VERSION ""

NS_ :

BS_:

BU_: BMS ECC EVBUS_Virtual_ECU GW OBC VCU

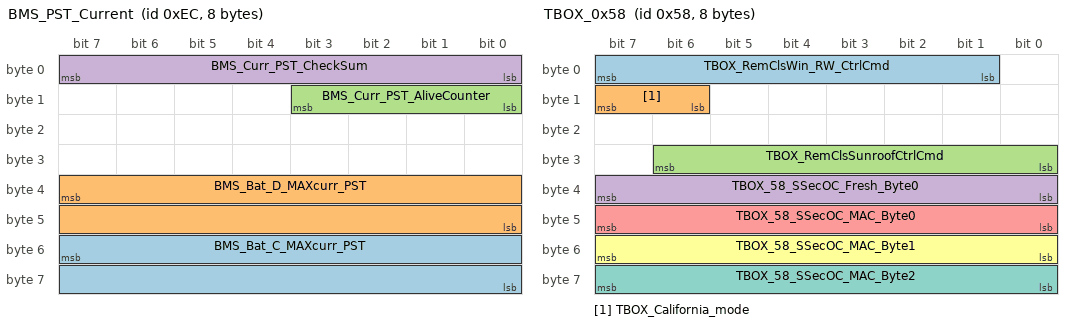
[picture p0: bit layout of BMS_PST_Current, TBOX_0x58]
BO_ 236 BMS_PST_Current: 8 BMS
 SG_ BMS_Bat_C_MAXcurr_PST : 55|16@0+ (0.05,0) [0|3276.75] "A"  VCU,GW
 SG_ BMS_Bat_D_MAXcurr_PST : 39|16@0+ (0.05,0) [0|3276.75] "A"  VCU,GW
 SG_ BMS_Curr_PST_AliveCounter : 11|4@0+ (1,0) [0|14] ""  VCU,GW
 SG_ BMS_Curr_PST_CheckSum : 7|8@0+ (1,0) [0|255] ""  VCU,GW

BO_ 54 TBOX_0x36: 8 GW
 SG_ TBOX_RemSeekCarCtrlCmd : 3|2@0+ (1,0) [0|3] ""  EVBUS_Virtual_ECU
 SG_ TBOX_RemClsTrCmd : 9|2@0+ (1,0) [0|3] ""  EVBUS_Virtual_ECU
 SG_ TBOX_RemDrvrSeatVentnCmd : 12|3@0+ (1,0) [0|7] ""  EVBUS_Virtual_ECU
 SG_ TBOX_RemDrvrSeatHeatgCmd : 15|3@0+ (1,0) [0|7] ""  EVBUS_Virtual_ECU
 SG_ TBOX_RemSetWelFct : 17|2@0+ (1,0) [0|3] ""  EVBUS_Virtual_ECU
 SG_ TBOX_RemPassSeatVentnCmd : 20|3@0+ (1,0) [0|7] ""  EVBUS_Virtual_ECU
 SG_ TBOX_RemPassSeatHeatgCmd : 23|3@0+ (1,0) [0|7] ""  EVBUS_Virtual_ECU
 SG_ TBOX_ClsAVMFct_ICC : 27|1@0+ (1,0) [0|1] ""  EVBUS_Virtual_ECU
 SG_ TBOX_ClsRemAVMFct_AVAP : 28|1@0+ (1,0) [0|1] ""  EVBUS_Virtual_ECU
 SG_ TBOX_RemSetFolwMeFct_BCM : 31|3@0+ (1,0) [0|7] ""  EVBUS_Virtual_ECU
 SG_ TBOX_RemSetCtrlLockFct_PKC : 33|2@0+ (1,0) [0|3] ""  EVBUS_Virtual_ECU
 SG_ TBOX_RemSetKickSnsrFct : 35|2@0+ (1,0) [0|3] ""  EVBUS_Virtual_ECU
 SG_ TBOX_VideoCtrlReq : 38|3@0+ (1,0) [0|7] ""  EVBUS_Virtual_ECU
 SG_ TBOX_VoiceBlowerLimReq : 39|1@0+ (1,0) [0|1] ""  ECC
 SG_ TBOX_RemCtrlCmdFb : 41|2@0+ (1,0) [0|3] ""  EVBUS_Virtual_ECU
 SG_ TBOX_CtrlReMirrReq : 43|2@0+ (1,0) [0|3] ""  EVBUS_Virtual_ECU
 SG_ TBOX_eCallMuteSt : 45|2@0+ (1,0) [0|3] ""  EVBUS_Virtual_ECU
 SG_ TBOX_RemReScrnHeatgCmd : 47|2@0+ (1,0) [0|3] ""  EVBUS_Virtual_ECU
 SG_ TBOX_eCallSt : 58|3@0+ (1,0) [0|7] ""  EVBUS_Virtual_ECU

BO_ 88 TBOX_0x58: 8 GW
 SG_ TBOX_RemClsWin_RW_CtrlCmd : 7|7@0+ (1,0) [0|100] "%"  EVBUS_Virtual_ECU
 SG_ TBOX_California_mode : 15|2@0+ (1,0) [0|3] ""  ECC
 SG_ TBOX_RemClsSunroofCtrlCmd : 30|7@0+ (1,0) [0|100] "%"  EVBUS_Virtual_ECU
 SG_ TBOX_58_SSecOC_Fresh_Byte0 : 39|8@0+ (1,0) [0|255] ""  EVBUS_Virtual_ECU
 SG_ TBOX_58_SSecOC_MAC_Byte0 : 47|8@0+ (1,0) [0|255] ""  EVBUS_Virtual_ECU
 SG_ TBOX_58_SSecOC_MAC_Byte1 : 55|8@0+ (1,0) [0|255] ""  EVBUS_Virtual_ECU
 SG_ TBOX_58_SSecOC_MAC_Byte2 : 63|8@0+ (1,0) [0|255] ""  EVBUS_Virtual_ECU

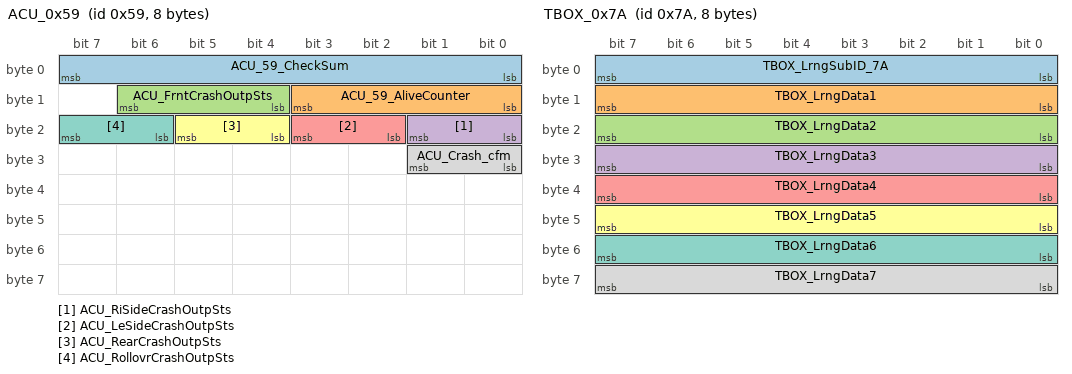
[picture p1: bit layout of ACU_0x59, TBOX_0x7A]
BO_ 89 ACU_0x59: 8 GW
 SG_ ACU_59_CheckSum : 7|8@0+ (1,0) [0|255] ""  BMS,ECC,OBC
 SG_ ACU_59_AliveCounter : 11|4@0+ (1,0) [0|14] ""  BMS,ECC,OBC
 SG_ ACU_FrntCrashOutpSts : 14|3@0+ (1,0) [0|7] ""  BMS,ECC,OBC
 SG_ ACU_RiSideCrashOutpSts : 17|2@0+ (1,0) [0|3] ""  BMS,ECC,OBC
 SG_ ACU_LeSideCrashOutpSts : 19|2@0+ (1,0) [0|3] ""  BMS,ECC,OBC
 SG_ ACU_RearCrashOutpSts : 21|2@0+ (1,0) [0|3] ""  BMS,ECC,OBC
 SG_ ACU_RollovrCrashOutpSts : 23|2@0+ (1,0) [0|3] ""  BMS,ECC,OBC
 SG_ ACU_Crash_cfm : 25|2@0+ (1,0) [0|3] ""  BMS,ECC,OBC

BO_ 121 TBOX_0x79: 8 GW
 SG_ TBOX_LrnFbInfoClassn : 7|8@0+ (1,0) [0|255] ""  EVBUS_Virtual_ECU
 SG_ TBOX_LrngSts : 15|8@0+ (1,0) [0|255] ""  EVBUS_Virtual_ECU

BO_ 122 TBOX_0x7A: 8 GW
 SG_ TBOX_LrngSubID_7A : 7|8@0+ (1,0) [0|255] ""  EVBUS_Virtual_ECU
 SG_ TBOX_LrngData1 : 15|8@0+ (1,0) [0|255] ""  EVBUS_Virtual_ECU
 SG_ TBOX_LrngData2 : 23|8@0+ (1,0) [0|255] ""  EVBUS_Virtual_ECU
 SG_ TBOX_LrngData3 : 31|8@0+ (1,0) [0|255] ""  EVBUS_Virtual_ECU
 SG_ TBOX_LrngData4 : 39|8@0+ (1,0) [0|255] ""  EVBUS_Virtual_ECU
 SG_ TBOX_LrngData5 : 47|8@0+ (1,0) [0|255] ""  EVBUS_Virtual_ECU
 SG_ TBOX_LrngData6 : 55|8@0+ (1,0) [0|255] ""  EVBUS_Virtual_ECU
 SG_ TBOX_LrngData7 : 63|8@0+ (1,0) [0|255] ""  EVBUS_Virtual_ECU

BO_ 147 VCU_0x93: 16 VCU
 SG_ VCU_93_CheckSum : 7|8@0+ (1,0) [0|255] ""  BMS,GW
 SG_ VCU_93_AliveCounter : 11|4@0+ (1,0) [0|14] ""  BMS,GW
 SG_ VCU_EmgyShutOff : 12|1@0+ (1,0) [0|1] ""  BMS,GW
 SG_ VCU_IsolationMonitor_Rq : 13|1@0+ (1,0) [0|1] ""  BMS,GW
 SG_ VCU_Set_Chrg_Mod : 19|4@0+ (1,0) [0|15] ""  BMS,GW
 SG_ VCU_Set_BMS_Mod : 23|4@0+ (1,0) [0|15] ""  BMS,GW
 SG_ VCU_HVBActivateDeactivateRq : 35|4@0+ (1,0) [0|15] ""  BMS,GW
 SG_ VCU_Set_Balc_Mod : 39|4@0+ (1,0) [0|15] ""  BMS,GW
 SG_ VCU_93_SSecOC_Fresh_Byte0 : 71|8@0+ (1,0) [0|255] ""  BMS,GW
 SG_ VCU_93_SSecOC_MAC_Byte0 : 79|8@0+ (1,0) [0|255] ""  BMS,GW
 SG_ VCU_93_SSecOC_MAC_Byte1 : 87|8@0+ (1,0) [0|255] ""  BMS,GW
 SG_ VCU_93_SSecOC_MAC_Byte2 : 95|8@0+ (1,0) [0|255] ""  BMS,GW

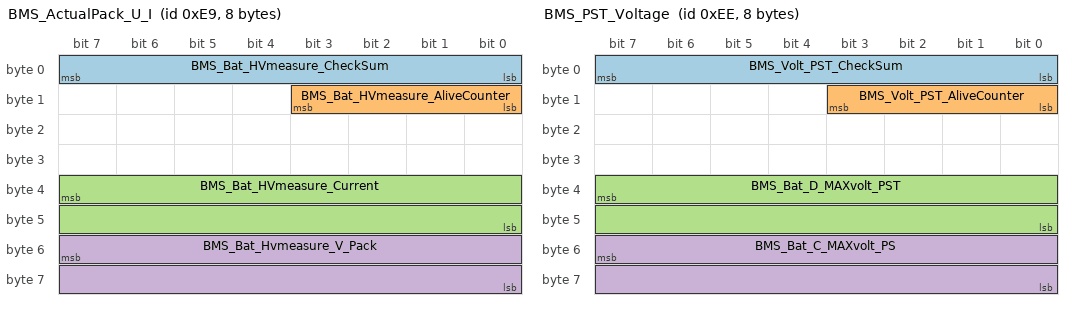
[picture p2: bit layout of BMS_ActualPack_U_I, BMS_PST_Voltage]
BO_ 233 BMS_ActualPack_U_I: 8 BMS
 SG_ BMS_Bat_HVmeasure_CheckSum : 7|8@0+ (1,0) [0|255] ""  GW,VCU
 SG_ BMS_Bat_HVmeasure_AliveCounter : 11|4@0+ (1,0) [0|14] ""  GW,VCU
 SG_ BMS_Bat_HVmeasure_Current : 39|16@0- (0.05,0) [-1250|1250] "A"  ECC,GW,VCU
 SG_ BMS_Bat_Hvmeasure_V_Pack : 55|16@0+ (0.01,0) [0|655.35] "V"  GW,VCU

BO_ 235 BMS_HVBatt_Status_Errors_1: 8 BMS
 SG_ BMS_Critical_Error_Flg_CheckSum : 7|8@0+ (1,0) [0|255] ""  GW,VCU
 SG_ BMS_Critical_Error_Flg_AliveCoun : 11|4@0+ (1,0) [0|14] ""  GW,VCU
 SG_ BMS_ErrorWarning_OverChargeCurre : 12|1@0+ (1,0) [0|1] ""  GW,VCU
 SG_ BMS_ErrorActive_OverChargeCurren : 13|1@0+ (1,0) [0|1] ""  GW,VCU
 SG_ BMS_ErrorWarning_OverDischargeCu : 14|1@0+ (1,0) [0|1] ""  GW,VCU
 SG_ BMS_ErrorActive_OverDischargeCur : 15|1@0+ (1,0) [0|1] ""  GW,VCU
 SG_ BMS_ErrorWarning_ChargePowerLimi : 16|1@0+ (1,0) [0|1] ""  GW,VCU
 SG_ BMS_ErrorActive_ChargePowerLimit : 17|1@0+ (1,0) [0|1] ""  GW,VCU
 SG_ BMS_ErrorWarning_DischargePowerL : 18|1@0+ (1,0) [0|1] ""  GW,VCU
 SG_ BMS_ErrorActive_DischargePowerLi : 19|1@0+ (1,0) [0|1] ""  GW,VCU
 SG_ BMS_ErrorWarning_SOC_Low : 20|1@0+ (1,0) [0|1] ""  GW,VCU
 SG_ BMS_ErrorActive_SOC_Low : 21|1@0+ (1,0) [0|1] ""  GW,VCU
 SG_ BMS_ErrorWarning_Iso : 22|1@0+ (1,0) [0|1] ""  GW,VCU
 SG_ BMS_ErrorActive_Iso_Crit : 23|1@0+ (1,0) [0|1] ""  GW,VCU
 SG_ BMS_ErrorActive_AbsChargeCurrent : 24|1@0+ (1,0) [0|1] ""  GW,VCU
 SG_ BMS_ErrorActive_AbsDischargeCurr : 25|1@0+ (1,0) [0|1] ""  GW,VCU
 SG_ BMS_ErrorActive_AbsChargePowerLi : 26|1@0+ (1,0) [0|1] ""  GW,VCU
 SG_ BMS_ErrorActive_AbsDischargePowe : 27|1@0+ (1,0) [0|1] ""  GW,VCU
 SG_ BMS_ErrorWarning_overcurrent_Pre : 28|1@0+ (1,0) [0|1] ""  GW,VCU
 SG_ BMS_ErrorActive_ServState : 29|1@0+ (1,0) [0|1] ""  GW,VCU
 SG_ BMS_SystemError_KL30C : 30|1@0+ (1,0) [0|1] ""  GW,VCU
 SG_ BMS_SystemError_OmmissionOfKL15 : 31|1@0+ (1,0) [0|1] ""  GW,VCU
 SG_ BMS_SystemError_HV_Interlock : 32|1@0+ (1,0) [0|1] ""  GW,VCU
 SG_ BMS_SystemError_HV_Fuse : 33|1@0+ (1,0) [0|1] ""  GW,VCU
 SG_ BMS_CommError_CommFailure : 34|1@0+ (1,0) [0|1] ""  GW,VCU
 SG_ BMS_CommWarning_PEC_High : 35|1@0+ (1,0) [0|1] ""  GW,VCU
 SG_ BMS_CommError_PEC_High : 36|1@0+ (1,0) [0|1] ""  GW,VCU
 SG_ BMS_HVlinkError_VCU_Comm_Failure : 37|1@0+ (1,0) [0|1] ""  GW,VCU
 SG_ BMS_HVlinkError_Iso_Dev : 38|1@0+ (1,0) [0|1] ""  GW,VCU
 SG_ BMS_HVlinkError_Iso_Dig_Sig : 39|1@0+ (1,0) [0|1] ""  GW,VCU
 SG_ BMS_HVlinkError_ContactorWelded : 40|1@0+ (1,0) [0|1] ""  GW,VCU
 SG_ BMS_HVlinkError_HV_Interlock_Bad : 41|1@0+ (1,0) [0|1] ""  GW,VCU
 SG_ BMS_HardwareError_LCM_General_Fa : 42|1@0+ (1,0) [0|1] ""  GW,VCU
 SG_ BMS_SoftwareError_General_Failr : 43|1@0+ (1,0) [0|1] ""  GW,VCU
 SG_ BMS_ErrorWarning_CellOverVoltage : 44|1@0+ (1,0) [0|1] ""  GW,VCU
 SG_ BMS_ErrorActive_CellOverVoltage : 45|1@0+ (1,0) [0|1] ""  GW,VCU
 SG_ BMS_ErrorWarning_CellUnderVoltag : 46|1@0+ (1,0) [0|1] ""  GW,VCU
 SG_ BMS_ErrorActive_CellUnderVoltage : 47|1@0+ (1,0) [0|1] ""  GW,VCU
 SG_ BMS_ErrorWarning_CellTempHigh : 48|1@0+ (1,0) [0|1] ""  GW,VCU
 SG_ BMS_ErrorActive_CellTempHigh : 49|1@0+ (1,0) [0|1] ""  GW,VCU
 SG_ BMS_ErrorWarning_CellTempLow : 50|1@0+ (1,0) [0|1] ""  GW,VCU
 SG_ BMS_ErrorActive_CellTempLow : 51|1@0+ (1,0) [0|1] ""  GW,VCU
 SG_ BMS_ErrorWarning_HV_OverVoltage : 52|1@0+ (1,0) [0|1] ""  GW,VCU
 SG_ BMS_ErrorActive_HV_OverVoltage : 53|1@0+ (1,0) [0|1] ""  GW,VCU
 SG_ BMS_ErrorWarning_HV_UnderVoltage : 54|1@0+ (1,0) [0|1] ""  GW,VCU
 SG_ BMS_ErrorActive_HV_UnderVoltage : 55|1@0+ (1,0) [0|1] ""  GW,VCU
 SG_ BMS_PVIU_CANcommError : 56|1@0+ (1,0) [0|1] ""  GW,VCU

BO_ 237 BMS_HVBatt_Status_Overall: 8 BMS
 SG_ BMS_OverallStatus_CheckSum : 7|8@0+ (1,0) [0|255] ""  ECC,GW,VCU
 SG_ BMS_OverallStatus_AliveCounter : 11|4@0+ (1,0) [0|14] ""  ECC,GW,VCU
 SG_ BMS_OperationStates : 19|4@0+ (1,0) [0|15] ""  ECC,GW,VCU
 SG_ BMS_BallancingStatus : 23|4@0+ (1,0) [0|15] ""  ECC,GW,VCU
 SG_ BMS_ErrorCategory_CAT0 : 24|1@0+ (1,0) [0|1] ""  ECC,GW,VCU
 SG_ BMS_ErrorCategory_CAT1 : 25|1@0+ (1,0) [0|1] ""  ECC,GW,VCU
 SG_ BMS_ErrorCategory_CAT2 : 26|1@0+ (1,0) [0|1] ""  ECC,GW,VCU
 SG_ BMS_ErrorCategory_CAT3 : 27|1@0+ (1,0) [0|1] ""  ECC,GW,VCU
 SG_ BMS_ErrorCategory_CAT4 : 28|1@0+ (1,0) [0|1] ""  ECC,GW,VCU
 SG_ BMS_ErrorCategory_CAT5 : 29|1@0+ (1,0) [0|1] ""  ECC,GW,VCU
 SG_ BMS_ErrorCategory_CAT6 : 30|1@0+ (1,0) [0|1] ""  ECC,GW,VCU
 SG_ BMS_ErrorCategory_CAT7 : 31|1@0+ (1,0) [0|1] ""  ECC,GW,VCU
 SG_ BMS_ErrorCategory_CAT8 : 32|1@0+ (1,0) [0|1] ""  ECC,GW,VCU
 SG_ BMS_HardwareStatus_OK : 33|1@0+ (1,0) [0|1] ""  ECC,GW,VCU
 SG_ BMS_ErrorCategory_Mem_Empty : 34|1@0+ (1,0) [0|1] ""  ECC,GW,VCU
 SG_ BMS_ConfigurationStatus_OK : 35|1@0+ (1,0) [0|1] ""  ECC,GW,VCU
 SG_ BMS_MeasurementModules_OK : 36|1@0+ (1,0) [0|1] ""  ECC,GW,VCU
 SG_ BMS_BatteryGeneralStatus_OK : 37|1@0+ (1,0) [0|1] ""  ECC,GW,VCU
 SG_ BMS_SDIL_Sts : 38|1@0+ (1,0) [0|1] ""  ECC,GW,VCU
 SG_ BMS_CL30C_Sts : 39|1@0+ (1,0) [0|1] ""  ECC,GW,VCU
 SG_ BMS_CL15_Sts : 40|1@0+ (1,0) [0|1] ""  ECC,GW,VCU
 SG_ BMS_HVIL_OK : 41|1@0+ (1,0) [0|1] ""  ECC,GW,VCU
 SG_ BMS_HV_ContactorsStatus_OK : 42|1@0+ (1,0) [0|1] ""  ECC,GW,VCU
 SG_ BMS_SW_Status_OK : 43|1@0+ (1,0) [0|1] ""  ECC,GW,VCU
 SG_ BMS_CurrentSensor_OK : 44|1@0+ (1,0) [0|1] ""  ECC,GW,VCU
 SG_ BMS_IsolatoinStatus_OK : 45|1@0+ (1,0) [0|1] ""  ECC,GW,VCU
 SG_ BMS_StateMAchine_Status : 55|8@0+ (1,0) [0|255] ""  ECC,GW,OBC,VCU
 SG_ BMS_BDU_Status : 63|8@0+ (1,0) [0|255] ""  ECC,GW,VCU

BO_ 238 BMS_PST_Voltage: 8 BMS
 SG_ BMS_Volt_PST_CheckSum : 7|8@0+ (1,0) [0|255] ""  GW,VCU
 SG_ BMS_Volt_PST_AliveCounter : 11|4@0+ (1,0) [0|14] ""  GW,VCU
 SG_ BMS_Bat_D_MAXvolt_PST : 39|16@0+ (0.02,0) [0|1310.7] "V"  GW,VCU
 SG_ BMS_Bat_C_MAXvolt_PS : 55|16@0+ (0.02,0) [0|1310.7] "V"  GW,VCU

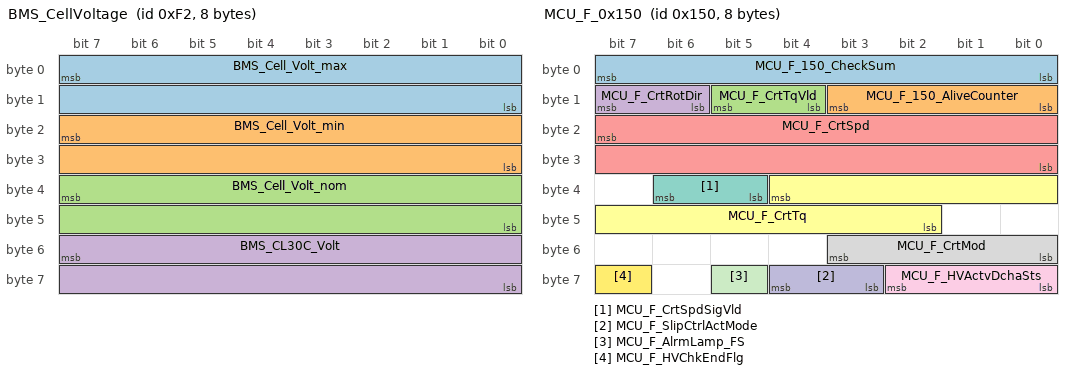
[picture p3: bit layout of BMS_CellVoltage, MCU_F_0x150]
BO_ 242 BMS_CellVoltage: 8 BMS
 SG_ BMS_Cell_Volt_max : 7|16@0+ (0.1,0) [0|6553.5] "mV"  GW,VCU
 SG_ BMS_Cell_Volt_min : 23|16@0+ (0.1,0) [0|6553.5] "mV"  GW,VCU
 SG_ BMS_Cell_Volt_nom : 39|16@0+ (0.1,0) [0|6553.5] "mV"  GW,VCU
 SG_ BMS_CL30C_Volt : 55|16@0+ (0.001,0) [0|65.534] "V"  GW

BO_ 336 MCU_F_0x150: 8 GW
 SG_ MCU_F_150_CheckSum : 7|8@0+ (1,0) [0|255] ""  ECC
 SG_ MCU_F_150_AliveCounter : 11|4@0+ (1,0) [0|14] ""  ECC
 SG_ MCU_F_CrtTqVld : 13|2@0+ (1,0) [0|3] ""  ECC
 SG_ MCU_F_CrtRotDir : 15|2@0+ (1,0) [0|3] ""  ECC
 SG_ MCU_F_CrtSpd : 23|16@0+ (1,-32768) [-32768|32767] "rpm"  BMS,ECC,OBC
 SG_ MCU_F_CrtTq : 36|11@0+ (0.5,-511) [-511|512] "Nm"  ECC
 SG_ MCU_F_CrtSpdSigVld : 38|2@0+ (1,0) [0|3] ""  BMS,ECC,OBC
 SG_ MCU_F_CrtMod : 51|4@0+ (1,0) [0|15] ""  ECC
 SG_ MCU_F_HVActvDchaSts : 58|3@0+ (1,0) [0|7] ""  ECC
 SG_ MCU_F_SlipCtrlActMode : 60|2@0+ (1,0) [0|3] ""  ECC
 SG_ MCU_F_AlrmLamp_FS : 61|1@0+ (1,0) [0|1] ""  ECC
 SG_ MCU_F_HVChkEndFlg : 63|1@0+ (1,0) [0|1] ""  ECC

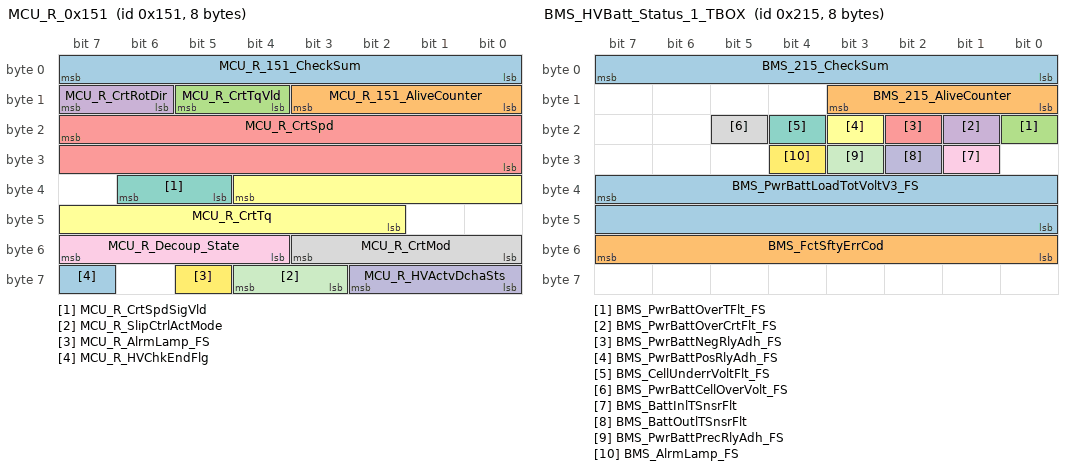
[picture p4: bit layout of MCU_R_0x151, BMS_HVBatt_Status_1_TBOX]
BO_ 337 MCU_R_0x151: 8 GW
 SG_ MCU_R_151_CheckSum : 7|8@0+ (1,0) [0|255] ""  ECC
 SG_ MCU_R_151_AliveCounter : 11|4@0+ (1,0) [0|14] ""  ECC
 SG_ MCU_R_CrtTqVld : 13|2@0+ (1,0) [0|3] ""  ECC
 SG_ MCU_R_CrtRotDir : 15|2@0+ (1,0) [0|3] ""  ECC
 SG_ MCU_R_CrtSpd : 23|16@0+ (1,-32768) [-32768|32767] "rpm"  BMS,ECC,OBC
 SG_ MCU_R_CrtTq : 36|11@0+ (0.5,-511) [-511|512] "Nm"  ECC
 SG_ MCU_R_CrtSpdSigVld : 38|2@0+ (1,0) [0|3] ""  BMS,ECC,OBC
 SG_ MCU_R_CrtMod : 51|4@0+ (1,0) [0|15] ""  ECC
 SG_ MCU_R_Decoup_State : 55|4@0+ (1,0) [0|15] ""  ECC
 SG_ MCU_R_HVActvDchaSts : 58|3@0+ (1,0) [0|7] ""  ECC
 SG_ MCU_R_SlipCtrlActMode : 60|2@0+ (1,0) [0|3] ""  ECC
 SG_ MCU_R_AlrmLamp_FS : 61|1@0+ (1,0) [0|1] ""  ECC
 SG_ MCU_R_HVChkEndFlg : 63|1@0+ (1,0) [0|1] ""  ECC

BO_ 533 BMS_HVBatt_Status_1_TBOX: 8 BMS
 SG_ BMS_215_CheckSum : 7|8@0+ (1,0) [0|255] ""  GW,VCU
 SG_ BMS_215_AliveCounter : 11|4@0+ (1,0) [0|14] ""  GW,VCU
 SG_ BMS_PwrBattOverTFlt_FS : 16|1@0+ (1,0) [0|1] ""  GW,VCU
 SG_ BMS_PwrBattOverCrtFlt_FS : 17|1@0+ (1,0) [0|1] ""  GW,VCU
 SG_ BMS_PwrBattNegRlyAdh_FS : 18|1@0+ (1,0) [0|1] ""  GW,VCU
 SG_ BMS_PwrBattPosRlyAdh_FS : 19|1@0+ (1,0) [0|1] ""  GW,VCU
 SG_ BMS_CellUnderrVoltFlt_FS : 20|1@0+ (1,0) [0|1] ""  GW,VCU
 SG_ BMS_PwrBattCellOverVolt_FS : 21|1@0+ (1,0) [0|1] ""  GW,VCU
 SG_ BMS_BattInlTSnsrFlt : 25|1@0+ (1,0) [0|1] ""  ECC,GW,VCU
 SG_ BMS_BattOutlTSnsrFlt : 26|1@0+ (1,0) [0|1] ""  ECC,GW,VCU
 SG_ BMS_PwrBattPrecRlyAdh_FS : 27|1@0+ (1,0) [0|1] ""  GW,VCU
 SG_ BMS_AlrmLamp_FS : 28|1@0+ (1,0) [0|1] ""  GW,VCU
 SG_ BMS_PwrBattLoadTotVoltV3_FS : 39|16@0+ (0.02,0) [0|1310.7] "V"  ECC,GW,VCU
 SG_ BMS_FctSftyErrCod : 55|8@0+ (1,0) [0|255] ""  GW

BO_ 608 VCU_0x260: 16 VCU
 SG_ VCU_260_269_CheckSum : 7|8@0+ (1,0) [0|255] ""  BMS,GW,OBC
 SG_ VCU_260_269_AliveCounter : 11|4@0+ (1,0) [0|14] ""  BMS,GW,OBC
 SG_ VCU_DCVoltCmd_OBC : 23|16@0+ (0.02,0) [0|1310.7] "V"  GW,OBC
 SG_ VCU_DCCrtCmd_OBC : 39|16@0+ (0.02,0) [0|1310.7] "A"  GW,OBC
 SG_ VCU_VehChrgDchgMod : 50|3@0+ (1,0) [0|7] ""  GW,OBC
 SG_ VCU_DCRlyCtrlCmd : 51|1@0+ (1,0) [0|1] ""  GW,OBC
 SG_ VCU_ChrgSysOperCmd : 58|3@0+ (1,0) [0|7] ""  GW,OBC
 SG_ VCU_ChrgSts : 63|3@0+ (1,0) [0|7] ""  BMS,GW,OBC
 SG_ VCU_260_SSecOC_Fresh_Byte0 : 71|8@0+ (1,0) [0|255] ""  GW,OBC
 SG_ VCU_260_SSecOC_MAC_Byte0 : 79|8@0+ (1,0) [0|255] ""  GW,OBC
 SG_ VCU_260_SSecOC_MAC_Byte1 : 87|8@0+ (1,0) [0|255] ""  GW,OBC
 SG_ VCU_260_SSecOC_MAC_Byte2 : 95|8@0+ (1,0) [0|255] ""  GW,OBC

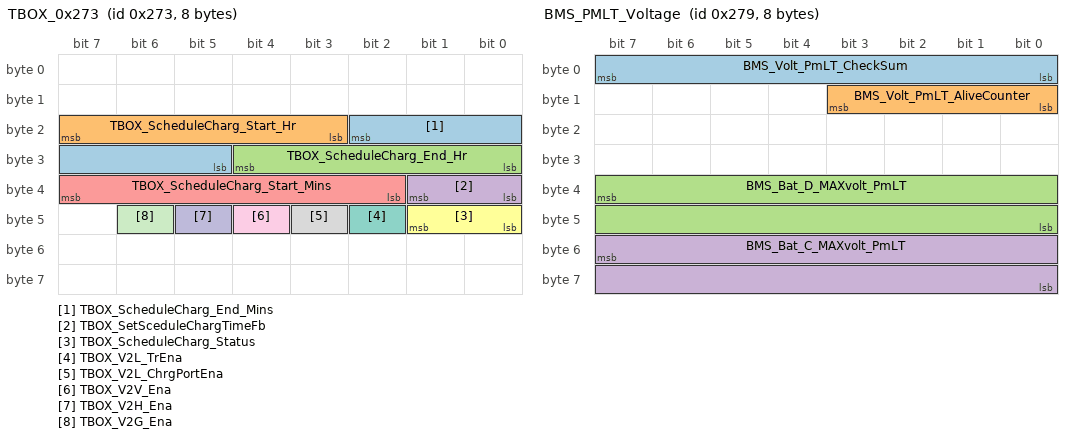
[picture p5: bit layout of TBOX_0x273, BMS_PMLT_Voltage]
BO_ 627 TBOX_0x273: 8 GW
 SG_ TBOX_ScheduleCharg_End_Mins : 18|6@0+ (1,0) [0|59] ""  EVBUS_Virtual_ECU
 SG_ TBOX_ScheduleCharg_Start_Hr : 23|5@0+ (1,0) [0|23] ""  EVBUS_Virtual_ECU
 SG_ TBOX_ScheduleCharg_End_Hr : 28|5@0+ (1,0) [0|23] ""  EVBUS_Virtual_ECU
 SG_ TBOX_SetSceduleChargTimeFb : 33|2@0+ (1,0) [0|3] ""  EVBUS_Virtual_ECU
 SG_ TBOX_ScheduleCharg_Start_Mins : 39|6@0+ (1,0) [0|59] ""  EVBUS_Virtual_ECU
 SG_ TBOX_ScheduleCharg_Status : 41|2@0+ (1,0) [0|3] ""  VCU
 SG_ TBOX_V2L_TrEna : 42|1@0+ (1,0) [0|1] ""  VCU
 SG_ TBOX_V2L_ChrgPortEna : 43|1@0+ (1,0) [0|1] ""  VCU
 SG_ TBOX_V2V_Ena : 44|1@0+ (1,0) [0|1] ""  VCU
 SG_ TBOX_V2H_Ena : 45|1@0+ (1,0) [0|1] ""  VCU
 SG_ TBOX_V2G_Ena : 46|1@0+ (1,0) [0|1] ""  VCU

BO_ 633 BMS_PMLT_Voltage: 8 BMS
 SG_ BMS_Volt_PmLT_CheckSum : 7|8@0+ (1,0) [0|255] ""  GW,VCU
 SG_ BMS_Volt_PmLT_AliveCounter : 11|4@0+ (1,0) [0|14] ""  GW,VCU
 SG_ BMS_Bat_D_MAXvolt_PmLT : 39|16@0+ (0.02,0) [0|1310.7] "V"  GW,VCU
 SG_ BMS_Bat_C_MAXvolt_PmLT : 55|16@0+ (0.02,0) [0|1310.7] "V"  GW,VCU

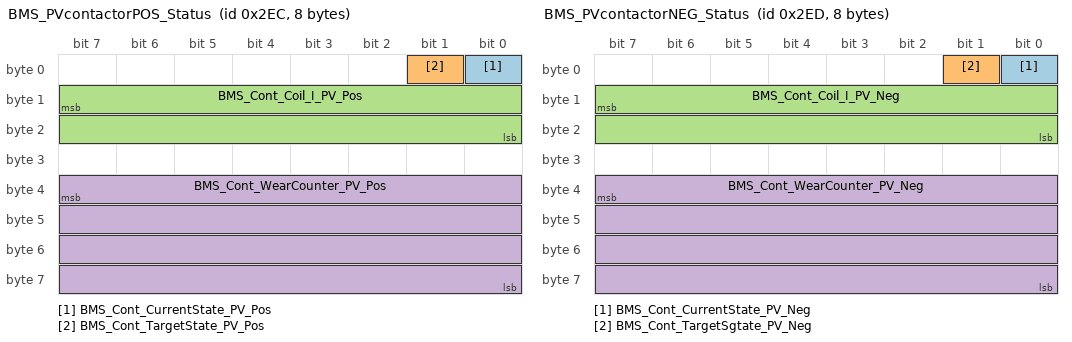
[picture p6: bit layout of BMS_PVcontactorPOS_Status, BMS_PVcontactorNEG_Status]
BO_ 748 BMS_PVcontactorPOS_Status: 8 BMS
 SG_ BMS_Cont_CurrentState_PV_Pos : 0|1@0+ (1,0) [0|1] ""  GW,VCU
 SG_ BMS_Cont_TargetState_PV_Pos : 1|1@0+ (1,0) [0|1] ""  GW
 SG_ BMS_Cont_Coil_I_PV_Pos : 15|16@0+ (0.08,0) [0|5242.8] "mA"  GW,VCU
 SG_ BMS_Cont_WearCounter_PV_Pos : 39|32@0+ (1,0) [0|4294967295] ""  GW,VCU

BO_ 749 BMS_PVcontactorNEG_Status: 8 BMS
 SG_ BMS_Cont_CurrentState_PV_Neg : 0|1@0+ (1,0) [0|1] ""  GW,VCU
 SG_ BMS_Cont_TargetSgtate_PV_Neg : 1|1@0+ (1,0) [0|1] ""  GW
 SG_ BMS_Cont_Coil_I_PV_Neg : 15|16@0+ (0.08,0) [0|5242.8] "mA"  GW,VCU
 SG_ BMS_Cont_WearCounter_PV_Neg : 39|32@0+ (1,0) [0|4294967295] ""  GW,VCU

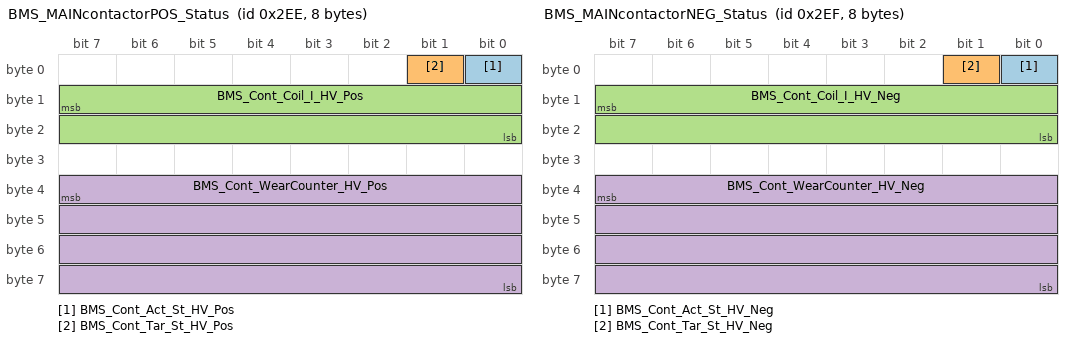
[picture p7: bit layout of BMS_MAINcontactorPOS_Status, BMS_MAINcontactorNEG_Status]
BO_ 750 BMS_MAINcontactorPOS_Status: 8 BMS
 SG_ BMS_Cont_Act_St_HV_Pos : 0|1@0+ (1,0) [0|1] ""  GW,VCU
 SG_ BMS_Cont_Tar_St_HV_Pos : 1|1@0+ (1,0) [0|1] ""  GW,VCU
 SG_ BMS_Cont_Coil_I_HV_Pos : 15|16@0+ (0.08,0) [0|5242.8] "mA"  GW,VCU
 SG_ BMS_Cont_WearCounter_HV_Pos : 39|32@0+ (1,0) [0|4294967295] ""  GW,VCU

BO_ 751 BMS_MAINcontactorNEG_Status: 8 BMS
 SG_ BMS_Cont_Act_St_HV_Neg : 0|1@0+ (1,0) [0|1] ""  GW,VCU
 SG_ BMS_Cont_Tar_St_HV_Neg : 1|1@0+ (1,0) [0|1] ""  GW,VCU
 SG_ BMS_Cont_Coil_I_HV_Neg : 15|16@0+ (0.08,0) [0|5242.8] "mA"  GW,VCU
 SG_ BMS_Cont_WearCounter_HV_Neg : 39|32@0+ (1,0) [0|4294967295] ""  GW,VCU

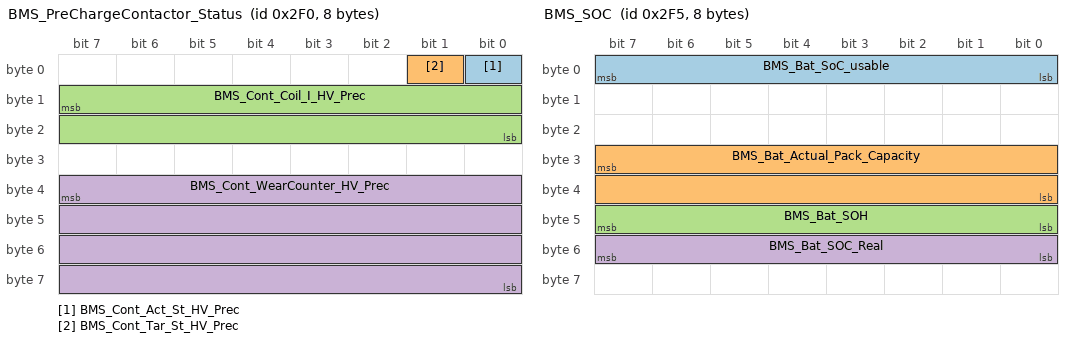
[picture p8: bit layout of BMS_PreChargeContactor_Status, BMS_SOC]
BO_ 752 BMS_PreChargeContactor_Status: 8 BMS
 SG_ BMS_Cont_Act_St_HV_Prec : 0|1@0+ (1,0) [0|1] ""  GW,VCU
 SG_ BMS_Cont_Tar_St_HV_Prec : 1|1@0+ (1,0) [0|1] ""  GW
 SG_ BMS_Cont_Coil_I_HV_Prec : 15|16@0+ (0.08,0) [0|5242.8] "mA"  GW,VCU
 SG_ BMS_Cont_WearCounter_HV_Prec : 39|32@0+ (1,0) [0|4294967295] ""  GW,VCU

BO_ 755 BMS_HVBatt_Status_Errors_2: 8 BMS
 SG_ BMS_Error_Flag_CheckSum : 7|8@0+ (1,0) [0|255] ""  GW,VCU
 SG_ BMS_Error_Flag_AliveCounter : 11|4@0+ (1,0) [0|14] ""  GW,VCU
 SG_ BMS_ErrorWarning_CellVoltageDiff : 12|1@0+ (1,0) [0|1] ""  GW,VCU
 SG_ BMS_ErrorActive_CellVoltageDiffO : 13|1@0+ (1,0) [0|1] ""  GW,VCU
 SG_ BMS_ErrorWarning_Diff_U1_UCellSu : 14|1@0+ (1,0) [0|1] ""  GW,VCU
 SG_ BMS_ErrorActive_Diff_U1_UCellSum : 15|1@0+ (1,0) [0|1] ""  GW,VCU
 SG_ BMS_ErrorWarning_SOH_Low : 16|1@0+ (1,0) [0|1] ""  GW,VCU
 SG_ BMS_ErrorActive_SOH_Low : 17|1@0+ (1,0) [0|1] ""  GW,VCU
 SG_ BMS_SystemError_SystemInitFailed : 18|1@0+ (1,0) [0|1] ""  GW,VCU
 SG_ BMS_SystemError_Precharge : 19|1@0+ (1,0) [0|1] ""  GW,VCU
 SG_ BMS_SystemError_HV_CCT_WrongPola : 20|1@0+ (1,0) [0|1] ""  GW,VCU
 SG_ BMS_SystemError_HV_CCT_NoBatVolt : 21|1@0+ (1,0) [0|1] ""  GW,VCU
 SG_ BMS_HVlinkWarning_VCU_MessageInt : 22|1@0+ (1,0) [0|1] ""  GW,VCU
 SG_ BMS_HVlinkError_IVT_Comm_Failure : 23|1@0+ (1,0) [0|1] ""  GW,VCU
 SG_ BMS_HVlinkWarning_IVT_Meas_Failu : 24|1@0+ (1,0) [0|1] ""  GW,VCU
 SG_ BMS_HVlinkError_IVT_Meas_Failure : 25|1@0+ (1,0) [0|1] ""  GW,VCU
 SG_ BMS_HVlinkError_NVM_Comm_Failure : 26|1@0+ (1,0) [0|1] ""  GW,VCU
 SG_ BMS_HVlinkWarning_Eeprom_LifeCyc : 27|1@0+ (1,0) [0|1] ""  GW,VCU
 SG_ BMS_HVlinkError_Eeprom_LifeCycle : 28|1@0+ (1,0) [0|1] ""  GW,VCU
 SG_ BMS_HVlinkError_ContactorGeneric : 29|1@0+ (1,0) [0|1] ""  GW,VCU
 SG_ BMS_HVlinkError_ContactorOpen : 30|1@0+ (1,0) [0|1] ""  GW,VCU
 SG_ BMS_HVlinkError_ContactorAuxFail : 31|1@0+ (1,0) [0|1] ""  GW,VCU
 SG_ BMS_HVlinkError_ContactorPwmEcon : 32|1@0+ (1,0) [0|1] ""  GW,VCU
 SG_ BMS_HVlinkWarning_AnalogInput_Ex : 33|1@0+ (1,0) [0|1] ""  GW,VCU
 SG_ BMS_HVlinkError_AnalogInput_Exce : 34|1@0+ (1,0) [0|1] ""  GW,VCU
 SG_ BMS_HWerror_KL30_Voltage : 35|1@0+ (1,0) [0|1] ""  GW,VCU
 SG_ BMS_HWerror_SD_Voltage : 36|1@0+ (1,0) [0|1] ""  GW,VCU
 SG_ BMS_HWerror_PCB_Temp_Sensor_Fail : 40|1@0+ (1,0) [0|1] ""  GW,VCU
 SG_ BMS_HWerror_Cell_Temp_Sensor_Fai : 41|1@0+ (1,0) [0|1] ""  GW,VCU
 SG_ BMS_HWwarning_LCM_PCB_OverTemp : 42|1@0+ (1,0) [0|1] ""  GW,VCU
 SG_ BMS_HWerror_LCM_PCB_OverTemp : 43|1@0+ (1,0) [0|1] ""  GW,VCU
 SG_ BMS_HWwarning_LCM_PCB_UnderTemp : 44|1@0+ (1,0) [0|1] ""  GW,VCU
 SG_ BMS_HWerror_LCM_PCB_UnderTemp : 45|1@0+ (1,0) [0|1] ""  GW,VCU
 SG_ BMS_Software_Error_Boot_Faild : 46|1@0+ (1,0) [0|1] ""  GW,VCU
 SG_ BMS_DTC_status : 55|16@0+ (1,0) [0|65535] ""  GW,VCU

BO_ 757 BMS_SOC: 8 BMS
 SG_ BMS_Bat_SoC_usable : 7|8@0+ (1,0) [0|100] "%"  GW,VCU
 SG_ BMS_Bat_Actual_Pack_Capacity : 31|16@0+ (0.01,0) [0|655.35] "kWh"  GW,VCU
 SG_ BMS_Bat_SOH : 47|8@0+ (1,0) [0|255] "%"  GW,VCU
 SG_ BMS_Bat_SOC_Real : 55|8@0+ (1,0) [0|100] "%"  GW

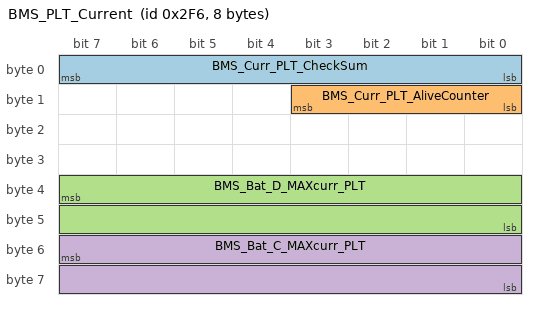
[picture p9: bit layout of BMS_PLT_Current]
BO_ 758 BMS_PLT_Current: 8 BMS
 SG_ BMS_Curr_PLT_CheckSum : 7|8@0+ (1,0) [0|255] ""  GW,VCU
 SG_ BMS_Curr_PLT_AliveCounter : 11|4@0+ (1,0) [0|14] ""  GW,VCU
 SG_ BMS_Bat_D_MAXcurr_PLT : 39|16@0+ (0.05,0) [0|3276.75] "A"  GW,VCU
 SG_ BMS_Bat_C_MAXcurr_PLT : 55|16@0+ (0.05,0) [0|3276.75] "A"  GW,VCU

CM_ SG_ 236 BMS_Bat_C_MAXcurr_PST "   predicted charge current for short time [10s value] When vehicle driving, this signal is used as a recharging (recuperation) current limit";
CM_ SG_ 236 BMS_Bat_D_MAXcurr_PST "predicted discharge current for short time [10s value]";
CM_ SG_ 236 BMS_Curr_PST_AliveCounter "Rolling counter";
CM_ SG_ 236 BMS_Curr_PST_CheckSum "CheckSum(E2E data ID: 0x2C)";
CM_ SG_ 54 TBOX_RemSeekCarCtrlCmd "Remote vehicle locating control command";
CM_ SG_ 54 TBOX_RemClsTrCmd "Close electric tail gate command remotely";
CM_ SG_ 54 TBOX_RemDrvrSeatVentnCmd "Remote driver seat ventilation command";
CM_ SG_ 54 TBOX_RemDrvrSeatHeatgCmd "Remote driver seat heating command";
CM_ SG_ 54 TBOX_RemSetWelFct "Remotely set opening and closing seat courtesy function and steering wheel courtesy function";
CM_ SG_ 54 TBOX_RemPassSeatVentnCmd "Remote passenger seat ventilation command";
CM_ SG_ 54 TBOX_RemPassSeatHeatgCmd "Remote passenger seat heating command";
CM_ SG_ 54 TBOX_ClsAVMFct_ICC "Turn off ICC remote panoramic function";
CM_ SG_ 54 TBOX_ClsRemAVMFct_AVAP "Turn off AVAP signal remote panoramic function";
CM_ SG_ 54 TBOX_RemSetFolwMeFct_BCM "Remotely set BCM follow me home function, headlamp delay off time";
CM_ SG_ 54 TBOX_RemSetCtrlLockFct_PKC "Remote setting opening and closing inductive PEPS unlocking function";
CM_ SG_ 54 TBOX_RemSetKickSnsrFct "Remote setting turns on and off the foot kick sensor function";
CM_ SG_ 54 TBOX_VideoCtrlReq "Video control request";
CM_ SG_ 54 TBOX_VoiceBlowerLimReq "Voice Blower Limit Rquest";
CM_ SG_ 54 TBOX_RemCtrlCmdFb "TBOX remote control command feedback
";
CM_ SG_ 54 TBOX_CtrlReMirrReq "Control rearview mirror request";
CM_ SG_ 54 TBOX_eCallMuteSt "Emergency Call Mute status";
CM_ SG_ 54 TBOX_RemReScrnHeatgCmd "Remote rear screen heating command";
CM_ SG_ 54 TBOX_eCallSt "eCall status";
CM_ SG_ 88 TBOX_58_SSecOC_Fresh_Byte0 "Short SecOC Fresh signal byte 0 on CAN";
CM_ SG_ 88 TBOX_58_SSecOC_MAC_Byte0 "Short SecOC MAC signal byte 0 on CAN";
CM_ SG_ 88 TBOX_58_SSecOC_MAC_Byte1 "Short SecOC MAC signal byte 1 on CAN";
CM_ SG_ 88 TBOX_58_SSecOC_MAC_Byte2 "Short SecOC MAC signal byte 2 on CAN";
CM_ SG_ 89 ACU_59_CheckSum "ACU_59_CheckSum (E2E data ID: 0x98) ";
CM_ SG_ 89 ACU_59_AliveCounter "ACU_0x59_Message counterACU_59_AliveCounter";
CM_ SG_ 89 ACU_FrntCrashOutpSts "Front Crash Status";
CM_ SG_ 89 ACU_RiSideCrashOutpSts "Right Side Crash Status";
CM_ SG_ 89 ACU_LeSideCrashOutpSts "Left Side Crash Status";
CM_ SG_ 89 ACU_RearCrashOutpSts "Rear Crash Status";
CM_ SG_ 89 ACU_RollovrCrashOutpSts "Rollover Crash Status";
CM_ SG_ 89 ACU_Crash_cfm "Crash confirm signal";
CM_ SG_ 121 TBOX_LrnFbInfoClassn "Classification of learning feedback information";
CM_ SG_ 121 TBOX_LrngSts "Tbox learning state";
CM_ SG_ 122 TBOX_LrngSubID_7A "Subfunction identification of learning response message";
CM_ SG_ 122 TBOX_LrngData1 "Learning data";
CM_ SG_ 122 TBOX_LrngData2 "Learning data";
CM_ SG_ 122 TBOX_LrngData3 "Learning data";
CM_ SG_ 122 TBOX_LrngData4 "Learning data";
CM_ SG_ 122 TBOX_LrngData5 "Learning data";
CM_ SG_ 122 TBOX_LrngData6 "Learning data";
CM_ SG_ 122 TBOX_LrngData7 "Learning data";
CM_ SG_ 147 VCU_93_CheckSum "CheckSum(E2E data ID: 0x24)";
CM_ SG_ 147 VCU_93_AliveCounter "Rolling counter";
CM_ SG_ 147 VCU_EmgyShutOff "Emergency shut down request from  VCU";
CM_ SG_ 147 VCU_IsolationMonitor_Rq "Request for isolation Monitoring";
CM_ SG_ 147 VCU_Set_Chrg_Mod "Set BMS to charging Modes";
CM_ SG_ 147 VCU_Set_BMS_Mod "Set BMS to different Modes";
CM_ SG_ 147 VCU_HVBActivateDeactivateRq "Close or open contactors to activate or deactivate HV";
CM_ SG_ 147 VCU_Set_Balc_Mod "Set BMS balancing mode ";
CM_ SG_ 147 VCU_93_SSecOC_Fresh_Byte0 "Short SecOC Fresh signal byte 0 on CAN";
CM_ SG_ 147 VCU_93_SSecOC_MAC_Byte0 "Short SecOC MAC signal byte 0 on CAN";
CM_ SG_ 147 VCU_93_SSecOC_MAC_Byte1 "Short SecOC MAC signal byte 1 on CAN";
CM_ SG_ 147 VCU_93_SSecOC_MAC_Byte2 "Short SecOC MAC signal byte 2 on CAN";
CM_ SG_ 233 BMS_Bat_HVmeasure_CheckSum "Message CheckSum(E2E data ID: 0x26)";
CM_ SG_ 233 BMS_Bat_HVmeasure_AliveCounter "Rolling counter";
CM_ SG_ 233 BMS_Bat_HVmeasure_Current "Values from IVT [A], actual current in HV circuit";
CM_ SG_ 233 BMS_Bat_Hvmeasure_V_Pack "Values from IVT [V], (U1) - Battery voltage";
CM_ SG_ 235 BMS_Critical_Error_Flg_CheckSum "CheckSum  (E2E data ID: 0x21)";
CM_ SG_ 235 BMS_Critical_Error_Flg_AliveCoun "Rolling counter";
CM_ SG_ 235 BMS_ErrorWarning_OverChargeCurre "Battery pack charge current is over the operational limit. The limit value can be calculated as   SOF current prediction value  - 5%";
CM_ SG_ 235 BMS_ErrorActive_OverChargeCurren "Battery pack charge current is over the safety limit. This limit value is calculated in the SOF algorithm and dynamically updated continuously. ";
CM_ SG_ 235 BMS_ErrorWarning_OverDischargeCu "Battery pack discharge current is over the operational limit.  The limit value can be calculated as   SOF current prediction  value - 5%";
CM_ SG_ 235 BMS_ErrorActive_OverDischargeCur "Battery pack discharge current is over the safety limit. This limit value is calculated in the SOF algorithm and dynamically updated continuously. ";
CM_ SG_ 235 BMS_ErrorWarning_ChargePowerLimi "HV system charge power is over the operational limit.  The limit value can be calculated as   SOF value - 5%";
CM_ SG_ 235 BMS_ErrorActive_ChargePowerLimit "HV system charge power is over the safety limit. This limit value is calculated in the SOF algorithm and dynamically updated continuously. ";
CM_ SG_ 235 BMS_ErrorWarning_DischargePowerL "HV system discharge power is over the operational limit.  The limit value can be calculated as   SOF value - 5%";
CM_ SG_ 235 BMS_ErrorActive_DischargePowerLi "HV system discharge power is over the safety limit.  This limit value is calculated in the SOF algorithm and dynamically updated continuously. ";
CM_ SG_ 235 BMS_ErrorWarning_SOC_Low "The currently measured SOC value has reached the warning threshold: SOC system limit ";
CM_ SG_ 235 BMS_ErrorActive_SOC_Low "Current measured SOC value is below of the minimum allowed system limit";
CM_ SG_ 235 BMS_ErrorWarning_Iso "Isolation resistance between HV+ and Ground, or HV- and Ground is under operational limit BMS_Bat_Iso_Warn";
CM_ SG_ 235 BMS_ErrorActive_Iso_Crit "Isolation resistance between HV+ and Ground, or HV- and Ground is under safety limit BMS_Bat_VehIso_Err";
CM_ SG_ 235 BMS_ErrorActive_AbsChargeCurrent "   HV system charge current has exceeded max system  limit";
CM_ SG_ 235 BMS_ErrorActive_AbsDischargeCurr "   HV system discharge current has exceeded max system  limit";
CM_ SG_ 235 BMS_ErrorActive_AbsChargePowerLi "HV system charge power has exceeded max system  limit";
CM_ SG_ 235 BMS_ErrorActive_AbsDischargePowe "HV system charge power has exceeded max system  limit";
CM_ SG_ 235 BMS_ErrorWarning_overcurrent_Pre "Actual HV battery charge or discharge current has exceed the threshold";
CM_ SG_ 235 BMS_ErrorActive_ServState "Service disconnect loop interrupted,  HW reaction will take 500ms BMS_Bat_ServState";
CM_ SG_ 235 BMS_SystemError_KL30C "(Rudimentary) crash signal occured, HW reaction will take 500ms";
CM_ SG_ 235 BMS_SystemError_OmmissionOfKL15 "The clam 15 was suddenly switched off in HV -ON state.";
CM_ SG_ 235 BMS_SystemError_HV_Interlock "HV interlock loop is interrupted, HW reaction will take 500ms";
CM_ SG_ 235 BMS_SystemError_HV_Fuse "The fuse after the contactors was fused due to a short circuit or because the circuit is not closed. This fault can be detected during initialization or in the HV-On state.";
CM_ SG_ 235 BMS_CommError_CommFailure "Communication failure to slave measuremnt modules";
CM_ SG_ 235 BMS_CommWarning_PEC_High "Warning package error count high (checksum)";
CM_ SG_ 235 BMS_CommError_PEC_High "Error package error count high (checksum)";
CM_ SG_ 235 BMS_HVlinkError_VCU_Comm_Failure "VCU_BMS_Control message wasn't received for longer than the VCU_HeartBeat Timeout value";
CM_ SG_ 235 BMS_HVlinkError_Iso_Dev " Status Device err or Kl.31 err.  BMS_Bat_ISO_ERR";
CM_ SG_ 235 BMS_HVlinkError_Iso_Dig_Sig "Device fault, earth connection fault, Undervoltage detected or device switched off BMS_Bat_IntIso_Err";
CM_ SG_ 235 BMS_HVlinkError_ContactorWelded "-A- HV contactor has been welded and no longer opens";
CM_ SG_ 235 BMS_HVlinkError_HV_Interlock_Bad "the PWM frequency or the duty cycle are outside the tolerance range.";
CM_ SG_ 235 BMS_HardwareError_LCM_General_Fa "General hardware error of the master board";
CM_ SG_ 235 BMS_SoftwareError_General_Failr "General software failure";
CM_ SG_ 235 BMS_ErrorWarning_CellOverVoltage "Cell voltage(s) reached over operational limit";
CM_ SG_ 235 BMS_ErrorActive_CellOverVoltage "Cell voltage(s) reached over safety limit";
CM_ SG_ 235 BMS_ErrorWarning_CellUnderVoltag "Cell voltage(s) reached under operational limit";
CM_ SG_ 235 BMS_ErrorActive_CellUnderVoltage "Cell voltage(s) reached under safety limit";
CM_ SG_ 235 BMS_ErrorWarning_CellTempHigh " Cell temperature sensor(s) readout reached over operational limits";
CM_ SG_ 235 BMS_ErrorActive_CellTempHigh " Cell temperature sensor(s) readout reached over safety limits";
CM_ SG_ 235 BMS_ErrorWarning_CellTempLow " Cell temperature sensor(s) readout reached under operational limits";
CM_ SG_ 235 BMS_ErrorActive_CellTempLow " Cell temperature sensor(s) readout reached under safety limits";
CM_ SG_ 235 BMS_ErrorWarning_HV_OverVoltage "U1 Measurement over operational limits";
CM_ SG_ 235 BMS_ErrorActive_HV_OverVoltage "U1 Measurement over safety limits";
CM_ SG_ 235 BMS_ErrorWarning_HV_UnderVoltage "U1 Measurement under operational limits";
CM_ SG_ 235 BMS_ErrorActive_HV_UnderVoltage "U1 Measurement outside limits";
CM_ SG_ 235 BMS_PVIU_CANcommError "PVIU CAN Communication Error status";
CM_ SG_ 237 BMS_OverallStatus_CheckSum "Checksum(E2E data ID: 0x22)";
CM_ SG_ 237 BMS_OverallStatus_AliveCounter "Rolling counter";
CM_ SG_ 237 BMS_OperationStates "BMS operational states";
CM_ SG_ 237 BMS_BallancingStatus "BMS balancing status";
CM_ SG_ 237 BMS_ErrorCategory_CAT0 "Escalation level of an error";
CM_ SG_ 237 BMS_ErrorCategory_CAT1 "Escalation level of an error";
CM_ SG_ 237 BMS_ErrorCategory_CAT2 "Escalation level of an error";
CM_ SG_ 237 BMS_ErrorCategory_CAT3 "Escalation level of an error";
CM_ SG_ 237 BMS_ErrorCategory_CAT4 "Escalation level of an error";
CM_ SG_ 237 BMS_ErrorCategory_CAT5 "Escalation level of an error";
CM_ SG_ 237 BMS_ErrorCategory_CAT6 "Escalation level of an error";
CM_ SG_ 237 BMS_ErrorCategory_CAT7 "Escalation level of an error";
CM_ SG_ 237 BMS_ErrorCategory_CAT8 "Escalation level of an error";
CM_ SG_ 237 BMS_HardwareStatus_OK "BMS Hardware OK Flag, Internal Temp. And and Voltages are okey";
CM_ SG_ 237 BMS_ErrorCategory_Mem_Empty "BMS Error memory is empty and OK";
CM_ SG_ 237 BMS_ConfigurationStatus_OK "BMS Configuration was successful";
CM_ SG_ 237 BMS_MeasurementModules_OK "BMS Measurement Modules OK";
CM_ SG_ 237 BMS_BatteryGeneralStatus_OK "BMS Battery status OK";
CM_ SG_ 237 BMS_SDIL_Sts "BMS Service Disconnect status";
CM_ SG_ 237 BMS_CL30C_Sts "BMS Clamp 30  status";
CM_ SG_ 237 BMS_CL15_Sts "BMS Clamp 15 status";
CM_ SG_ 237 BMS_HVIL_OK "BMS BMS HV Interlock OK";
CM_ SG_ 237 BMS_HV_ContactorsStatus_OK "BMS High Voltage / Main contactors OK";
CM_ SG_ 237 BMS_SW_Status_OK "BMS Algorithm status OK";
CM_ SG_ 237 BMS_CurrentSensor_OK "BMS IVT (Current Sensor) OK";
CM_ SG_ 237 BMS_IsolatoinStatus_OK "BMS Insolation and IMD OK ";
CM_ SG_ 237 BMS_StateMAchine_Status "Status of system state machine";
CM_ SG_ 237 BMS_BDU_Status "Status of battery disconnect unit";
CM_ SG_ 238 BMS_Volt_PST_CheckSum "CheckSum(E2E data ID: 0x2D)";
CM_ SG_ 238 BMS_Volt_PST_AliveCounter "Rolling counter";
CM_ SG_ 238 BMS_Bat_D_MAXvolt_PST "predicted discharge REESS voltage for short time [10s value]";
CM_ SG_ 238 BMS_Bat_C_MAXvolt_PS "predicted charge REESS voltage for short time [10s value]";
CM_ SG_ 242 BMS_Cell_Volt_max "The highest cell voltage of the battery pack [mV]";
CM_ SG_ 242 BMS_Cell_Volt_min "The lowest cell voltage of the battery pack [mV]";
CM_ SG_ 242 BMS_Cell_Volt_nom "Average cell voltage of the battery pack [mV]";
CM_ SG_ 242 BMS_CL30C_Volt "CL30C analog value in Volt ";
CM_ SG_ 336 MCU_F_150_CheckSum "Front MCU_150_Message checksum(E2E data ID: 0x29)";
CM_ SG_ 336 MCU_F_150_AliveCounter "MCU_150_Message Counter FrontMCU_F_150_AliveCounter";
CM_ SG_ 336 MCU_F_CrtTqVld "Effective torque of front drive motorMotorFTorquevalidflag";
CM_ SG_ 336 MCU_F_CrtRotDir "Current rotation direction of front drive motorMotorFRotingdirection";
CM_ SG_ 336 MCU_F_CrtSpd "Current speed of front drive motorMotorFSpeed";
CM_ SG_ 336 MCU_F_CrtTq "Current torque of front drive motorMotorFTorque";
CM_ SG_ 336 MCU_F_CrtSpdSigVld "Effective position of front drive motor current speed signalMotorFSpeedsignalvalidflag";
CM_ SG_ 336 MCU_F_CrtMod "Current operating mode of front drive motorMotorFworkingmode";
CM_ SG_ 336 MCU_F_HVActvDchaSts "High-voltage active discharge state of front MCUHVActiveDischargeState";
CM_ SG_ 336 MCU_F_SlipCtrlActMode "the Anti-Slip Control (ASC or ASR on german) state";
CM_ SG_ 336 MCU_F_AlrmLamp_FS "Warning lamp_front drive motor (functional safety)";
CM_ SG_ 336 MCU_F_HVChkEndFlg "High voltage detection completion flag of front MCUMCUFHVCheckStates";
CM_ SG_ 337 MCU_R_151_CheckSum "Rear MCU_151_Message checksum (E2E data ID: 0x34)";
CM_ SG_ 337 MCU_R_151_AliveCounter "Rear MCU_151_Message counterMCU_R_151_AliveCounter";
CM_ SG_ 337 MCU_R_CrtTqVld "Effective torque of rear drive motorMotorRTorquevalidflag";
CM_ SG_ 337 MCU_R_CrtRotDir "Current rotation direction of rear drive motorMotorRRotingdirection";
CM_ SG_ 337 MCU_R_CrtSpd "Current speed of rear drive motorMotorRSpeed";
CM_ SG_ 337 MCU_R_CrtTq "Current torque of rear drive motorMotorRTorque";
CM_ SG_ 337 MCU_R_CrtSpdSigVld "Effective position of current speed signal of rear drive motorMotorRSpeedsignalvalidflag";
CM_ SG_ 337 MCU_R_CrtMod "Current working mode of rear drive motorMotorRworkingmode";
CM_ SG_ 337 MCU_R_Decoup_State "Disconnect status";
CM_ SG_ 337 MCU_R_HVActvDchaSts "High-voltage active discharge state of rear MCUHVActiveDischargeState";
CM_ SG_ 337 MCU_R_SlipCtrlActMode "the Anti-Slip Control (ASC or ASR on german) state";
CM_ SG_ 337 MCU_R_AlrmLamp_FS "Warning lamp_rear drive motor (functional safety)";
CM_ SG_ 337 MCU_R_HVChkEndFlg "High voltage detection completion flag of rear drive motor controllerMCURHVCheckStates";
CM_ SG_ 533 BMS_215_CheckSum "BMS_215_Message checksum( E2E data ID: 0x13)";
CM_ SG_ 533 BMS_215_AliveCounter "BMS_215 _Message counterBMS_215_AliveCounter";
CM_ SG_ 533 BMS_PwrBattOverTFlt_FS "Power battery temperature too high (functional safety)";
CM_ SG_ 533 BMS_PwrBattOverCrtFlt_FS "Power battery overcurrent fault (functional safety)";
CM_ SG_ 533 BMS_PwrBattNegRlyAdh_FS "Connection of relay at negative terminal of traction battery (functional safety)";
CM_ SG_ 533 BMS_PwrBattPosRlyAdh_FS "Traction battery positive terminal relay sticking (functional safety)";
CM_ SG_ 533 BMS_CellUnderrVoltFlt_FS "Single undervoltage fault (functional safety)";
CM_ SG_ 533 BMS_PwrBattCellOverVolt_FS "Power battery cell overvoltage (functional safety)";
CM_ SG_ 533 BMS_BattInlTSnsrFlt "Battery inlet water temperature sensor fault";
CM_ SG_ 533 BMS_BattOutlTSnsrFlt "Battery outlet water temperature sensor fault";
CM_ SG_ 533 BMS_PwrBattPrecRlyAdh_FS "Traction battery pre-charge relay blocking (functional safety)";
CM_ SG_ 533 BMS_AlrmLamp_FS "Warning lamp_BMS (functional safety)";
CM_ SG_ 533 BMS_PwrBattLoadTotVoltV3_FS "Total voltage of traction battery load end V3 (functional safety)";
CM_ SG_ 533 BMS_FctSftyErrCod "Functional safety fault codeFunctional safety code";
CM_ SG_ 608 VCU_260_269_CheckSum "VCU_260_269_CheckSum (E2E data ID: 0x5D) ";
CM_ SG_ 608 VCU_260_269_AliveCounter "VCU_260_269_AliveCounter";
CM_ SG_ 608 VCU_DCVoltCmd_OBC "DC terminal voltage command of on-board charger";
CM_ SG_ 608 VCU_DCCrtCmd_OBC "On-board charger DC terminal current command";
CM_ SG_ 608 VCU_VehChrgDchgMod "Vehicle charge and discharge mode";
CM_ SG_ 608 VCU_DCRlyCtrlCmd "DC charging relay control command";
CM_ SG_ 608 VCU_ChrgSysOperCmd "Operating instructions of charging system";
CM_ SG_ 608 VCU_ChrgSts "VCU charging status";
CM_ SG_ 608 VCU_260_SSecOC_Fresh_Byte0 "Short SecOC Fresh signal byte 0 on CAN";
CM_ SG_ 608 VCU_260_SSecOC_MAC_Byte0 "Short SecOC MAC signal byte 0 on CAN";
CM_ SG_ 608 VCU_260_SSecOC_MAC_Byte1 "Short SecOC MAC signal byte 1 on CAN";
CM_ SG_ 608 VCU_260_SSecOC_MAC_Byte2 "Short SecOC MAC signal byte 2 on CAN";
CM_ SG_ 627 TBOX_V2L_TrEna "TBOX_V2LTrunkEnable";
CM_ SG_ 627 TBOX_V2L_ChrgPortEna "TBOX_V2LChargePortEnable";
CM_ SG_ 627 TBOX_V2V_Ena "TBOX_V2VEnable";
CM_ SG_ 627 TBOX_V2H_Ena "TBOX_V2HEnable";
CM_ SG_ 627 TBOX_V2G_Ena "TBOX_V2GEnable";
CM_ SG_ 633 BMS_Volt_PmLT_CheckSum "CheckSum(E2E data ID: 0x53)";
CM_ SG_ 633 BMS_Volt_PmLT_AliveCounter "Rolling counter";
CM_ SG_ 633 BMS_Bat_D_MAXvolt_PmLT "predicted discharge REESS voltage for middle long time [30s value]";
CM_ SG_ 633 BMS_Bat_C_MAXvolt_PmLT "predicted charge REESS voltage for middle long time [30s value]";
CM_ SG_ 748 BMS_Cont_CurrentState_PV_Pos "Current State of the relay see Enum ContactorStatus";
CM_ SG_ 748 BMS_Cont_TargetState_PV_Pos "Desired state of the ralay  ";
CM_ SG_ 748 BMS_Cont_Coil_I_PV_Pos "Current flowing through the coil";
CM_ SG_ 748 BMS_Cont_WearCounter_PV_Pos "Switch counter";
CM_ SG_ 749 BMS_Cont_CurrentState_PV_Neg "Current State of the relay see Enum ContactorStatus";
CM_ SG_ 749 BMS_Cont_TargetSgtate_PV_Neg "Desired state of the ralay  ";
CM_ SG_ 749 BMS_Cont_Coil_I_PV_Neg "Current flowing through the coil";
CM_ SG_ 749 BMS_Cont_WearCounter_PV_Neg "Switch counter";
CM_ SG_ 750 BMS_Cont_Act_St_HV_Pos "Current State of the relay see Enum ContactorStatus";
CM_ SG_ 750 BMS_Cont_Tar_St_HV_Pos "Desired state of the ralay  ";
CM_ SG_ 750 BMS_Cont_Coil_I_HV_Pos "Current flowing through the coil";
CM_ SG_ 750 BMS_Cont_WearCounter_HV_Pos "Switch counter";
CM_ SG_ 751 BMS_Cont_Act_St_HV_Neg "Current State of the relay see Enum ContactorStatus";
CM_ SG_ 751 BMS_Cont_Tar_St_HV_Neg "Desired state of the ralay  ";
CM_ SG_ 751 BMS_Cont_Coil_I_HV_Neg "Current flowing through the coil";
CM_ SG_ 751 BMS_Cont_WearCounter_HV_Neg "Switch counter";
CM_ SG_ 752 BMS_Cont_Act_St_HV_Prec "Current State of the relay see Enum ContactorStatus";
CM_ SG_ 752 BMS_Cont_Tar_St_HV_Prec "Desired state of the ralay  ";
CM_ SG_ 752 BMS_Cont_Coil_I_HV_Prec "Current flowing through the coil";
CM_ SG_ 752 BMS_Cont_WearCounter_HV_Prec "Switch counter";
CM_ SG_ 755 BMS_Error_Flag_CheckSum "CheckSum(E2E data ID: 0xF3)";
CM_ SG_ 755 BMS_Error_Flag_AliveCounter "Rolling counter";
CM_ SG_ 755 BMS_ErrorWarning_CellVoltageDiff "Cell voltages are not homogenious and allowed maximum cell voltage difference is almost reached";
CM_ SG_ 755 BMS_ErrorActive_CellVoltageDiffO "Cell voltages are not homogenious and allowed maximum cell voltage difference is  reached";
CM_ SG_ 755 BMS_ErrorWarning_Diff_U1_UCellSu "Sum of all cell voltages differs from the measured voltage of IVT (U1)";
CM_ SG_ 755 BMS_ErrorActive_Diff_U1_UCellSum "Sum of all cell voltages differs from the measured voltage of IVT (U1)";
CM_ SG_ 755 BMS_ErrorWarning_SOH_Low "The currently measured SOH value has reached the warning threshold: SOH system limit ";
CM_ SG_ 755 BMS_ErrorActive_SOH_Low "Current measured SOH value is below of the minimum allowed system limit";
CM_ SG_ 755 BMS_SystemError_SystemInitFailed "There is any err while the initialization is done.";
CM_ SG_ 755 BMS_SystemError_Precharge "Precharge sequence failed because voltage after contactors is not equal to U1 +/-2V for 250ms after time";
CM_ SG_ 755 BMS_SystemError_HV_CCT_WrongPola "The battery volatge and current signes are wrong";
CM_ SG_ 755 BMS_SystemError_HV_CCT_NoBatVolt "No battery volatge measured during initialisation";
CM_ SG_ 755 BMS_HVlinkWarning_VCU_MessageInt "The content of the received VCU_BMS_Control message is not valid or undefined";
CM_ SG_ 755 BMS_HVlinkError_IVT_Comm_Failure "Messages of the IVT Sensor are lost or specific measurement channels (e.g current channel) aren't received in the defined cycle time.";
CM_ SG_ 755 BMS_HVlinkWarning_IVT_Meas_Failu "The sensor signals with specific err bits that the last received measurement results are faulty. This err will be reported when the warning threshold value has been reached";
CM_ SG_ 755 BMS_HVlinkError_IVT_Meas_Failure "IVT sensor no longer sends plausible values . This err is reported when the number of measurement errs exceeds the critical threshold. ";
CM_ SG_ 755 BMS_HVlinkError_NVM_Comm_Failure "The number of faulty write and read accesses to eeprom memory has reached the maximum allowed limit";
CM_ SG_ 755 BMS_HVlinkWarning_Eeprom_LifeCyc "The Eeeprom memory has almost reached the maximum number of write cycles.";
CM_ SG_ 755 BMS_HVlinkError_Eeprom_LifeCycle "The Eeeprom memory has reached the maximum number of write cycles.No further writing on Eeprom is Possible.";
CM_ SG_ 755 BMS_HVlinkError_ContactorGeneric "the life time of the contactor (number of close-open sequencies) has been reached  or number of disconnects under high currrent has exceeded the allowed limit for this contactor type";
CM_ SG_ 755 BMS_HVlinkError_ContactorOpen "-A- HV contactor is defective and no longer closes";
CM_ SG_ 755 BMS_HVlinkError_ContactorAuxFail "Auxilary feedback line of the contactor is defective";
CM_ SG_ 755 BMS_HVlinkError_ContactorPwmEcon "The chosen pwm value does not keep the contacts together.This err only applies to pwm operated contactors.";
CM_ SG_ 755 BMS_HVlinkWarning_AnalogInput_Ex "One of the analog inputs crossed its limit operational limit";
CM_ SG_ 755 BMS_HVlinkError_AnalogInput_Exce "One of the analog inputs crossed its limit safety limit";
CM_ SG_ 755 BMS_HWerror_KL30_Voltage "Voltage at KL30 + reminal is outside defined operational range";
CM_ SG_ 755 BMS_HWerror_SD_Voltage "Service disconnect loop voltage is outside of defined operational range";
CM_ SG_ 755 BMS_HWerror_PCB_Temp_Sensor_Fail "One or more pcb  temperature sensors at LMM module are faulty";
CM_ SG_ 755 BMS_HWerror_Cell_Temp_Sensor_Fai "One or more cell  temperature sensors  are faulty";
CM_ SG_ 755 BMS_HWwarning_LCM_PCB_OverTemp "Temperature sensor on the LCM has reached its overheating warning threshold.";
CM_ SG_ 755 BMS_HWerror_LCM_PCB_OverTemp "Temperature sensor on the LCM has reached its overheating  limit";
CM_ SG_ 755 BMS_HWwarning_LCM_PCB_UnderTemp "Temperature sensor on the LCM has reached its undercooling warning threshold.";
CM_ SG_ 755 BMS_HWerror_LCM_PCB_UnderTemp "Temperature sensor on the LCM has reached its undercooling limit";
CM_ SG_ 755 BMS_Software_Error_Boot_Faild "Boot process failed";
CM_ SG_ 755 BMS_DTC_status "BMS DTC status";
CM_ SG_ 757 BMS_Bat_SoC_usable "Usable SoC value output [%]";
CM_ SG_ 757 BMS_Bat_Actual_Pack_Capacity "Actual system capacity [kWh]";
CM_ SG_ 757 BMS_Bat_SOH "Actual aging [%]";
CM_ SG_ 757 BMS_Bat_SOC_Real "Real SOC of HV battery (%) ";
CM_ SG_ 758 BMS_Curr_PLT_CheckSum "CheckSum(E2E data ID: 0x82)";
CM_ SG_ 758 BMS_Curr_PLT_AliveCounter "Rolling counter";
CM_ SG_ 758 BMS_Bat_D_MAXcurr_PLT "predicted discharge current for long time [300s value]";
CM_ SG_ 758 BMS_Bat_C_MAXcurr_PLT "predicted charge current for long time [300s value]";
BA_DEF_ SG_  "sigExplanation" STRING ;
BA_DEF_ SG_  "sigConfig" STRING ;
BA_DEF_ SG_  "sigSecLevel" STRING ;
BA_DEF_ SG_  "GenSigSendType" ENUM  "Cyclic","OnWrite","OnWriteWithRepetition","OnChange","OnChangeWithRepetition","IfActive","IfActiveWithRepetition","NoSigSendType";
BA_DEF_ SG_  "GenSigInactiveValue" INT 0 0;
BA_DEF_ SG_  "GenSigStartValue" INT 0 0;
BA_DEF_ SG_  "GenSigCycleTime" INT 0 0;
BA_DEF_ BO_  "E2EP01DataId" INT 0 65535;
BA_DEF_ BO_  "E2EP01DataLength" INT 0 65535;
BA_DEF_ BO_  "GenMsgStartDelayTime" INT 0 65535;
BA_DEF_ BO_  "GenMsgILSupport" ENUM  "No","Yes";
BA_DEF_ BO_  "VFrameFormat" ENUM  "StandardCAN","ExtendedCAN","reserved","reserved","reserved","reserved","reserved","reserved","reserved","reserved","reserved","reserved","reserved","reserved","StandardCAN_FD","ExtendedCAN_FD";
BA_DEF_ BO_  "CANFD_BRS" ENUM  "0","1";
BA_DEF_ BO_  "GenMsgDelayTime" INT 0 0;
BA_DEF_ BO_  "GenMsgNrOfRepetition" INT 0 0;
BA_DEF_ BO_  "GenMsgCycleTimeFast" INT 0 0;
BA_DEF_ BO_  "SCP_FreshnessValueTxLength" INT 0 512;
BA_DEF_ BO_  "SCL_CryptographicMessageID" INT 0 65535;
BA_DEF_ BO_  "SCP_FreshnessValueLength" INT 0 512;
BA_DEF_ BO_  "SCP_FreshnessValueId" INT 0 65535;
BA_DEF_ BO_  "GenMsgCycleTime" INT 0 0;
BA_DEF_ BO_  "SCP_DataId" INT 0 65535;
BA_DEF_ BO_  "GenMsgSendType" ENUM  "Cyclic","NotUsed","NotUsed","NotUsed","NotUsed","NotUsed","NotUsed","IfActive","NoMsgSendType";
BA_DEF_ BO_  "SCP_AuthInfoTxLength" INT 0 512;
BA_DEF_ BO_  "SC_LinkPos" INT 0 65535;
BA_DEF_ BO_  "SC_Message" ENUM  "No","Yes","Yes, split message";
BA_DEF_ BU_  "NmCAN" INT 0 2;
BA_DEF_ BU_  "NmStationAddress" HEX 0 65535;
BA_DEF_ BU_  "NmNode" ENUM  "No","Yes";
BA_DEF_ BU_  "DiagStationAddress" HEX 0 255;
BA_DEF_ BU_  "ILUsed" ENUM  "No","Yes";
BA_DEF_ BU_  "NodeLayerModules" STRING ;
BA_DEF_ BU_  "NmAsrCanMsgCycleOffset" INT 0 65535;
BA_DEF_ BU_  "NmAsrCanMsgReducedTime" INT 320 640;
BA_DEF_ BU_  "NmAsrNode" ENUM  "No","Yes";
BA_DEF_ BU_  "NmAsrNodeIdentifier" HEX 0 255;
BA_DEF_  "BusType" STRING ;
BA_DEF_  "NmMessageCount" INT 0 255;
BA_DEF_  "NmBaseAddress" HEX 1024 2047;
BA_DEF_  "NmType" STRING ;
BA_DEF_  "BusBaudrate" INT 0 10000;
BA_DEF_  "DBName" STRING ;
BA_DEF_  "BusBaudateOther" INT 0 10000;
BA_DEF_  "E2EP01DataIdMode" ENUM  "all16Bit","alternating8Bit","lower8Bit","lower12Bit";
BA_DEF_  "BusBaudateData" INT 0 10000;
BA_DEF_  "NmAsrCanMsgCycleTime" INT 0 0;
BA_DEF_  "NmAsrBaseAddress" HEX 0 2047;
BA_DEF_  "E2EP01ProfileBehavior" ENUM  "PRE_R4_2","R4_2";
BA_DEF_  "NmAsrMessageCount" INT 1 256;
BA_DEF_  "E2EP01ProfileName" STRING ;
BA_DEF_  "NmAsrRepeatMessageTime" INT 0 65535;
BA_DEF_  "NmAsrTimeoutTime" INT 0 65535;
BA_DEF_  "NmAsrWaitBusSleepTime" INT 0 65535;
BA_DEF_ SG_  "SystemSignalLongSymbol" STRING ;
BA_DEF_REL_ BU_SG_REL_  "SC_Verification" ENUM  "No","Yes";
BA_DEF_DEF_  "sigExplanation" "";
BA_DEF_DEF_  "sigConfig" "";
BA_DEF_DEF_  "sigSecLevel" "";
BA_DEF_DEF_  "GenSigSendType" "Cyclic";
BA_DEF_DEF_  "GenSigInactiveValue" 0;
BA_DEF_DEF_  "GenSigStartValue" 0;
BA_DEF_DEF_  "GenSigCycleTime" 0;
BA_DEF_DEF_  "E2EP01DataId" 0;
BA_DEF_DEF_  "E2EP01DataLength" 0;
BA_DEF_DEF_  "GenMsgStartDelayTime" 0;
BA_DEF_DEF_  "GenMsgILSupport" "Yes";
BA_DEF_DEF_  "VFrameFormat" "StandardCAN";
BA_DEF_DEF_  "CANFD_BRS" "1";
BA_DEF_DEF_  "GenMsgDelayTime" 0;
BA_DEF_DEF_  "GenMsgNrOfRepetition" 0;
BA_DEF_DEF_  "GenMsgCycleTimeFast" 0;
BA_DEF_DEF_  "SCP_FreshnessValueTxLength" 0;
BA_DEF_DEF_  "SCL_CryptographicMessageID" 0;
BA_DEF_DEF_  "SCP_FreshnessValueLength" 0;
BA_DEF_DEF_  "SCP_FreshnessValueId" 0;
BA_DEF_DEF_  "GenMsgCycleTime" 0;
BA_DEF_DEF_  "SCP_DataId" 0;
BA_DEF_DEF_  "GenMsgSendType" "Cyclic";
BA_DEF_DEF_  "SCP_AuthInfoTxLength" 0;
BA_DEF_DEF_  "SC_LinkPos" 0;
BA_DEF_DEF_  "SC_Message" "No";
BA_DEF_DEF_  "NmCAN" 0;
BA_DEF_DEF_  "NmStationAddress" 0;
BA_DEF_DEF_  "NmNode" "No";
BA_DEF_DEF_  "DiagStationAddress" 0;
BA_DEF_DEF_  "ILUsed" "Yes";
BA_DEF_DEF_  "NodeLayerModules" "CANoeILNLVector.dll";
BA_DEF_DEF_  "NmAsrCanMsgCycleOffset" 0;
BA_DEF_DEF_  "NmAsrCanMsgReducedTime" 320;
BA_DEF_DEF_  "NmAsrNode" "No";
BA_DEF_DEF_  "NmAsrNodeIdentifier" 0;
BA_DEF_DEF_  "BusType" "CAN";
BA_DEF_DEF_  "NmMessageCount" 128;
BA_DEF_DEF_  "NmBaseAddress" 1024;
BA_DEF_DEF_  "NmType" "NmAsr";
BA_DEF_DEF_  "BusBaudrate" 500;
BA_DEF_DEF_  "DBName" "";
BA_DEF_DEF_  "BusBaudateOther" 500;
BA_DEF_DEF_  "E2EP01DataIdMode" "lower8Bit";
BA_DEF_DEF_  "BusBaudateData" 2;
BA_DEF_DEF_  "NmAsrCanMsgCycleTime" 640;
BA_DEF_DEF_  "NmAsrBaseAddress" 1024;
BA_DEF_DEF_  "E2EP01ProfileBehavior" "R4_2";
BA_DEF_DEF_  "NmAsrMessageCount" 128;
BA_DEF_DEF_  "E2EP01ProfileName" "PROFILE_01";
BA_DEF_DEF_  "NmAsrRepeatMessageTime" 3200;
BA_DEF_DEF_  "NmAsrTimeoutTime" 2000;
BA_DEF_DEF_  "NmAsrWaitBusSleepTime" 1500;
BA_DEF_DEF_REL_ "SC_Verification" "No";
BA_DEF_DEF_  "SystemSignalLongSymbol" "";
BA_ "NmAsrMessageCount" 64;
BA_ "BusBaudrate" 2000;
BA_ "NmMessageCount" 64;
BA_ "BusType" "CAN FD";
BA_ "DBName" "FM29_EVBUS_Matrix_CANFD_V3906";
BA_ "NmAsrNodeIdentifier" BU_ BMS 7;
BA_ "DiagStationAddress" BU_ BMS 233;
BA_ "NmStationAddress" BU_ BMS 7;
BA_ "NmAsrNodeIdentifier" BU_ ECC 19;
BA_ "NmAsrNode" BU_ ECC 1;
BA_ "NmAsrCanMsgReducedTime" BU_ ECC 367;
BA_ "NmAsrCanMsgCycleOffset" BU_ ECC 95;
BA_ "DiagStationAddress" BU_ ECC 248;
BA_ "NmNode" BU_ ECC 1;
BA_ "NmStationAddress" BU_ ECC 19;
BA_ "NmCAN" BU_ ECC 1;
BA_ "NmAsrNodeIdentifier" BU_ GW 54;
BA_ "NmAsrNode" BU_ GW 1;
BA_ "NmAsrCanMsgReducedTime" BU_ GW 455;
BA_ "NmAsrCanMsgCycleOffset" BU_ GW 270;
BA_ "NmNode" BU_ GW 1;
BA_ "NmStationAddress" BU_ GW 54;
BA_ "NmCAN" BU_ GW 1;
BA_ "NmAsrNodeIdentifier" BU_ OBC 6;
BA_ "DiagStationAddress" BU_ OBC 251;
BA_ "NmStationAddress" BU_ OBC 6;
BA_ "NmAsrNodeIdentifier" BU_ VCU 1;
BA_ "NmAsrNode" BU_ VCU 1;
BA_ "NmAsrCanMsgReducedTime" BU_ VCU 322;
BA_ "NmAsrCanMsgCycleOffset" BU_ VCU 5;
BA_ "DiagStationAddress" BU_ VCU 202;
BA_ "NmNode" BU_ VCU 1;
BA_ "NmStationAddress" BU_ VCU 1;
BA_ "NmCAN" BU_ VCU 1;
BA_ "E2EP01DataId" BO_ 236 44;
BA_ "E2EP01DataLength" BO_ 236 64;
BA_ "GenMsgCycleTime" BO_ 236 20;
BA_ "VFrameFormat" BO_ 236 14;
BA_ "GenMsgSendType" BO_ 54 8;
BA_ "GenMsgCycleTimeFast" BO_ 54 20;
BA_ "GenMsgNrOfRepetition" BO_ 54 3;
BA_ "GenMsgDelayTime" BO_ 54 20;
BA_ "VFrameFormat" BO_ 54 14;
BA_ "SC_Message" BO_ 88 1;
BA_ "SC_LinkPos" BO_ 88 32;
BA_ "SCP_AuthInfoTxLength" BO_ 88 24;
BA_ "SCP_DataId" BO_ 88 88;
BA_ "GenMsgCycleTime" BO_ 88 100;
BA_ "SCP_FreshnessValueId" BO_ 88 88;
BA_ "SCP_FreshnessValueLength" BO_ 88 64;
BA_ "SCL_CryptographicMessageID" BO_ 88 88;
BA_ "SCP_FreshnessValueTxLength" BO_ 88 8;
BA_ "GenMsgCycleTimeFast" BO_ 88 20;
BA_ "GenMsgNrOfRepetition" BO_ 88 3;
BA_ "GenMsgDelayTime" BO_ 88 30;
BA_ "GenMsgStartDelayTime" BO_ 88 30;
BA_ "VFrameFormat" BO_ 88 14;
BA_ "GenMsgCycleTime" BO_ 89 50;
BA_ "GenMsgCycleTimeFast" BO_ 89 10;
BA_ "GenMsgNrOfRepetition" BO_ 89 5;
BA_ "GenMsgDelayTime" BO_ 89 10;
BA_ "E2EP01DataLength" BO_ 89 64;
BA_ "E2EP01DataId" BO_ 89 152;
BA_ "VFrameFormat" BO_ 89 14;
BA_ "GenMsgSendType" BO_ 121 8;
BA_ "GenMsgCycleTimeFast" BO_ 121 20;
BA_ "GenMsgNrOfRepetition" BO_ 121 3;
BA_ "VFrameFormat" BO_ 121 14;
BA_ "GenMsgSendType" BO_ 122 8;
BA_ "GenMsgCycleTimeFast" BO_ 122 20;
BA_ "GenMsgNrOfRepetition" BO_ 122 3;
BA_ "VFrameFormat" BO_ 122 14;
BA_ "SC_Message" BO_ 147 1;
BA_ "SC_LinkPos" BO_ 147 64;
BA_ "SCP_AuthInfoTxLength" BO_ 147 24;
BA_ "SCP_DataId" BO_ 147 147;
BA_ "GenMsgCycleTime" BO_ 147 20;
BA_ "SCP_FreshnessValueId" BO_ 147 147;
BA_ "SCP_FreshnessValueLength" BO_ 147 64;
BA_ "SCL_CryptographicMessageID" BO_ 147 147;
BA_ "SCP_FreshnessValueTxLength" BO_ 147 8;
BA_ "E2EP01DataLength" BO_ 147 64;
BA_ "E2EP01DataId" BO_ 147 36;
BA_ "VFrameFormat" BO_ 147 14;
BA_ "GenMsgCycleTime" BO_ 233 20;
BA_ "E2EP01DataLength" BO_ 233 64;
BA_ "E2EP01DataId" BO_ 233 38;
BA_ "VFrameFormat" BO_ 233 14;
BA_ "GenMsgCycleTime" BO_ 235 20;
BA_ "E2EP01DataLength" BO_ 235 64;
BA_ "E2EP01DataId" BO_ 235 33;
BA_ "VFrameFormat" BO_ 235 14;
BA_ "GenMsgCycleTime" BO_ 237 20;
BA_ "E2EP01DataLength" BO_ 237 64;
BA_ "E2EP01DataId" BO_ 237 34;
BA_ "VFrameFormat" BO_ 237 14;
BA_ "GenMsgCycleTime" BO_ 238 20;
BA_ "E2EP01DataLength" BO_ 238 64;
BA_ "E2EP01DataId" BO_ 238 45;
BA_ "VFrameFormat" BO_ 238 14;
BA_ "GenMsgCycleTime" BO_ 242 50;
BA_ "VFrameFormat" BO_ 242 14;
BA_ "GenMsgCycleTime" BO_ 336 10;
BA_ "E2EP01DataLength" BO_ 336 64;
BA_ "E2EP01DataId" BO_ 336 41;
BA_ "VFrameFormat" BO_ 336 14;
BA_ "GenMsgCycleTime" BO_ 337 10;
BA_ "E2EP01DataLength" BO_ 337 64;
BA_ "E2EP01DataId" BO_ 337 52;
BA_ "VFrameFormat" BO_ 337 14;
BA_ "GenMsgCycleTime" BO_ 533 20;
BA_ "E2EP01DataLength" BO_ 533 64;
BA_ "E2EP01DataId" BO_ 533 19;
BA_ "VFrameFormat" BO_ 533 14;
BA_ "SC_Message" BO_ 608 1;
BA_ "SC_LinkPos" BO_ 608 64;
BA_ "SCP_AuthInfoTxLength" BO_ 608 24;
BA_ "SCP_DataId" BO_ 608 608;
BA_ "GenMsgCycleTime" BO_ 608 20;
BA_ "SCP_FreshnessValueId" BO_ 608 608;
BA_ "SCP_FreshnessValueLength" BO_ 608 64;
BA_ "SCL_CryptographicMessageID" BO_ 608 608;
BA_ "SCP_FreshnessValueTxLength" BO_ 608 8;
BA_ "E2EP01DataLength" BO_ 608 64;
BA_ "E2EP01DataId" BO_ 608 93;
BA_ "VFrameFormat" BO_ 608 14;
BA_ "GenMsgSendType" BO_ 627 8;
BA_ "GenMsgCycleTimeFast" BO_ 627 100;
BA_ "GenMsgNrOfRepetition" BO_ 627 3;
BA_ "VFrameFormat" BO_ 627 14;
BA_ "GenMsgCycleTime" BO_ 633 50;
BA_ "E2EP01DataLength" BO_ 633 64;
BA_ "E2EP01DataId" BO_ 633 83;
BA_ "VFrameFormat" BO_ 633 14;
BA_ "GenMsgCycleTime" BO_ 748 100;
BA_ "VFrameFormat" BO_ 748 14;
BA_ "GenMsgCycleTime" BO_ 749 100;
BA_ "VFrameFormat" BO_ 749 14;
BA_ "GenMsgCycleTime" BO_ 750 100;
BA_ "VFrameFormat" BO_ 750 14;
BA_ "GenMsgCycleTime" BO_ 751 100;
BA_ "VFrameFormat" BO_ 751 14;
BA_ "GenMsgCycleTime" BO_ 752 100;
BA_ "VFrameFormat" BO_ 752 14;
BA_ "GenMsgCycleTime" BO_ 755 100;
BA_ "E2EP01DataLength" BO_ 755 64;
BA_ "E2EP01DataId" BO_ 755 243;
BA_ "VFrameFormat" BO_ 755 14;
BA_ "GenMsgCycleTime" BO_ 757 100;
BA_ "VFrameFormat" BO_ 757 14;
BA_ "GenMsgCycleTime" BO_ 758 100;
BA_ "E2EP01DataLength" BO_ 758 64;
BA_ "E2EP01DataId" BO_ 758 130;
BA_ "VFrameFormat" BO_ 758 14;
BA_ "sigSecLevel" SG_ 236 BMS_Bat_C_MAXcurr_PST "null";
BA_ "sigConfig" SG_ 236 BMS_Bat_C_MAXcurr_PST "null";
BA_ "sigExplanation" SG_ 236 BMS_Bat_C_MAXcurr_PST "null";
BA_ "sigSecLevel" SG_ 236 BMS_Bat_D_MAXcurr_PST "null";
BA_ "sigConfig" SG_ 236 BMS_Bat_D_MAXcurr_PST "null";
BA_ "sigExplanation" SG_ 236 BMS_Bat_D_MAXcurr_PST "null";
BA_ "sigSecLevel" SG_ 236 BMS_Curr_PST_AliveCounter "null";
BA_ "sigConfig" SG_ 236 BMS_Curr_PST_AliveCounter "null";
BA_ "sigExplanation" SG_ 236 BMS_Curr_PST_AliveCounter "null";
BA_ "sigSecLevel" SG_ 236 BMS_Curr_PST_CheckSum "null";
BA_ "sigConfig" SG_ 236 BMS_Curr_PST_CheckSum "null";
BA_ "sigExplanation" SG_ 236 BMS_Curr_PST_CheckSum "null";
BA_ "GenSigSendType" SG_ 54 TBOX_RemSeekCarCtrlCmd 2;
BA_ "sigSecLevel" SG_ 54 TBOX_RemSeekCarCtrlCmd "null";
BA_ "sigConfig" SG_ 54 TBOX_RemSeekCarCtrlCmd "null";
BA_ "sigExplanation" SG_ 54 TBOX_RemSeekCarCtrlCmd "null";
BA_ "GenSigSendType" SG_ 54 TBOX_RemClsTrCmd 3;
BA_ "sigSecLevel" SG_ 54 TBOX_RemClsTrCmd "null";
BA_ "sigConfig" SG_ 54 TBOX_RemClsTrCmd "null";
BA_ "sigExplanation" SG_ 54 TBOX_RemClsTrCmd "null";
BA_ "GenSigSendType" SG_ 54 TBOX_RemDrvrSeatVentnCmd 3;
BA_ "sigSecLevel" SG_ 54 TBOX_RemDrvrSeatVentnCmd "null";
BA_ "sigConfig" SG_ 54 TBOX_RemDrvrSeatVentnCmd "null";
BA_ "sigExplanation" SG_ 54 TBOX_RemDrvrSeatVentnCmd "null";
BA_ "GenSigSendType" SG_ 54 TBOX_RemDrvrSeatHeatgCmd 3;
BA_ "sigSecLevel" SG_ 54 TBOX_RemDrvrSeatHeatgCmd "null";
BA_ "sigConfig" SG_ 54 TBOX_RemDrvrSeatHeatgCmd "null";
BA_ "sigExplanation" SG_ 54 TBOX_RemDrvrSeatHeatgCmd "null";
BA_ "GenSigSendType" SG_ 54 TBOX_RemSetWelFct 2;
BA_ "sigSecLevel" SG_ 54 TBOX_RemSetWelFct "null";
BA_ "sigConfig" SG_ 54 TBOX_RemSetWelFct "null";
BA_ "sigExplanation" SG_ 54 TBOX_RemSetWelFct "null";
BA_ "GenSigSendType" SG_ 54 TBOX_RemPassSeatVentnCmd 2;
BA_ "sigSecLevel" SG_ 54 TBOX_RemPassSeatVentnCmd "null";
BA_ "sigConfig" SG_ 54 TBOX_RemPassSeatVentnCmd "null";
BA_ "sigExplanation" SG_ 54 TBOX_RemPassSeatVentnCmd "null";
BA_ "GenSigSendType" SG_ 54 TBOX_RemPassSeatHeatgCmd 2;
BA_ "sigSecLevel" SG_ 54 TBOX_RemPassSeatHeatgCmd "null";
BA_ "sigConfig" SG_ 54 TBOX_RemPassSeatHeatgCmd "null";
BA_ "sigExplanation" SG_ 54 TBOX_RemPassSeatHeatgCmd "null";
BA_ "GenSigSendType" SG_ 54 TBOX_ClsAVMFct_ICC 2;
BA_ "sigSecLevel" SG_ 54 TBOX_ClsAVMFct_ICC "null";
BA_ "sigConfig" SG_ 54 TBOX_ClsAVMFct_ICC "null";
BA_ "sigExplanation" SG_ 54 TBOX_ClsAVMFct_ICC "null";
BA_ "GenSigSendType" SG_ 54 TBOX_ClsRemAVMFct_AVAP 2;
BA_ "sigSecLevel" SG_ 54 TBOX_ClsRemAVMFct_AVAP "null";
BA_ "sigConfig" SG_ 54 TBOX_ClsRemAVMFct_AVAP "null";
BA_ "sigExplanation" SG_ 54 TBOX_ClsRemAVMFct_AVAP "null";
BA_ "GenSigSendType" SG_ 54 TBOX_RemSetFolwMeFct_BCM 2;
BA_ "sigSecLevel" SG_ 54 TBOX_RemSetFolwMeFct_BCM "null";
BA_ "sigConfig" SG_ 54 TBOX_RemSetFolwMeFct_BCM "null";
BA_ "sigExplanation" SG_ 54 TBOX_RemSetFolwMeFct_BCM "null";
BA_ "GenSigSendType" SG_ 54 TBOX_RemSetCtrlLockFct_PKC 2;
BA_ "sigSecLevel" SG_ 54 TBOX_RemSetCtrlLockFct_PKC "null";
BA_ "sigConfig" SG_ 54 TBOX_RemSetCtrlLockFct_PKC "null";
BA_ "sigExplanation" SG_ 54 TBOX_RemSetCtrlLockFct_PKC "null";
BA_ "GenSigSendType" SG_ 54 TBOX_RemSetKickSnsrFct 2;
BA_ "sigSecLevel" SG_ 54 TBOX_RemSetKickSnsrFct "null";
BA_ "sigConfig" SG_ 54 TBOX_RemSetKickSnsrFct "null";
BA_ "sigExplanation" SG_ 54 TBOX_RemSetKickSnsrFct "null";
BA_ "GenSigSendType" SG_ 54 TBOX_VideoCtrlReq 2;
BA_ "sigSecLevel" SG_ 54 TBOX_VideoCtrlReq "null";
BA_ "sigConfig" SG_ 54 TBOX_VideoCtrlReq "null";
BA_ "sigExplanation" SG_ 54 TBOX_VideoCtrlReq "null";
BA_ "GenSigSendType" SG_ 54 TBOX_VoiceBlowerLimReq 2;
BA_ "sigSecLevel" SG_ 54 TBOX_VoiceBlowerLimReq "null";
BA_ "sigConfig" SG_ 54 TBOX_VoiceBlowerLimReq "null";
BA_ "sigExplanation" SG_ 54 TBOX_VoiceBlowerLimReq "null";
BA_ "GenSigSendType" SG_ 54 TBOX_RemCtrlCmdFb 3;
BA_ "sigSecLevel" SG_ 54 TBOX_RemCtrlCmdFb "null";
BA_ "sigConfig" SG_ 54 TBOX_RemCtrlCmdFb "null";
BA_ "sigExplanation" SG_ 54 TBOX_RemCtrlCmdFb "null";
BA_ "GenSigSendType" SG_ 54 TBOX_CtrlReMirrReq 2;
BA_ "sigSecLevel" SG_ 54 TBOX_CtrlReMirrReq "null";
BA_ "sigConfig" SG_ 54 TBOX_CtrlReMirrReq "null";
BA_ "sigExplanation" SG_ 54 TBOX_CtrlReMirrReq "null";
BA_ "GenSigSendType" SG_ 54 TBOX_eCallMuteSt 2;
BA_ "sigSecLevel" SG_ 54 TBOX_eCallMuteSt "null";
BA_ "sigConfig" SG_ 54 TBOX_eCallMuteSt "null";
BA_ "sigExplanation" SG_ 54 TBOX_eCallMuteSt "null";
BA_ "GenSigSendType" SG_ 54 TBOX_RemReScrnHeatgCmd 2;
BA_ "GenSigSendType" SG_ 54 TBOX_eCallSt 2;
BA_ "sigSecLevel" SG_ 54 TBOX_eCallSt "null";
BA_ "sigConfig" SG_ 54 TBOX_eCallSt "null";
BA_ "sigExplanation" SG_ 54 TBOX_eCallSt "null";
BA_ "GenSigSendType" SG_ 88 TBOX_RemClsWin_RW_CtrlCmd 2;
BA_ "GenSigSendType" SG_ 88 TBOX_RemClsSunroofCtrlCmd 3;
BA_ "sigSecLevel" SG_ 88 TBOX_RemClsSunroofCtrlCmd "null";
BA_ "sigConfig" SG_ 88 TBOX_RemClsSunroofCtrlCmd "null";
BA_ "sigExplanation" SG_ 88 TBOX_RemClsSunroofCtrlCmd "null";
BA_ "sigSecLevel" SG_ 88 TBOX_58_SSecOC_Fresh_Byte0 "null";
BA_ "sigConfig" SG_ 88 TBOX_58_SSecOC_Fresh_Byte0 "null";
BA_ "sigExplanation" SG_ 88 TBOX_58_SSecOC_Fresh_Byte0 "null";
BA_ "sigSecLevel" SG_ 88 TBOX_58_SSecOC_MAC_Byte0 "null";
BA_ "sigConfig" SG_ 88 TBOX_58_SSecOC_MAC_Byte0 "null";
BA_ "sigExplanation" SG_ 88 TBOX_58_SSecOC_MAC_Byte0 "null";
BA_ "sigSecLevel" SG_ 88 TBOX_58_SSecOC_MAC_Byte1 "null";
BA_ "sigConfig" SG_ 88 TBOX_58_SSecOC_MAC_Byte1 "null";
BA_ "sigExplanation" SG_ 88 TBOX_58_SSecOC_MAC_Byte1 "null";
BA_ "sigSecLevel" SG_ 88 TBOX_58_SSecOC_MAC_Byte2 "null";
BA_ "sigConfig" SG_ 88 TBOX_58_SSecOC_MAC_Byte2 "null";
BA_ "sigExplanation" SG_ 88 TBOX_58_SSecOC_MAC_Byte2 "null";
BA_ "sigSecLevel" SG_ 89 ACU_59_CheckSum "null";
BA_ "sigConfig" SG_ 89 ACU_59_CheckSum "null";
BA_ "sigExplanation" SG_ 89 ACU_59_CheckSum "null";
BA_ "sigSecLevel" SG_ 89 ACU_59_AliveCounter "null";
BA_ "sigConfig" SG_ 89 ACU_59_AliveCounter "null";
BA_ "sigExplanation" SG_ 89 ACU_59_AliveCounter "null";
BA_ "GenSigSendType" SG_ 89 ACU_FrntCrashOutpSts 4;
BA_ "sigSecLevel" SG_ 89 ACU_FrntCrashOutpSts "A(D)";
BA_ "sigConfig" SG_ 89 ACU_FrntCrashOutpSts "null";
BA_ "sigExplanation" SG_ 89 ACU_FrntCrashOutpSts "null";
BA_ "GenSigSendType" SG_ 89 ACU_RiSideCrashOutpSts 4;
BA_ "sigSecLevel" SG_ 89 ACU_RiSideCrashOutpSts "A(D)";
BA_ "sigConfig" SG_ 89 ACU_RiSideCrashOutpSts "null";
BA_ "sigExplanation" SG_ 89 ACU_RiSideCrashOutpSts "null";
BA_ "GenSigSendType" SG_ 89 ACU_LeSideCrashOutpSts 4;
BA_ "sigSecLevel" SG_ 89 ACU_LeSideCrashOutpSts "A(D)";
BA_ "sigConfig" SG_ 89 ACU_LeSideCrashOutpSts "null";
BA_ "sigExplanation" SG_ 89 ACU_LeSideCrashOutpSts "null";
BA_ "GenSigSendType" SG_ 89 ACU_RearCrashOutpSts 4;
BA_ "sigSecLevel" SG_ 89 ACU_RearCrashOutpSts "A(D)";
BA_ "sigConfig" SG_ 89 ACU_RearCrashOutpSts "null";
BA_ "sigExplanation" SG_ 89 ACU_RearCrashOutpSts "null";
BA_ "GenSigSendType" SG_ 89 ACU_RollovrCrashOutpSts 4;
BA_ "sigSecLevel" SG_ 89 ACU_RollovrCrashOutpSts "A(D)";
BA_ "sigConfig" SG_ 89 ACU_RollovrCrashOutpSts "null";
BA_ "sigExplanation" SG_ 89 ACU_RollovrCrashOutpSts "null";
BA_ "GenSigSendType" SG_ 89 ACU_Crash_cfm 4;
BA_ "sigSecLevel" SG_ 89 ACU_Crash_cfm "A(D)";
BA_ "sigConfig" SG_ 89 ACU_Crash_cfm "null";
BA_ "sigExplanation" SG_ 89 ACU_Crash_cfm "null";
BA_ "GenSigSendType" SG_ 121 TBOX_LrnFbInfoClassn 2;
BA_ "sigSecLevel" SG_ 121 TBOX_LrnFbInfoClassn "null";
BA_ "sigConfig" SG_ 121 TBOX_LrnFbInfoClassn "null";
BA_ "sigExplanation" SG_ 121 TBOX_LrnFbInfoClassn "null";
BA_ "GenSigSendType" SG_ 121 TBOX_LrngSts 2;
BA_ "sigSecLevel" SG_ 121 TBOX_LrngSts "null";
BA_ "sigConfig" SG_ 121 TBOX_LrngSts "null";
BA_ "sigExplanation" SG_ 121 TBOX_LrngSts "null";
BA_ "GenSigSendType" SG_ 122 TBOX_LrngSubID_7A 2;
BA_ "sigSecLevel" SG_ 122 TBOX_LrngSubID_7A "null";
BA_ "sigConfig" SG_ 122 TBOX_LrngSubID_7A "null";
BA_ "sigExplanation" SG_ 122 TBOX_LrngSubID_7A "null";
BA_ "GenSigSendType" SG_ 122 TBOX_LrngData1 2;
BA_ "sigSecLevel" SG_ 122 TBOX_LrngData1 "null";
BA_ "sigConfig" SG_ 122 TBOX_LrngData1 "null";
BA_ "sigExplanation" SG_ 122 TBOX_LrngData1 "null";
BA_ "GenSigSendType" SG_ 122 TBOX_LrngData2 2;
BA_ "sigSecLevel" SG_ 122 TBOX_LrngData2 "null";
BA_ "sigConfig" SG_ 122 TBOX_LrngData2 "null";
BA_ "sigExplanation" SG_ 122 TBOX_LrngData2 "null";
BA_ "GenSigSendType" SG_ 122 TBOX_LrngData3 2;
BA_ "sigSecLevel" SG_ 122 TBOX_LrngData3 "null";
BA_ "sigConfig" SG_ 122 TBOX_LrngData3 "null";
BA_ "sigExplanation" SG_ 122 TBOX_LrngData3 "null";
BA_ "GenSigSendType" SG_ 122 TBOX_LrngData4 2;
BA_ "sigSecLevel" SG_ 122 TBOX_LrngData4 "null";
BA_ "sigConfig" SG_ 122 TBOX_LrngData4 "null";
BA_ "sigExplanation" SG_ 122 TBOX_LrngData4 "null";
BA_ "GenSigSendType" SG_ 122 TBOX_LrngData5 2;
BA_ "sigSecLevel" SG_ 122 TBOX_LrngData5 "null";
BA_ "sigConfig" SG_ 122 TBOX_LrngData5 "null";
BA_ "sigExplanation" SG_ 122 TBOX_LrngData5 "null";
BA_ "GenSigSendType" SG_ 122 TBOX_LrngData6 2;
BA_ "sigSecLevel" SG_ 122 TBOX_LrngData6 "null";
BA_ "sigConfig" SG_ 122 TBOX_LrngData6 "null";
BA_ "sigExplanation" SG_ 122 TBOX_LrngData6 "null";
BA_ "GenSigSendType" SG_ 122 TBOX_LrngData7 2;
BA_ "sigSecLevel" SG_ 122 TBOX_LrngData7 "null";
BA_ "sigConfig" SG_ 122 TBOX_LrngData7 "null";
BA_ "sigExplanation" SG_ 122 TBOX_LrngData7 "null";
BA_ "sigSecLevel" SG_ 147 VCU_93_CheckSum "null";
BA_ "sigConfig" SG_ 147 VCU_93_CheckSum "null";
BA_ "sigExplanation" SG_ 147 VCU_93_CheckSum "null";
BA_ "sigSecLevel" SG_ 147 VCU_93_AliveCounter "null";
BA_ "sigConfig" SG_ 147 VCU_93_AliveCounter "null";
BA_ "sigExplanation" SG_ 147 VCU_93_AliveCounter "null";
BA_ "sigSecLevel" SG_ 147 VCU_EmgyShutOff "null";
BA_ "sigConfig" SG_ 147 VCU_EmgyShutOff "null";
BA_ "sigExplanation" SG_ 147 VCU_EmgyShutOff "null";
BA_ "sigSecLevel" SG_ 147 VCU_IsolationMonitor_Rq "null";
BA_ "sigConfig" SG_ 147 VCU_IsolationMonitor_Rq "null";
BA_ "sigExplanation" SG_ 147 VCU_IsolationMonitor_Rq "null";
BA_ "sigSecLevel" SG_ 147 VCU_Set_Chrg_Mod "null";
BA_ "sigConfig" SG_ 147 VCU_Set_Chrg_Mod "null";
BA_ "sigExplanation" SG_ 147 VCU_Set_Chrg_Mod "null";
BA_ "sigSecLevel" SG_ 147 VCU_Set_BMS_Mod "null";
BA_ "sigConfig" SG_ 147 VCU_Set_BMS_Mod "null";
BA_ "sigExplanation" SG_ 147 VCU_Set_BMS_Mod "null";
BA_ "sigSecLevel" SG_ 147 VCU_HVBActivateDeactivateRq "null";
BA_ "sigConfig" SG_ 147 VCU_HVBActivateDeactivateRq "null";
BA_ "sigExplanation" SG_ 147 VCU_HVBActivateDeactivateRq "null";
BA_ "sigSecLevel" SG_ 147 VCU_Set_Balc_Mod "null";
BA_ "sigConfig" SG_ 147 VCU_Set_Balc_Mod "null";
BA_ "sigExplanation" SG_ 147 VCU_Set_Balc_Mod "null";
BA_ "sigSecLevel" SG_ 147 VCU_93_SSecOC_Fresh_Byte0 "null";
BA_ "sigConfig" SG_ 147 VCU_93_SSecOC_Fresh_Byte0 "null";
BA_ "sigExplanation" SG_ 147 VCU_93_SSecOC_Fresh_Byte0 "null";
BA_ "sigSecLevel" SG_ 147 VCU_93_SSecOC_MAC_Byte0 "null";
BA_ "sigConfig" SG_ 147 VCU_93_SSecOC_MAC_Byte0 "null";
BA_ "sigExplanation" SG_ 147 VCU_93_SSecOC_MAC_Byte0 "null";
BA_ "sigSecLevel" SG_ 147 VCU_93_SSecOC_MAC_Byte1 "null";
BA_ "sigConfig" SG_ 147 VCU_93_SSecOC_MAC_Byte1 "null";
BA_ "sigExplanation" SG_ 147 VCU_93_SSecOC_MAC_Byte1 "null";
BA_ "sigSecLevel" SG_ 147 VCU_93_SSecOC_MAC_Byte2 "null";
BA_ "sigConfig" SG_ 147 VCU_93_SSecOC_MAC_Byte2 "null";
BA_ "sigExplanation" SG_ 147 VCU_93_SSecOC_MAC_Byte2 "null";
BA_ "sigSecLevel" SG_ 233 BMS_Bat_HVmeasure_CheckSum "null";
BA_ "sigConfig" SG_ 233 BMS_Bat_HVmeasure_CheckSum "null";
BA_ "sigExplanation" SG_ 233 BMS_Bat_HVmeasure_CheckSum "null";
BA_ "sigSecLevel" SG_ 233 BMS_Bat_HVmeasure_AliveCounter "null";
BA_ "sigConfig" SG_ 233 BMS_Bat_HVmeasure_AliveCounter "null";
BA_ "sigExplanation" SG_ 233 BMS_Bat_HVmeasure_AliveCounter "null";
BA_ "sigSecLevel" SG_ 233 BMS_Bat_HVmeasure_Current "A(B)";
BA_ "sigConfig" SG_ 233 BMS_Bat_HVmeasure_Current "null";
BA_ "sigExplanation" SG_ 233 BMS_Bat_HVmeasure_Current "null";
BA_ "sigSecLevel" SG_ 233 BMS_Bat_Hvmeasure_V_Pack "null";
BA_ "sigConfig" SG_ 233 BMS_Bat_Hvmeasure_V_Pack "null";
BA_ "sigExplanation" SG_ 233 BMS_Bat_Hvmeasure_V_Pack "null";
BA_ "sigSecLevel" SG_ 235 BMS_Critical_Error_Flg_CheckSum "null";
BA_ "sigConfig" SG_ 235 BMS_Critical_Error_Flg_CheckSum "null";
BA_ "sigExplanation" SG_ 235 BMS_Critical_Error_Flg_CheckSum "null";
BA_ "sigSecLevel" SG_ 235 BMS_Critical_Error_Flg_AliveCoun "null";
BA_ "sigConfig" SG_ 235 BMS_Critical_Error_Flg_AliveCoun "null";
BA_ "sigExplanation" SG_ 235 BMS_Critical_Error_Flg_AliveCoun "null";
BA_ "SystemSignalLongSymbol" SG_ 235 BMS_Critical_Error_Flg_AliveCoun "BMS_Critical_Error_Flg_AliveCounter";
BA_ "sigSecLevel" SG_ 235 BMS_ErrorWarning_OverChargeCurre "null";
BA_ "sigConfig" SG_ 235 BMS_ErrorWarning_OverChargeCurre "null";
BA_ "sigExplanation" SG_ 235 BMS_ErrorWarning_OverChargeCurre "null";
BA_ "SystemSignalLongSymbol" SG_ 235 BMS_ErrorWarning_OverChargeCurre "BMS_ErrorWarning_OverChargeCurrent";
BA_ "sigSecLevel" SG_ 235 BMS_ErrorActive_OverChargeCurren "null";
BA_ "sigConfig" SG_ 235 BMS_ErrorActive_OverChargeCurren "null";
BA_ "sigExplanation" SG_ 235 BMS_ErrorActive_OverChargeCurren "null";
BA_ "SystemSignalLongSymbol" SG_ 235 BMS_ErrorActive_OverChargeCurren "BMS_ErrorActive_OverChargeCurrent";
BA_ "sigSecLevel" SG_ 235 BMS_ErrorWarning_OverDischargeCu "null";
BA_ "sigConfig" SG_ 235 BMS_ErrorWarning_OverDischargeCu "null";
BA_ "sigExplanation" SG_ 235 BMS_ErrorWarning_OverDischargeCu "null";
BA_ "SystemSignalLongSymbol" SG_ 235 BMS_ErrorWarning_OverDischargeCu "BMS_ErrorWarning_OverDischargeCurrent";
BA_ "sigSecLevel" SG_ 235 BMS_ErrorActive_OverDischargeCur "null";
BA_ "sigConfig" SG_ 235 BMS_ErrorActive_OverDischargeCur "null";
BA_ "sigExplanation" SG_ 235 BMS_ErrorActive_OverDischargeCur "null";
BA_ "SystemSignalLongSymbol" SG_ 235 BMS_ErrorActive_OverDischargeCur "BMS_ErrorActive_OverDischargeCurrent";
BA_ "sigSecLevel" SG_ 235 BMS_ErrorWarning_ChargePowerLimi "null";
BA_ "sigConfig" SG_ 235 BMS_ErrorWarning_ChargePowerLimi "null";
BA_ "sigExplanation" SG_ 235 BMS_ErrorWarning_ChargePowerLimi "null";
BA_ "SystemSignalLongSymbol" SG_ 235 BMS_ErrorWarning_ChargePowerLimi "BMS_ErrorWarning_ChargePowerLimitHit";
BA_ "sigSecLevel" SG_ 235 BMS_ErrorActive_ChargePowerLimit "null";
BA_ "sigConfig" SG_ 235 BMS_ErrorActive_ChargePowerLimit "null";
BA_ "sigExplanation" SG_ 235 BMS_ErrorActive_ChargePowerLimit "null";
BA_ "SystemSignalLongSymbol" SG_ 235 BMS_ErrorActive_ChargePowerLimit "BMS_ErrorActive_ChargePowerLimitHit";
BA_ "sigSecLevel" SG_ 235 BMS_ErrorWarning_DischargePowerL "null";
BA_ "sigConfig" SG_ 235 BMS_ErrorWarning_DischargePowerL "null";
BA_ "sigExplanation" SG_ 235 BMS_ErrorWarning_DischargePowerL "null";
BA_ "SystemSignalLongSymbol" SG_ 235 BMS_ErrorWarning_DischargePowerL "BMS_ErrorWarning_DischargePowerLimitHit";
BA_ "sigSecLevel" SG_ 235 BMS_ErrorActive_DischargePowerLi "null";
BA_ "sigConfig" SG_ 235 BMS_ErrorActive_DischargePowerLi "null";
BA_ "sigExplanation" SG_ 235 BMS_ErrorActive_DischargePowerLi "null";
BA_ "SystemSignalLongSymbol" SG_ 235 BMS_ErrorActive_DischargePowerLi "BMS_ErrorActive_DischargePowerLimitHit";
BA_ "sigSecLevel" SG_ 235 BMS_ErrorWarning_SOC_Low "null";
BA_ "sigConfig" SG_ 235 BMS_ErrorWarning_SOC_Low "null";
BA_ "sigExplanation" SG_ 235 BMS_ErrorWarning_SOC_Low "null";
BA_ "sigSecLevel" SG_ 235 BMS_ErrorActive_SOC_Low "null";
BA_ "sigConfig" SG_ 235 BMS_ErrorActive_SOC_Low "null";
BA_ "sigExplanation" SG_ 235 BMS_ErrorActive_SOC_Low "null";
BA_ "sigSecLevel" SG_ 235 BMS_ErrorWarning_Iso "null";
BA_ "sigConfig" SG_ 235 BMS_ErrorWarning_Iso "null";
BA_ "sigExplanation" SG_ 235 BMS_ErrorWarning_Iso "null";
BA_ "sigSecLevel" SG_ 235 BMS_ErrorActive_Iso_Crit "null";
BA_ "sigConfig" SG_ 235 BMS_ErrorActive_Iso_Crit "null";
BA_ "sigExplanation" SG_ 235 BMS_ErrorActive_Iso_Crit "null";
BA_ "sigSecLevel" SG_ 235 BMS_ErrorActive_AbsChargeCurrent "null";
BA_ "sigConfig" SG_ 235 BMS_ErrorActive_AbsChargeCurrent "null";
BA_ "sigExplanation" SG_ 235 BMS_ErrorActive_AbsChargeCurrent "null";
BA_ "SystemSignalLongSymbol" SG_ 235 BMS_ErrorActive_AbsChargeCurrent "BMS_ErrorActive_AbsChargeCurrentLim";
BA_ "sigSecLevel" SG_ 235 BMS_ErrorActive_AbsDischargeCurr "null";
BA_ "sigConfig" SG_ 235 BMS_ErrorActive_AbsDischargeCurr "null";
BA_ "sigExplanation" SG_ 235 BMS_ErrorActive_AbsDischargeCurr "null";
BA_ "SystemSignalLongSymbol" SG_ 235 BMS_ErrorActive_AbsDischargeCurr "BMS_ErrorActive_AbsDischargeCurrentLimitH";
BA_ "sigSecLevel" SG_ 235 BMS_ErrorActive_AbsChargePowerLi "null";
BA_ "sigConfig" SG_ 235 BMS_ErrorActive_AbsChargePowerLi "null";
BA_ "sigExplanation" SG_ 235 BMS_ErrorActive_AbsChargePowerLi "null";
BA_ "SystemSignalLongSymbol" SG_ 235 BMS_ErrorActive_AbsChargePowerLi "BMS_ErrorActive_AbsChargePowerLim";
BA_ "sigSecLevel" SG_ 235 BMS_ErrorActive_AbsDischargePowe "null";
BA_ "sigConfig" SG_ 235 BMS_ErrorActive_AbsDischargePowe "null";
BA_ "sigExplanation" SG_ 235 BMS_ErrorActive_AbsDischargePowe "null";
BA_ "SystemSignalLongSymbol" SG_ 235 BMS_ErrorActive_AbsDischargePowe "BMS_ErrorActive_AbsDischargePowerLimHit";
BA_ "sigSecLevel" SG_ 235 BMS_ErrorWarning_overcurrent_Pre "null";
BA_ "sigConfig" SG_ 235 BMS_ErrorWarning_overcurrent_Pre "null";
BA_ "sigExplanation" SG_ 235 BMS_ErrorWarning_overcurrent_Pre "null";
BA_ "SystemSignalLongSymbol" SG_ 235 BMS_ErrorWarning_overcurrent_Pre "BMS_ErrorWarning_overcurrent_Prewarn";
BA_ "sigSecLevel" SG_ 235 BMS_ErrorActive_ServState "null";
BA_ "sigConfig" SG_ 235 BMS_ErrorActive_ServState "null";
BA_ "sigExplanation" SG_ 235 BMS_ErrorActive_ServState "null";
BA_ "sigSecLevel" SG_ 235 BMS_SystemError_KL30C "null";
BA_ "sigConfig" SG_ 235 BMS_SystemError_KL30C "null";
BA_ "sigExplanation" SG_ 235 BMS_SystemError_KL30C "null";
BA_ "sigSecLevel" SG_ 235 BMS_SystemError_OmmissionOfKL15 "null";
BA_ "sigConfig" SG_ 235 BMS_SystemError_OmmissionOfKL15 "null";
BA_ "sigExplanation" SG_ 235 BMS_SystemError_OmmissionOfKL15 "null";
BA_ "sigSecLevel" SG_ 235 BMS_SystemError_HV_Interlock "null";
BA_ "sigConfig" SG_ 235 BMS_SystemError_HV_Interlock "null";
BA_ "sigExplanation" SG_ 235 BMS_SystemError_HV_Interlock "null";
BA_ "sigSecLevel" SG_ 235 BMS_SystemError_HV_Fuse "null";
BA_ "sigConfig" SG_ 235 BMS_SystemError_HV_Fuse "null";
BA_ "sigExplanation" SG_ 235 BMS_SystemError_HV_Fuse "null";
BA_ "sigSecLevel" SG_ 235 BMS_CommError_CommFailure "null";
BA_ "sigConfig" SG_ 235 BMS_CommError_CommFailure "null";
BA_ "sigExplanation" SG_ 235 BMS_CommError_CommFailure "null";
BA_ "sigSecLevel" SG_ 235 BMS_CommWarning_PEC_High "null";
BA_ "sigConfig" SG_ 235 BMS_CommWarning_PEC_High "null";
BA_ "sigExplanation" SG_ 235 BMS_CommWarning_PEC_High "null";
BA_ "sigSecLevel" SG_ 235 BMS_CommError_PEC_High "null";
BA_ "sigConfig" SG_ 235 BMS_CommError_PEC_High "null";
BA_ "sigExplanation" SG_ 235 BMS_CommError_PEC_High "null";
BA_ "sigSecLevel" SG_ 235 BMS_HVlinkError_VCU_Comm_Failure "null";
BA_ "sigConfig" SG_ 235 BMS_HVlinkError_VCU_Comm_Failure "null";
BA_ "sigExplanation" SG_ 235 BMS_HVlinkError_VCU_Comm_Failure "null";
BA_ "sigSecLevel" SG_ 235 BMS_HVlinkError_Iso_Dev "null";
BA_ "sigConfig" SG_ 235 BMS_HVlinkError_Iso_Dev "null";
BA_ "sigExplanation" SG_ 235 BMS_HVlinkError_Iso_Dev "null";
BA_ "sigSecLevel" SG_ 235 BMS_HVlinkError_Iso_Dig_Sig "null";
BA_ "sigConfig" SG_ 235 BMS_HVlinkError_Iso_Dig_Sig "null";
BA_ "sigExplanation" SG_ 235 BMS_HVlinkError_Iso_Dig_Sig "null";
BA_ "sigSecLevel" SG_ 235 BMS_HVlinkError_ContactorWelded "null";
BA_ "sigConfig" SG_ 235 BMS_HVlinkError_ContactorWelded "null";
BA_ "sigExplanation" SG_ 235 BMS_HVlinkError_ContactorWelded "null";
BA_ "sigSecLevel" SG_ 235 BMS_HVlinkError_HV_Interlock_Bad "null";
BA_ "sigConfig" SG_ 235 BMS_HVlinkError_HV_Interlock_Bad "null";
BA_ "sigExplanation" SG_ 235 BMS_HVlinkError_HV_Interlock_Bad "null";
BA_ "SystemSignalLongSymbol" SG_ 235 BMS_HVlinkError_HV_Interlock_Bad "BMS_HVlinkError_HV_Interlock_BadSigIntegr";
BA_ "sigSecLevel" SG_ 235 BMS_HardwareError_LCM_General_Fa "null";
BA_ "sigConfig" SG_ 235 BMS_HardwareError_LCM_General_Fa "null";
BA_ "sigExplanation" SG_ 235 BMS_HardwareError_LCM_General_Fa "null";
BA_ "SystemSignalLongSymbol" SG_ 235 BMS_HardwareError_LCM_General_Fa "BMS_HardwareError_LCM_General_Failr";
BA_ "sigSecLevel" SG_ 235 BMS_SoftwareError_General_Failr "null";
BA_ "sigConfig" SG_ 235 BMS_SoftwareError_General_Failr "null";
BA_ "sigExplanation" SG_ 235 BMS_SoftwareError_General_Failr "null";
BA_ "sigSecLevel" SG_ 235 BMS_ErrorWarning_CellOverVoltage "null";
BA_ "sigConfig" SG_ 235 BMS_ErrorWarning_CellOverVoltage "null";
BA_ "sigExplanation" SG_ 235 BMS_ErrorWarning_CellOverVoltage "null";
BA_ "sigSecLevel" SG_ 235 BMS_ErrorActive_CellOverVoltage "null";
BA_ "sigConfig" SG_ 235 BMS_ErrorActive_CellOverVoltage "null";
BA_ "sigExplanation" SG_ 235 BMS_ErrorActive_CellOverVoltage "null";
BA_ "sigSecLevel" SG_ 235 BMS_ErrorWarning_CellUnderVoltag "null";
BA_ "sigConfig" SG_ 235 BMS_ErrorWarning_CellUnderVoltag "null";
BA_ "sigExplanation" SG_ 235 BMS_ErrorWarning_CellUnderVoltag "null";
BA_ "SystemSignalLongSymbol" SG_ 235 BMS_ErrorWarning_CellUnderVoltag "BMS_ErrorWarning_CellUnderVoltage";
BA_ "sigSecLevel" SG_ 235 BMS_ErrorActive_CellUnderVoltage "null";
BA_ "sigConfig" SG_ 235 BMS_ErrorActive_CellUnderVoltage "null";
BA_ "sigExplanation" SG_ 235 BMS_ErrorActive_CellUnderVoltage "null";
BA_ "sigSecLevel" SG_ 235 BMS_ErrorWarning_CellTempHigh "null";
BA_ "sigConfig" SG_ 235 BMS_ErrorWarning_CellTempHigh "null";
BA_ "sigExplanation" SG_ 235 BMS_ErrorWarning_CellTempHigh "null";
BA_ "sigSecLevel" SG_ 235 BMS_ErrorActive_CellTempHigh "null";
BA_ "sigConfig" SG_ 235 BMS_ErrorActive_CellTempHigh "null";
BA_ "sigExplanation" SG_ 235 BMS_ErrorActive_CellTempHigh "null";
BA_ "sigSecLevel" SG_ 235 BMS_ErrorWarning_CellTempLow "null";
BA_ "sigConfig" SG_ 235 BMS_ErrorWarning_CellTempLow "null";
BA_ "sigExplanation" SG_ 235 BMS_ErrorWarning_CellTempLow "null";
BA_ "sigSecLevel" SG_ 235 BMS_ErrorActive_CellTempLow "null";
BA_ "sigConfig" SG_ 235 BMS_ErrorActive_CellTempLow "null";
BA_ "sigExplanation" SG_ 235 BMS_ErrorActive_CellTempLow "null";
BA_ "sigSecLevel" SG_ 235 BMS_ErrorWarning_HV_OverVoltage "null";
BA_ "sigConfig" SG_ 235 BMS_ErrorWarning_HV_OverVoltage "null";
BA_ "sigExplanation" SG_ 235 BMS_ErrorWarning_HV_OverVoltage "null";
BA_ "sigSecLevel" SG_ 235 BMS_ErrorActive_HV_OverVoltage "null";
BA_ "sigConfig" SG_ 235 BMS_ErrorActive_HV_OverVoltage "null";
BA_ "sigExplanation" SG_ 235 BMS_ErrorActive_HV_OverVoltage "null";
BA_ "sigSecLevel" SG_ 235 BMS_ErrorWarning_HV_UnderVoltage "null";
BA_ "sigConfig" SG_ 235 BMS_ErrorWarning_HV_UnderVoltage "null";
BA_ "sigExplanation" SG_ 235 BMS_ErrorWarning_HV_UnderVoltage "null";
BA_ "sigSecLevel" SG_ 235 BMS_ErrorActive_HV_UnderVoltage "null";
BA_ "sigConfig" SG_ 235 BMS_ErrorActive_HV_UnderVoltage "null";
BA_ "sigExplanation" SG_ 235 BMS_ErrorActive_HV_UnderVoltage "null";
BA_ "sigSecLevel" SG_ 235 BMS_PVIU_CANcommError "null";
BA_ "sigConfig" SG_ 235 BMS_PVIU_CANcommError "null";
BA_ "sigExplanation" SG_ 235 BMS_PVIU_CANcommError "null";
BA_ "sigSecLevel" SG_ 237 BMS_OverallStatus_CheckSum "null";
BA_ "sigConfig" SG_ 237 BMS_OverallStatus_CheckSum "null";
BA_ "sigExplanation" SG_ 237 BMS_OverallStatus_CheckSum "null";
BA_ "sigSecLevel" SG_ 237 BMS_OverallStatus_AliveCounter "null";
BA_ "sigConfig" SG_ 237 BMS_OverallStatus_AliveCounter "null";
BA_ "sigExplanation" SG_ 237 BMS_OverallStatus_AliveCounter "null";
BA_ "sigSecLevel" SG_ 237 BMS_OperationStates "null";
BA_ "sigConfig" SG_ 237 BMS_OperationStates "null";
BA_ "sigExplanation" SG_ 237 BMS_OperationStates "null";
BA_ "sigSecLevel" SG_ 237 BMS_BallancingStatus "null";
BA_ "sigConfig" SG_ 237 BMS_BallancingStatus "null";
BA_ "sigExplanation" SG_ 237 BMS_BallancingStatus "null";
BA_ "sigSecLevel" SG_ 237 BMS_ErrorCategory_CAT0 "null";
BA_ "sigConfig" SG_ 237 BMS_ErrorCategory_CAT0 "null";
BA_ "sigExplanation" SG_ 237 BMS_ErrorCategory_CAT0 "null";
BA_ "sigSecLevel" SG_ 237 BMS_ErrorCategory_CAT1 "null";
BA_ "sigConfig" SG_ 237 BMS_ErrorCategory_CAT1 "null";
BA_ "sigExplanation" SG_ 237 BMS_ErrorCategory_CAT1 "null";
BA_ "sigSecLevel" SG_ 237 BMS_ErrorCategory_CAT2 "null";
BA_ "sigConfig" SG_ 237 BMS_ErrorCategory_CAT2 "null";
BA_ "sigExplanation" SG_ 237 BMS_ErrorCategory_CAT2 "null";
BA_ "sigSecLevel" SG_ 237 BMS_ErrorCategory_CAT3 "null";
BA_ "sigConfig" SG_ 237 BMS_ErrorCategory_CAT3 "null";
BA_ "sigExplanation" SG_ 237 BMS_ErrorCategory_CAT3 "null";
BA_ "sigSecLevel" SG_ 237 BMS_ErrorCategory_CAT4 "null";
BA_ "sigConfig" SG_ 237 BMS_ErrorCategory_CAT4 "null";
BA_ "sigExplanation" SG_ 237 BMS_ErrorCategory_CAT4 "null";
BA_ "sigSecLevel" SG_ 237 BMS_ErrorCategory_CAT5 "null";
BA_ "sigConfig" SG_ 237 BMS_ErrorCategory_CAT5 "null";
BA_ "sigExplanation" SG_ 237 BMS_ErrorCategory_CAT5 "null";
BA_ "sigSecLevel" SG_ 237 BMS_ErrorCategory_CAT6 "null";
BA_ "sigConfig" SG_ 237 BMS_ErrorCategory_CAT6 "null";
BA_ "sigExplanation" SG_ 237 BMS_ErrorCategory_CAT6 "null";
BA_ "sigSecLevel" SG_ 237 BMS_ErrorCategory_CAT7 "null";
BA_ "sigConfig" SG_ 237 BMS_ErrorCategory_CAT7 "null";
BA_ "sigExplanation" SG_ 237 BMS_ErrorCategory_CAT7 "null";
BA_ "sigSecLevel" SG_ 237 BMS_ErrorCategory_CAT8 "null";
BA_ "sigConfig" SG_ 237 BMS_ErrorCategory_CAT8 "null";
BA_ "sigExplanation" SG_ 237 BMS_ErrorCategory_CAT8 "null";
BA_ "sigSecLevel" SG_ 237 BMS_HardwareStatus_OK "null";
BA_ "sigConfig" SG_ 237 BMS_HardwareStatus_OK "null";
BA_ "sigExplanation" SG_ 237 BMS_HardwareStatus_OK "null";
BA_ "sigSecLevel" SG_ 237 BMS_ErrorCategory_Mem_Empty "null";
BA_ "sigConfig" SG_ 237 BMS_ErrorCategory_Mem_Empty "null";
BA_ "sigExplanation" SG_ 237 BMS_ErrorCategory_Mem_Empty "null";
BA_ "sigSecLevel" SG_ 237 BMS_ConfigurationStatus_OK "null";
BA_ "sigConfig" SG_ 237 BMS_ConfigurationStatus_OK "null";
BA_ "sigExplanation" SG_ 237 BMS_ConfigurationStatus_OK "null";
BA_ "sigSecLevel" SG_ 237 BMS_MeasurementModules_OK "null";
BA_ "sigConfig" SG_ 237 BMS_MeasurementModules_OK "null";
BA_ "sigExplanation" SG_ 237 BMS_MeasurementModules_OK "null";
BA_ "sigSecLevel" SG_ 237 BMS_BatteryGeneralStatus_OK "null";
BA_ "sigConfig" SG_ 237 BMS_BatteryGeneralStatus_OK "null";
BA_ "sigExplanation" SG_ 237 BMS_BatteryGeneralStatus_OK "null";
BA_ "sigSecLevel" SG_ 237 BMS_SDIL_Sts "null";
BA_ "sigConfig" SG_ 237 BMS_SDIL_Sts "null";
BA_ "sigExplanation" SG_ 237 BMS_SDIL_Sts "null";
BA_ "sigSecLevel" SG_ 237 BMS_CL30C_Sts "null";
BA_ "sigConfig" SG_ 237 BMS_CL30C_Sts "null";
BA_ "sigExplanation" SG_ 237 BMS_CL30C_Sts "null";
BA_ "sigSecLevel" SG_ 237 BMS_CL15_Sts "null";
BA_ "sigConfig" SG_ 237 BMS_CL15_Sts "null";
BA_ "sigExplanation" SG_ 237 BMS_CL15_Sts "null";
BA_ "sigSecLevel" SG_ 237 BMS_HVIL_OK "null";
BA_ "sigConfig" SG_ 237 BMS_HVIL_OK "null";
BA_ "sigExplanation" SG_ 237 BMS_HVIL_OK "null";
BA_ "sigSecLevel" SG_ 237 BMS_HV_ContactorsStatus_OK "null";
BA_ "sigConfig" SG_ 237 BMS_HV_ContactorsStatus_OK "null";
BA_ "sigExplanation" SG_ 237 BMS_HV_ContactorsStatus_OK "null";
BA_ "sigSecLevel" SG_ 237 BMS_SW_Status_OK "null";
BA_ "sigConfig" SG_ 237 BMS_SW_Status_OK "null";
BA_ "sigExplanation" SG_ 237 BMS_SW_Status_OK "null";
BA_ "sigSecLevel" SG_ 237 BMS_CurrentSensor_OK "null";
BA_ "sigConfig" SG_ 237 BMS_CurrentSensor_OK "null";
BA_ "sigExplanation" SG_ 237 BMS_CurrentSensor_OK "null";
BA_ "sigSecLevel" SG_ 237 BMS_IsolatoinStatus_OK "null";
BA_ "sigConfig" SG_ 237 BMS_IsolatoinStatus_OK "null";
BA_ "sigExplanation" SG_ 237 BMS_IsolatoinStatus_OK "null";
BA_ "sigSecLevel" SG_ 237 BMS_StateMAchine_Status "null";
BA_ "sigConfig" SG_ 237 BMS_StateMAchine_Status "null";
BA_ "sigExplanation" SG_ 237 BMS_StateMAchine_Status "null";
BA_ "sigSecLevel" SG_ 237 BMS_BDU_Status "null";
BA_ "sigConfig" SG_ 237 BMS_BDU_Status "null";
BA_ "sigExplanation" SG_ 237 BMS_BDU_Status "null";
BA_ "sigSecLevel" SG_ 238 BMS_Volt_PST_CheckSum "null";
BA_ "sigConfig" SG_ 238 BMS_Volt_PST_CheckSum "null";
BA_ "sigExplanation" SG_ 238 BMS_Volt_PST_CheckSum "null";
BA_ "sigSecLevel" SG_ 238 BMS_Volt_PST_AliveCounter "null";
BA_ "sigConfig" SG_ 238 BMS_Volt_PST_AliveCounter "null";
BA_ "sigExplanation" SG_ 238 BMS_Volt_PST_AliveCounter "null";
BA_ "sigSecLevel" SG_ 238 BMS_Bat_D_MAXvolt_PST "null";
BA_ "sigConfig" SG_ 238 BMS_Bat_D_MAXvolt_PST "null";
BA_ "sigExplanation" SG_ 238 BMS_Bat_D_MAXvolt_PST "null";
BA_ "sigSecLevel" SG_ 238 BMS_Bat_C_MAXvolt_PS "null";
BA_ "sigConfig" SG_ 238 BMS_Bat_C_MAXvolt_PS "null";
BA_ "sigExplanation" SG_ 238 BMS_Bat_C_MAXvolt_PS "null";
BA_ "sigSecLevel" SG_ 242 BMS_Cell_Volt_max "null";
BA_ "sigConfig" SG_ 242 BMS_Cell_Volt_max "null";
BA_ "sigExplanation" SG_ 242 BMS_Cell_Volt_max "null";
BA_ "sigSecLevel" SG_ 242 BMS_Cell_Volt_min "B";
BA_ "sigConfig" SG_ 242 BMS_Cell_Volt_min "null";
BA_ "sigExplanation" SG_ 242 BMS_Cell_Volt_min "null";
BA_ "sigSecLevel" SG_ 242 BMS_Cell_Volt_nom "null";
BA_ "sigConfig" SG_ 242 BMS_Cell_Volt_nom "null";
BA_ "sigExplanation" SG_ 242 BMS_Cell_Volt_nom "null";
BA_ "sigSecLevel" SG_ 336 MCU_F_150_CheckSum "null";
BA_ "sigConfig" SG_ 336 MCU_F_150_CheckSum "null";
BA_ "sigExplanation" SG_ 336 MCU_F_150_CheckSum "null";
BA_ "sigSecLevel" SG_ 336 MCU_F_150_AliveCounter "null";
BA_ "sigConfig" SG_ 336 MCU_F_150_AliveCounter "null";
BA_ "sigExplanation" SG_ 336 MCU_F_150_AliveCounter "null";
BA_ "sigSecLevel" SG_ 336 MCU_F_CrtTqVld "B";
BA_ "sigConfig" SG_ 336 MCU_F_CrtTqVld "null";
BA_ "sigExplanation" SG_ 336 MCU_F_CrtTqVld "null";
BA_ "sigSecLevel" SG_ 336 MCU_F_CrtRotDir "C";
BA_ "sigConfig" SG_ 336 MCU_F_CrtRotDir "null";
BA_ "sigExplanation" SG_ 336 MCU_F_CrtRotDir "null";
BA_ "GenSigStartValue" SG_ 336 MCU_F_CrtSpd 32768;
BA_ "sigSecLevel" SG_ 336 MCU_F_CrtSpd "C";
BA_ "sigConfig" SG_ 336 MCU_F_CrtSpd "null";
BA_ "sigExplanation" SG_ 336 MCU_F_CrtSpd "null";
BA_ "GenSigStartValue" SG_ 336 MCU_F_CrtTq 1022;
BA_ "sigSecLevel" SG_ 336 MCU_F_CrtTq "B";
BA_ "sigConfig" SG_ 336 MCU_F_CrtTq "null";
BA_ "sigExplanation" SG_ 336 MCU_F_CrtTq "null";
BA_ "sigSecLevel" SG_ 336 MCU_F_CrtSpdSigVld "C";
BA_ "sigConfig" SG_ 336 MCU_F_CrtSpdSigVld "null";
BA_ "sigExplanation" SG_ 336 MCU_F_CrtSpdSigVld "null";
BA_ "GenSigStartValue" SG_ 336 MCU_F_CrtMod 14;
BA_ "sigSecLevel" SG_ 336 MCU_F_CrtMod "C";
BA_ "sigConfig" SG_ 336 MCU_F_CrtMod "null";
BA_ "sigExplanation" SG_ 336 MCU_F_CrtMod "null";
BA_ "GenSigStartValue" SG_ 336 MCU_F_HVActvDchaSts 6;
BA_ "sigSecLevel" SG_ 336 MCU_F_HVActvDchaSts "B";
BA_ "sigConfig" SG_ 336 MCU_F_HVActvDchaSts "null";
BA_ "sigExplanation" SG_ 336 MCU_F_HVActvDchaSts "null";
BA_ "sigSecLevel" SG_ 336 MCU_F_SlipCtrlActMode "QM";
BA_ "sigSecLevel" SG_ 336 MCU_F_AlrmLamp_FS "null";
BA_ "sigConfig" SG_ 336 MCU_F_AlrmLamp_FS "null";
BA_ "sigExplanation" SG_ 336 MCU_F_AlrmLamp_FS "null";
BA_ "sigSecLevel" SG_ 336 MCU_F_HVChkEndFlg "null";
BA_ "sigConfig" SG_ 336 MCU_F_HVChkEndFlg "null";
BA_ "sigExplanation" SG_ 336 MCU_F_HVChkEndFlg "null";
BA_ "sigSecLevel" SG_ 337 MCU_R_151_CheckSum "null";
BA_ "sigConfig" SG_ 337 MCU_R_151_CheckSum "null";
BA_ "sigExplanation" SG_ 337 MCU_R_151_CheckSum "null";
BA_ "sigSecLevel" SG_ 337 MCU_R_151_AliveCounter "null";
BA_ "sigConfig" SG_ 337 MCU_R_151_AliveCounter "null";
BA_ "sigExplanation" SG_ 337 MCU_R_151_AliveCounter "null";
BA_ "sigSecLevel" SG_ 337 MCU_R_CrtTqVld "B";
BA_ "sigConfig" SG_ 337 MCU_R_CrtTqVld "null";
BA_ "sigExplanation" SG_ 337 MCU_R_CrtTqVld "null";
BA_ "sigSecLevel" SG_ 337 MCU_R_CrtRotDir "C";
BA_ "sigConfig" SG_ 337 MCU_R_CrtRotDir "null";
BA_ "sigExplanation" SG_ 337 MCU_R_CrtRotDir "null";
BA_ "GenSigStartValue" SG_ 337 MCU_R_CrtSpd 32768;
BA_ "sigSecLevel" SG_ 337 MCU_R_CrtSpd "C";
BA_ "sigConfig" SG_ 337 MCU_R_CrtSpd "null";
BA_ "sigExplanation" SG_ 337 MCU_R_CrtSpd "null";
BA_ "GenSigStartValue" SG_ 337 MCU_R_CrtTq 1022;
BA_ "sigSecLevel" SG_ 337 MCU_R_CrtTq "B";
BA_ "sigConfig" SG_ 337 MCU_R_CrtTq "null";
BA_ "sigExplanation" SG_ 337 MCU_R_CrtTq "null";
BA_ "sigSecLevel" SG_ 337 MCU_R_CrtSpdSigVld "C";
BA_ "sigConfig" SG_ 337 MCU_R_CrtSpdSigVld "null";
BA_ "sigExplanation" SG_ 337 MCU_R_CrtSpdSigVld "null";
BA_ "GenSigStartValue" SG_ 337 MCU_R_CrtMod 14;
BA_ "sigSecLevel" SG_ 337 MCU_R_CrtMod "C";
BA_ "sigConfig" SG_ 337 MCU_R_CrtMod "null";
BA_ "sigExplanation" SG_ 337 MCU_R_CrtMod "null";
BA_ "sigSecLevel" SG_ 337 MCU_R_Decoup_State "C";
BA_ "sigConfig" SG_ 337 MCU_R_Decoup_State "C";
BA_ "sigExplanation" SG_ 337 MCU_R_Decoup_State "null";
BA_ "GenSigStartValue" SG_ 337 MCU_R_HVActvDchaSts 6;
BA_ "sigSecLevel" SG_ 337 MCU_R_HVActvDchaSts "B";
BA_ "sigConfig" SG_ 337 MCU_R_HVActvDchaSts "null";
BA_ "sigExplanation" SG_ 337 MCU_R_HVActvDchaSts "null";
BA_ "sigSecLevel" SG_ 337 MCU_R_SlipCtrlActMode "QM";
BA_ "sigSecLevel" SG_ 337 MCU_R_AlrmLamp_FS "null";
BA_ "sigConfig" SG_ 337 MCU_R_AlrmLamp_FS "null";
BA_ "sigExplanation" SG_ 337 MCU_R_AlrmLamp_FS "null";
BA_ "sigSecLevel" SG_ 337 MCU_R_HVChkEndFlg "null";
BA_ "sigConfig" SG_ 337 MCU_R_HVChkEndFlg "null";
BA_ "sigExplanation" SG_ 337 MCU_R_HVChkEndFlg "null";
BA_ "sigSecLevel" SG_ 533 BMS_215_CheckSum "null";
BA_ "sigConfig" SG_ 533 BMS_215_CheckSum "null";
BA_ "sigExplanation" SG_ 533 BMS_215_CheckSum "null";
BA_ "sigSecLevel" SG_ 533 BMS_215_AliveCounter "null";
BA_ "sigConfig" SG_ 533 BMS_215_AliveCounter "null";
BA_ "sigExplanation" SG_ 533 BMS_215_AliveCounter "null";
BA_ "sigSecLevel" SG_ 533 BMS_PwrBattOverTFlt_FS "null";
BA_ "sigConfig" SG_ 533 BMS_PwrBattOverTFlt_FS "null";
BA_ "sigExplanation" SG_ 533 BMS_PwrBattOverTFlt_FS "null";
BA_ "sigSecLevel" SG_ 533 BMS_PwrBattOverCrtFlt_FS "null";
BA_ "sigConfig" SG_ 533 BMS_PwrBattOverCrtFlt_FS "null";
BA_ "sigExplanation" SG_ 533 BMS_PwrBattOverCrtFlt_FS "null";
BA_ "sigSecLevel" SG_ 533 BMS_PwrBattNegRlyAdh_FS "null";
BA_ "sigConfig" SG_ 533 BMS_PwrBattNegRlyAdh_FS "null";
BA_ "sigExplanation" SG_ 533 BMS_PwrBattNegRlyAdh_FS "null";
BA_ "sigSecLevel" SG_ 533 BMS_PwrBattPosRlyAdh_FS "null";
BA_ "sigConfig" SG_ 533 BMS_PwrBattPosRlyAdh_FS "null";
BA_ "sigExplanation" SG_ 533 BMS_PwrBattPosRlyAdh_FS "null";
BA_ "sigSecLevel" SG_ 533 BMS_CellUnderrVoltFlt_FS "null";
BA_ "sigConfig" SG_ 533 BMS_CellUnderrVoltFlt_FS "null";
BA_ "sigExplanation" SG_ 533 BMS_CellUnderrVoltFlt_FS "null";
BA_ "sigSecLevel" SG_ 533 BMS_PwrBattCellOverVolt_FS "B";
BA_ "sigConfig" SG_ 533 BMS_PwrBattCellOverVolt_FS "null";
BA_ "sigExplanation" SG_ 533 BMS_PwrBattCellOverVolt_FS "null";
BA_ "sigSecLevel" SG_ 533 BMS_BattInlTSnsrFlt "null";
BA_ "sigConfig" SG_ 533 BMS_BattInlTSnsrFlt "null";
BA_ "sigExplanation" SG_ 533 BMS_BattInlTSnsrFlt "null";
BA_ "sigSecLevel" SG_ 533 BMS_BattOutlTSnsrFlt "null";
BA_ "sigConfig" SG_ 533 BMS_BattOutlTSnsrFlt "null";
BA_ "sigExplanation" SG_ 533 BMS_BattOutlTSnsrFlt "null";
BA_ "sigSecLevel" SG_ 533 BMS_PwrBattPrecRlyAdh_FS "null";
BA_ "sigConfig" SG_ 533 BMS_PwrBattPrecRlyAdh_FS "null";
BA_ "sigExplanation" SG_ 533 BMS_PwrBattPrecRlyAdh_FS "null";
BA_ "sigSecLevel" SG_ 533 BMS_AlrmLamp_FS "null";
BA_ "sigConfig" SG_ 533 BMS_AlrmLamp_FS "null";
BA_ "sigExplanation" SG_ 533 BMS_AlrmLamp_FS "null";
BA_ "sigSecLevel" SG_ 533 BMS_PwrBattLoadTotVoltV3_FS "null";
BA_ "sigConfig" SG_ 533 BMS_PwrBattLoadTotVoltV3_FS "null";
BA_ "sigExplanation" SG_ 533 BMS_PwrBattLoadTotVoltV3_FS "null";
BA_ "sigSecLevel" SG_ 533 BMS_FctSftyErrCod "B";
BA_ "sigConfig" SG_ 533 BMS_FctSftyErrCod "null";
BA_ "sigExplanation" SG_ 533 BMS_FctSftyErrCod "null";
BA_ "sigSecLevel" SG_ 608 VCU_DCVoltCmd_OBC "null";
BA_ "sigConfig" SG_ 608 VCU_DCVoltCmd_OBC "null";
BA_ "sigExplanation" SG_ 608 VCU_DCVoltCmd_OBC "null";
BA_ "sigSecLevel" SG_ 608 VCU_DCCrtCmd_OBC "null";
BA_ "sigConfig" SG_ 608 VCU_DCCrtCmd_OBC "null";
BA_ "sigExplanation" SG_ 608 VCU_DCCrtCmd_OBC "null";
BA_ "sigSecLevel" SG_ 608 VCU_VehChrgDchgMod "A";
BA_ "sigConfig" SG_ 608 VCU_VehChrgDchgMod "null";
BA_ "sigExplanation" SG_ 608 VCU_VehChrgDchgMod "null";
BA_ "sigSecLevel" SG_ 608 VCU_DCRlyCtrlCmd "A";
BA_ "sigConfig" SG_ 608 VCU_DCRlyCtrlCmd "null";
BA_ "sigExplanation" SG_ 608 VCU_DCRlyCtrlCmd "null";
BA_ "sigSecLevel" SG_ 608 VCU_ChrgSysOperCmd "A(B)";
BA_ "sigConfig" SG_ 608 VCU_ChrgSysOperCmd "null";
BA_ "sigExplanation" SG_ 608 VCU_ChrgSysOperCmd "null";
BA_ "sigSecLevel" SG_ 608 VCU_ChrgSts "null";
BA_ "sigConfig" SG_ 608 VCU_ChrgSts "null";
BA_ "sigExplanation" SG_ 608 VCU_ChrgSts "null";
BA_ "sigSecLevel" SG_ 608 VCU_260_SSecOC_Fresh_Byte0 "null";
BA_ "sigConfig" SG_ 608 VCU_260_SSecOC_Fresh_Byte0 "null";
BA_ "sigExplanation" SG_ 608 VCU_260_SSecOC_Fresh_Byte0 "null";
BA_ "sigSecLevel" SG_ 608 VCU_260_SSecOC_MAC_Byte0 "null";
BA_ "sigConfig" SG_ 608 VCU_260_SSecOC_MAC_Byte0 "null";
BA_ "sigExplanation" SG_ 608 VCU_260_SSecOC_MAC_Byte0 "null";
BA_ "sigSecLevel" SG_ 608 VCU_260_SSecOC_MAC_Byte1 "null";
BA_ "sigConfig" SG_ 608 VCU_260_SSecOC_MAC_Byte1 "null";
BA_ "sigExplanation" SG_ 608 VCU_260_SSecOC_MAC_Byte1 "null";
BA_ "sigSecLevel" SG_ 608 VCU_260_SSecOC_MAC_Byte2 "null";
BA_ "sigConfig" SG_ 608 VCU_260_SSecOC_MAC_Byte2 "null";
BA_ "sigExplanation" SG_ 608 VCU_260_SSecOC_MAC_Byte2 "null";
BA_ "GenSigSendType" SG_ 627 TBOX_ScheduleCharg_End_Mins 1;
BA_ "GenSigSendType" SG_ 627 TBOX_ScheduleCharg_Start_Hr 1;
BA_ "GenSigSendType" SG_ 627 TBOX_ScheduleCharg_End_Hr 1;
BA_ "GenSigSendType" SG_ 627 TBOX_SetSceduleChargTimeFb 1;
BA_ "GenSigSendType" SG_ 627 TBOX_ScheduleCharg_Start_Mins 1;
BA_ "GenSigSendType" SG_ 627 TBOX_ScheduleCharg_Status 1;
BA_ "GenSigSendType" SG_ 627 TBOX_V2L_TrEna 2;
BA_ "GenSigSendType" SG_ 627 TBOX_V2L_ChrgPortEna 2;
BA_ "GenSigSendType" SG_ 627 TBOX_V2V_Ena 2;
BA_ "GenSigSendType" SG_ 627 TBOX_V2H_Ena 2;
BA_ "GenSigSendType" SG_ 627 TBOX_V2G_Ena 2;
BA_ "sigSecLevel" SG_ 633 BMS_Volt_PmLT_CheckSum "null";
BA_ "sigConfig" SG_ 633 BMS_Volt_PmLT_CheckSum "null";
BA_ "sigExplanation" SG_ 633 BMS_Volt_PmLT_CheckSum "null";
BA_ "sigSecLevel" SG_ 633 BMS_Volt_PmLT_AliveCounter "null";
BA_ "sigConfig" SG_ 633 BMS_Volt_PmLT_AliveCounter "null";
BA_ "sigExplanation" SG_ 633 BMS_Volt_PmLT_AliveCounter "null";
BA_ "sigSecLevel" SG_ 633 BMS_Bat_D_MAXvolt_PmLT "null";
BA_ "sigConfig" SG_ 633 BMS_Bat_D_MAXvolt_PmLT "null";
BA_ "sigExplanation" SG_ 633 BMS_Bat_D_MAXvolt_PmLT "null";
BA_ "sigSecLevel" SG_ 633 BMS_Bat_C_MAXvolt_PmLT "null";
BA_ "sigConfig" SG_ 633 BMS_Bat_C_MAXvolt_PmLT "null";
BA_ "sigExplanation" SG_ 633 BMS_Bat_C_MAXvolt_PmLT "null";
BA_ "sigSecLevel" SG_ 748 BMS_Cont_CurrentState_PV_Pos "null";
BA_ "sigConfig" SG_ 748 BMS_Cont_CurrentState_PV_Pos "null";
BA_ "sigExplanation" SG_ 748 BMS_Cont_CurrentState_PV_Pos "null";
BA_ "sigSecLevel" SG_ 748 BMS_Cont_TargetState_PV_Pos "null";
BA_ "sigConfig" SG_ 748 BMS_Cont_TargetState_PV_Pos "null";
BA_ "sigExplanation" SG_ 748 BMS_Cont_TargetState_PV_Pos "null";
BA_ "sigSecLevel" SG_ 748 BMS_Cont_Coil_I_PV_Pos "null";
BA_ "sigConfig" SG_ 748 BMS_Cont_Coil_I_PV_Pos "null";
BA_ "sigExplanation" SG_ 748 BMS_Cont_Coil_I_PV_Pos "null";
BA_ "sigSecLevel" SG_ 748 BMS_Cont_WearCounter_PV_Pos "null";
BA_ "sigConfig" SG_ 748 BMS_Cont_WearCounter_PV_Pos "null";
BA_ "sigExplanation" SG_ 748 BMS_Cont_WearCounter_PV_Pos "null";
BA_ "sigSecLevel" SG_ 749 BMS_Cont_CurrentState_PV_Neg "null";
BA_ "sigConfig" SG_ 749 BMS_Cont_CurrentState_PV_Neg "null";
BA_ "sigExplanation" SG_ 749 BMS_Cont_CurrentState_PV_Neg "null";
BA_ "sigSecLevel" SG_ 749 BMS_Cont_TargetSgtate_PV_Neg "null";
BA_ "sigConfig" SG_ 749 BMS_Cont_TargetSgtate_PV_Neg "null";
BA_ "sigExplanation" SG_ 749 BMS_Cont_TargetSgtate_PV_Neg "null";
BA_ "sigSecLevel" SG_ 749 BMS_Cont_Coil_I_PV_Neg "null";
BA_ "sigConfig" SG_ 749 BMS_Cont_Coil_I_PV_Neg "null";
BA_ "sigExplanation" SG_ 749 BMS_Cont_Coil_I_PV_Neg "null";
BA_ "sigSecLevel" SG_ 749 BMS_Cont_WearCounter_PV_Neg "null";
BA_ "sigConfig" SG_ 749 BMS_Cont_WearCounter_PV_Neg "null";
BA_ "sigExplanation" SG_ 749 BMS_Cont_WearCounter_PV_Neg "null";
BA_ "sigSecLevel" SG_ 750 BMS_Cont_Act_St_HV_Pos "null";
BA_ "sigConfig" SG_ 750 BMS_Cont_Act_St_HV_Pos "null";
BA_ "sigExplanation" SG_ 750 BMS_Cont_Act_St_HV_Pos "null";
BA_ "sigSecLevel" SG_ 750 BMS_Cont_Tar_St_HV_Pos "null";
BA_ "sigConfig" SG_ 750 BMS_Cont_Tar_St_HV_Pos "null";
BA_ "sigExplanation" SG_ 750 BMS_Cont_Tar_St_HV_Pos "null";
BA_ "sigSecLevel" SG_ 750 BMS_Cont_Coil_I_HV_Pos "null";
BA_ "sigConfig" SG_ 750 BMS_Cont_Coil_I_HV_Pos "null";
BA_ "sigExplanation" SG_ 750 BMS_Cont_Coil_I_HV_Pos "null";
BA_ "sigSecLevel" SG_ 750 BMS_Cont_WearCounter_HV_Pos "null";
BA_ "sigConfig" SG_ 750 BMS_Cont_WearCounter_HV_Pos "null";
BA_ "sigExplanation" SG_ 750 BMS_Cont_WearCounter_HV_Pos "null";
BA_ "sigSecLevel" SG_ 751 BMS_Cont_Act_St_HV_Neg "null";
BA_ "sigConfig" SG_ 751 BMS_Cont_Act_St_HV_Neg "null";
BA_ "sigExplanation" SG_ 751 BMS_Cont_Act_St_HV_Neg "null";
BA_ "sigSecLevel" SG_ 751 BMS_Cont_Tar_St_HV_Neg "null";
BA_ "sigConfig" SG_ 751 BMS_Cont_Tar_St_HV_Neg "null";
BA_ "sigExplanation" SG_ 751 BMS_Cont_Tar_St_HV_Neg "null";
BA_ "sigSecLevel" SG_ 751 BMS_Cont_Coil_I_HV_Neg "null";
BA_ "sigConfig" SG_ 751 BMS_Cont_Coil_I_HV_Neg "null";
BA_ "sigExplanation" SG_ 751 BMS_Cont_Coil_I_HV_Neg "null";
BA_ "sigSecLevel" SG_ 751 BMS_Cont_WearCounter_HV_Neg "null";
BA_ "sigConfig" SG_ 751 BMS_Cont_WearCounter_HV_Neg "null";
BA_ "sigExplanation" SG_ 751 BMS_Cont_WearCounter_HV_Neg "null";
BA_ "sigSecLevel" SG_ 752 BMS_Cont_Act_St_HV_Prec "null";
BA_ "sigConfig" SG_ 752 BMS_Cont_Act_St_HV_Prec "null";
BA_ "sigExplanation" SG_ 752 BMS_Cont_Act_St_HV_Prec "null";
BA_ "sigSecLevel" SG_ 752 BMS_Cont_Tar_St_HV_Prec "null";
BA_ "sigConfig" SG_ 752 BMS_Cont_Tar_St_HV_Prec "null";
BA_ "sigExplanation" SG_ 752 BMS_Cont_Tar_St_HV_Prec "null";
BA_ "sigSecLevel" SG_ 752 BMS_Cont_Coil_I_HV_Prec "null";
BA_ "sigConfig" SG_ 752 BMS_Cont_Coil_I_HV_Prec "null";
BA_ "sigExplanation" SG_ 752 BMS_Cont_Coil_I_HV_Prec "null";
BA_ "sigSecLevel" SG_ 752 BMS_Cont_WearCounter_HV_Prec "null";
BA_ "sigConfig" SG_ 752 BMS_Cont_WearCounter_HV_Prec "null";
BA_ "sigExplanation" SG_ 752 BMS_Cont_WearCounter_HV_Prec "null";
BA_ "sigSecLevel" SG_ 755 BMS_Error_Flag_CheckSum "null";
BA_ "sigConfig" SG_ 755 BMS_Error_Flag_CheckSum "null";
BA_ "sigExplanation" SG_ 755 BMS_Error_Flag_CheckSum "null";
BA_ "sigSecLevel" SG_ 755 BMS_Error_Flag_AliveCounter "null";
BA_ "sigConfig" SG_ 755 BMS_Error_Flag_AliveCounter "null";
BA_ "sigExplanation" SG_ 755 BMS_Error_Flag_AliveCounter "null";
BA_ "sigSecLevel" SG_ 755 BMS_ErrorWarning_CellVoltageDiff "null";
BA_ "sigConfig" SG_ 755 BMS_ErrorWarning_CellVoltageDiff "null";
BA_ "sigExplanation" SG_ 755 BMS_ErrorWarning_CellVoltageDiff "null";
BA_ "SystemSignalLongSymbol" SG_ 755 BMS_ErrorWarning_CellVoltageDiff "BMS_ErrorWarning_CellVoltageDiffOverLim";
BA_ "sigSecLevel" SG_ 755 BMS_ErrorActive_CellVoltageDiffO "null";
BA_ "sigConfig" SG_ 755 BMS_ErrorActive_CellVoltageDiffO "null";
BA_ "sigExplanation" SG_ 755 BMS_ErrorActive_CellVoltageDiffO "null";
BA_ "SystemSignalLongSymbol" SG_ 755 BMS_ErrorActive_CellVoltageDiffO "BMS_ErrorActive_CellVoltageDiffOverLim";
BA_ "sigSecLevel" SG_ 755 BMS_ErrorWarning_Diff_U1_UCellSu "null";
BA_ "sigConfig" SG_ 755 BMS_ErrorWarning_Diff_U1_UCellSu "null";
BA_ "sigExplanation" SG_ 755 BMS_ErrorWarning_Diff_U1_UCellSu "null";
BA_ "SystemSignalLongSymbol" SG_ 755 BMS_ErrorWarning_Diff_U1_UCellSu "BMS_ErrorWarning_Diff_U1_UCellSum";
BA_ "sigSecLevel" SG_ 755 BMS_ErrorActive_Diff_U1_UCellSum "null";
BA_ "sigConfig" SG_ 755 BMS_ErrorActive_Diff_U1_UCellSum "null";
BA_ "sigExplanation" SG_ 755 BMS_ErrorActive_Diff_U1_UCellSum "null";
BA_ "sigSecLevel" SG_ 755 BMS_ErrorWarning_SOH_Low "null";
BA_ "sigConfig" SG_ 755 BMS_ErrorWarning_SOH_Low "null";
BA_ "sigExplanation" SG_ 755 BMS_ErrorWarning_SOH_Low "null";
BA_ "sigSecLevel" SG_ 755 BMS_ErrorActive_SOH_Low "null";
BA_ "sigConfig" SG_ 755 BMS_ErrorActive_SOH_Low "null";
BA_ "sigExplanation" SG_ 755 BMS_ErrorActive_SOH_Low "null";
BA_ "sigSecLevel" SG_ 755 BMS_SystemError_SystemInitFailed "null";
BA_ "sigConfig" SG_ 755 BMS_SystemError_SystemInitFailed "null";
BA_ "sigExplanation" SG_ 755 BMS_SystemError_SystemInitFailed "null";
BA_ "sigSecLevel" SG_ 755 BMS_SystemError_Precharge "null";
BA_ "sigConfig" SG_ 755 BMS_SystemError_Precharge "null";
BA_ "sigExplanation" SG_ 755 BMS_SystemError_Precharge "null";
BA_ "sigSecLevel" SG_ 755 BMS_SystemError_HV_CCT_WrongPola "null";
BA_ "sigConfig" SG_ 755 BMS_SystemError_HV_CCT_WrongPola "null";
BA_ "sigExplanation" SG_ 755 BMS_SystemError_HV_CCT_WrongPola "null";
BA_ "SystemSignalLongSymbol" SG_ 755 BMS_SystemError_HV_CCT_WrongPola "BMS_SystemError_HV_CCT_WrongPolarity";
BA_ "sigSecLevel" SG_ 755 BMS_SystemError_HV_CCT_NoBatVolt "null";
BA_ "sigConfig" SG_ 755 BMS_SystemError_HV_CCT_NoBatVolt "null";
BA_ "sigExplanation" SG_ 755 BMS_SystemError_HV_CCT_NoBatVolt "null";
BA_ "SystemSignalLongSymbol" SG_ 755 BMS_SystemError_HV_CCT_NoBatVolt "BMS_SystemError_HV_CCT_NoBatVoltage";
BA_ "sigSecLevel" SG_ 755 BMS_HVlinkWarning_VCU_MessageInt "null";
BA_ "sigConfig" SG_ 755 BMS_HVlinkWarning_VCU_MessageInt "null";
BA_ "sigExplanation" SG_ 755 BMS_HVlinkWarning_VCU_MessageInt "null";
BA_ "SystemSignalLongSymbol" SG_ 755 BMS_HVlinkWarning_VCU_MessageInt "BMS_HVlinkWarning_VCU_MessageIntegrity";
BA_ "sigSecLevel" SG_ 755 BMS_HVlinkError_IVT_Comm_Failure "null";
BA_ "sigConfig" SG_ 755 BMS_HVlinkError_IVT_Comm_Failure "null";
BA_ "sigExplanation" SG_ 755 BMS_HVlinkError_IVT_Comm_Failure "null";
BA_ "sigSecLevel" SG_ 755 BMS_HVlinkWarning_IVT_Meas_Failu "null";
BA_ "sigConfig" SG_ 755 BMS_HVlinkWarning_IVT_Meas_Failu "null";
BA_ "sigExplanation" SG_ 755 BMS_HVlinkWarning_IVT_Meas_Failu "null";
BA_ "SystemSignalLongSymbol" SG_ 755 BMS_HVlinkWarning_IVT_Meas_Failu "BMS_HVlinkWarning_IVT_Meas_Failure";
BA_ "sigSecLevel" SG_ 755 BMS_HVlinkError_IVT_Meas_Failure "null";
BA_ "sigConfig" SG_ 755 BMS_HVlinkError_IVT_Meas_Failure "null";
BA_ "sigExplanation" SG_ 755 BMS_HVlinkError_IVT_Meas_Failure "null";
BA_ "sigSecLevel" SG_ 755 BMS_HVlinkError_NVM_Comm_Failure "null";
BA_ "sigConfig" SG_ 755 BMS_HVlinkError_NVM_Comm_Failure "null";
BA_ "sigExplanation" SG_ 755 BMS_HVlinkError_NVM_Comm_Failure "null";
BA_ "sigSecLevel" SG_ 755 BMS_HVlinkWarning_Eeprom_LifeCyc "null";
BA_ "sigConfig" SG_ 755 BMS_HVlinkWarning_Eeprom_LifeCyc "null";
BA_ "sigExplanation" SG_ 755 BMS_HVlinkWarning_Eeprom_LifeCyc "null";
BA_ "SystemSignalLongSymbol" SG_ 755 BMS_HVlinkWarning_Eeprom_LifeCyc "BMS_HVlinkWarning_Eeprom_LifeCycleCount";
BA_ "sigSecLevel" SG_ 755 BMS_HVlinkError_Eeprom_LifeCycle "null";
BA_ "sigConfig" SG_ 755 BMS_HVlinkError_Eeprom_LifeCycle "null";
BA_ "sigExplanation" SG_ 755 BMS_HVlinkError_Eeprom_LifeCycle "null";
BA_ "SystemSignalLongSymbol" SG_ 755 BMS_HVlinkError_Eeprom_LifeCycle "BMS_HVlinkError_Eeprom_LifeCycleCount";
BA_ "sigSecLevel" SG_ 755 BMS_HVlinkError_ContactorGeneric "null";
BA_ "sigConfig" SG_ 755 BMS_HVlinkError_ContactorGeneric "null";
BA_ "sigExplanation" SG_ 755 BMS_HVlinkError_ContactorGeneric "null";
BA_ "sigSecLevel" SG_ 755 BMS_HVlinkError_ContactorOpen "null";
BA_ "sigConfig" SG_ 755 BMS_HVlinkError_ContactorOpen "null";
BA_ "sigExplanation" SG_ 755 BMS_HVlinkError_ContactorOpen "null";
BA_ "sigSecLevel" SG_ 755 BMS_HVlinkError_ContactorAuxFail "null";
BA_ "sigConfig" SG_ 755 BMS_HVlinkError_ContactorAuxFail "null";
BA_ "sigExplanation" SG_ 755 BMS_HVlinkError_ContactorAuxFail "null";
BA_ "SystemSignalLongSymbol" SG_ 755 BMS_HVlinkError_ContactorAuxFail "BMS_HVlinkError_ContactorAuxFailed";
BA_ "sigSecLevel" SG_ 755 BMS_HVlinkError_ContactorPwmEcon "null";
BA_ "sigConfig" SG_ 755 BMS_HVlinkError_ContactorPwmEcon "null";
BA_ "sigExplanation" SG_ 755 BMS_HVlinkError_ContactorPwmEcon "null";
BA_ "SystemSignalLongSymbol" SG_ 755 BMS_HVlinkError_ContactorPwmEcon "BMS_HVlinkError_ContactorPwmEconomizer";
BA_ "sigSecLevel" SG_ 755 BMS_HVlinkWarning_AnalogInput_Ex "null";
BA_ "sigConfig" SG_ 755 BMS_HVlinkWarning_AnalogInput_Ex "null";
BA_ "sigExplanation" SG_ 755 BMS_HVlinkWarning_AnalogInput_Ex "null";
BA_ "SystemSignalLongSymbol" SG_ 755 BMS_HVlinkWarning_AnalogInput_Ex "BMS_HVlinkWarning_AnalogInput_Exceed_Lim";
BA_ "sigSecLevel" SG_ 755 BMS_HVlinkError_AnalogInput_Exce "null";
BA_ "sigConfig" SG_ 755 BMS_HVlinkError_AnalogInput_Exce "null";
BA_ "sigExplanation" SG_ 755 BMS_HVlinkError_AnalogInput_Exce "null";
BA_ "SystemSignalLongSymbol" SG_ 755 BMS_HVlinkError_AnalogInput_Exce "BMS_HVlinkError_AnalogInput_Exceed_Lim";
BA_ "sigSecLevel" SG_ 755 BMS_HWerror_KL30_Voltage "null";
BA_ "sigConfig" SG_ 755 BMS_HWerror_KL30_Voltage "null";
BA_ "sigExplanation" SG_ 755 BMS_HWerror_KL30_Voltage "null";
BA_ "sigSecLevel" SG_ 755 BMS_HWerror_SD_Voltage "null";
BA_ "sigConfig" SG_ 755 BMS_HWerror_SD_Voltage "null";
BA_ "sigExplanation" SG_ 755 BMS_HWerror_SD_Voltage "null";
BA_ "sigSecLevel" SG_ 755 BMS_HWerror_PCB_Temp_Sensor_Fail "null";
BA_ "sigConfig" SG_ 755 BMS_HWerror_PCB_Temp_Sensor_Fail "null";
BA_ "sigExplanation" SG_ 755 BMS_HWerror_PCB_Temp_Sensor_Fail "null";
BA_ "sigSecLevel" SG_ 755 BMS_HWerror_Cell_Temp_Sensor_Fai "null";
BA_ "sigConfig" SG_ 755 BMS_HWerror_Cell_Temp_Sensor_Fai "null";
BA_ "sigExplanation" SG_ 755 BMS_HWerror_Cell_Temp_Sensor_Fai "null";
BA_ "SystemSignalLongSymbol" SG_ 755 BMS_HWerror_Cell_Temp_Sensor_Fai "BMS_HWerror_Cell_Temp_Sensor_Fail";
BA_ "sigSecLevel" SG_ 755 BMS_HWwarning_LCM_PCB_OverTemp "null";
BA_ "sigConfig" SG_ 755 BMS_HWwarning_LCM_PCB_OverTemp "null";
BA_ "sigExplanation" SG_ 755 BMS_HWwarning_LCM_PCB_OverTemp "null";
BA_ "sigSecLevel" SG_ 755 BMS_HWerror_LCM_PCB_OverTemp "null";
BA_ "sigConfig" SG_ 755 BMS_HWerror_LCM_PCB_OverTemp "null";
BA_ "sigExplanation" SG_ 755 BMS_HWerror_LCM_PCB_OverTemp "null";
BA_ "sigSecLevel" SG_ 755 BMS_HWwarning_LCM_PCB_UnderTemp "null";
BA_ "sigConfig" SG_ 755 BMS_HWwarning_LCM_PCB_UnderTemp "null";
BA_ "sigExplanation" SG_ 755 BMS_HWwarning_LCM_PCB_UnderTemp "null";
BA_ "sigSecLevel" SG_ 755 BMS_HWerror_LCM_PCB_UnderTemp "null";
BA_ "sigConfig" SG_ 755 BMS_HWerror_LCM_PCB_UnderTemp "null";
BA_ "sigExplanation" SG_ 755 BMS_HWerror_LCM_PCB_UnderTemp "null";
BA_ "sigSecLevel" SG_ 755 BMS_Software_Error_Boot_Faild "null";
BA_ "sigConfig" SG_ 755 BMS_Software_Error_Boot_Faild "null";
BA_ "sigExplanation" SG_ 755 BMS_Software_Error_Boot_Faild "null";
BA_ "sigSecLevel" SG_ 755 BMS_DTC_status "null";
BA_ "sigConfig" SG_ 755 BMS_DTC_status "null";
BA_ "sigExplanation" SG_ 755 BMS_DTC_status "null";
BA_ "sigSecLevel" SG_ 757 BMS_Bat_SoC_usable "null";
BA_ "sigConfig" SG_ 757 BMS_Bat_SoC_usable "null";
BA_ "sigExplanation" SG_ 757 BMS_Bat_SoC_usable "null";
BA_ "sigSecLevel" SG_ 757 BMS_Bat_Actual_Pack_Capacity "null";
BA_ "sigConfig" SG_ 757 BMS_Bat_Actual_Pack_Capacity "null";
BA_ "sigExplanation" SG_ 757 BMS_Bat_Actual_Pack_Capacity "null";
BA_ "sigSecLevel" SG_ 757 BMS_Bat_SOH "null";
BA_ "sigConfig" SG_ 757 BMS_Bat_SOH "null";
BA_ "sigExplanation" SG_ 757 BMS_Bat_SOH "null";
BA_ "sigSecLevel" SG_ 758 BMS_Curr_PLT_CheckSum "null";
BA_ "sigConfig" SG_ 758 BMS_Curr_PLT_CheckSum "null";
BA_ "sigExplanation" SG_ 758 BMS_Curr_PLT_CheckSum "null";
BA_ "sigSecLevel" SG_ 758 BMS_Curr_PLT_AliveCounter "null";
BA_ "sigConfig" SG_ 758 BMS_Curr_PLT_AliveCounter "null";
BA_ "sigExplanation" SG_ 758 BMS_Curr_PLT_AliveCounter "null";
BA_ "sigSecLevel" SG_ 758 BMS_Bat_D_MAXcurr_PLT "A(B)";
BA_ "sigConfig" SG_ 758 BMS_Bat_D_MAXcurr_PLT "null";
BA_ "sigExplanation" SG_ 758 BMS_Bat_D_MAXcurr_PLT "null";
BA_ "sigSecLevel" SG_ 758 BMS_Bat_C_MAXcurr_PLT "B";
BA_ "sigConfig" SG_ 758 BMS_Bat_C_MAXcurr_PLT "null";
BA_ "sigExplanation" SG_ 758 BMS_Bat_C_MAXcurr_PLT "null";
VAL_ 54 TBOX_RemSeekCarCtrlCmd 0 "without_remote_control" 1 "Remote_flash_lamp" 2 "Sound_horn_remotely" 3 "Remote_flashing_horn" ;
VAL_ 54 TBOX_RemClsTrCmd 0 "without_remote_control" 1 "Remote_open_tailgate" 2 "Remote_close_tailgate" 3 "Reserved" ;
VAL_ 54 TBOX_RemDrvrSeatVentnCmd 0 "Void" 1 "Remote_driver_seat_ventilation_high_gear" 2 "remote_driver_seat_ventilation_middle_gear" 3 "remote_driver_seat_ventilation_low_gear" 4 "remotely_close_driver_seat_ventilation" 5 "Reserved" 6 "Reserved" 7 "Reserved" ;
VAL_ 54 TBOX_RemDrvrSeatHeatgCmd 0 "Void" 1 "remote_driver's_seat_heating_high_gear" 2 "remote_driver_seat_heating_mid_gear" 3 "remote_driver's_seat_heating_low_gear" 4 "remotely_close_driver_seat_heating" 5 "Reserved" 6 "Reserved" 7 "Reserved" ;
VAL_ 54 TBOX_RemSetWelFct 0 "No_remote_setting" 1 "function_on" 2 "function_OFF" 3 "Reserved" ;
VAL_ 54 TBOX_RemPassSeatVentnCmd 0 "without_remote_control" 1 "Open_the_first_position_of_the_passenger_seat_remotely" 2 "Open_the_second_ventilation_gear_of_the_passenger_seat_remotely" 3 "Remote_driving_passenger_seat_ventilation_third_gear" 4 "Remote_closing_passenger_seat_heating" 5 "Reserved" 6 "Reserved" 7 "Reserved" ;
VAL_ 54 TBOX_RemPassSeatHeatgCmd 0 "without_remote_control" 1 "Remote_open_passenger_seat_heating_first_gear" 2 "Remote_passenger_seat_heating_second_gear" 3 "Remote_passenger_seat_heating_third_gear" 4 "Remote_closing_passenger_seat_heating" 5 "Reserved" 6 "Reserved" 7 "Reserved" ;
VAL_ 54 TBOX_ClsAVMFct_ICC 0 "without_remote_control" 1 "Turn_off_ICC" ;
VAL_ 54 TBOX_ClsRemAVMFct_AVAP 0 "without_remote_control" 1 "Turn_off_AVAP" ;
VAL_ 54 TBOX_RemSetFolwMeFct_BCM 0 "No_remote_setting" 1 "Follow_Me_Home_function_OFF" 2 "headlamp_delay:15_s" 3 "Headlamp_delay:30_s" 4 "Headlamp_delay:45_s" 5 "Headlamp_delay_60_s" 6 "Reserved" 7 "Reserved" ;
VAL_ 54 TBOX_RemSetCtrlLockFct_PKC 0 "No_remote_setting" 1 "function_on" 2 "function_OFF" 3 "Reserved" ;
VAL_ 54 TBOX_RemSetKickSnsrFct 0 "No_remote_setting" 1 "function_on" 2 "function_OFF" 3 "Reserved" ;
VAL_ 54 TBOX_VideoCtrlReq 0 "No_remote_view_command" 1 "panoramic" 2 "Left_side" 3 "Right" 4 "Front_side" 5 "Rear_side" 6 "Turn_off_views" 7 "Reserved" ;
VAL_ 54 TBOX_VoiceBlowerLimReq 0 "No_request" 1 "Request" ;
VAL_ 54 TBOX_RemCtrlCmdFb 0 "Void" 1 "Successful" 2 "Failed" 3 "Reserved" ;
VAL_ 54 TBOX_CtrlReMirrReq 0 "without_control" 1 "Unfold_rear-view_mirror" 2 "Folding_rear-view_mirrors" 3 "Invalid_value" ;
VAL_ 54 TBOX_eCallMuteSt 0 "No_actiont" 1 "EcallUnmute" 2 "AutomaticEcallMute" 3 "ManualEcallMute" ;
VAL_ 54 TBOX_RemReScrnHeatgCmd 0 "No_Req_/_Stop_heating" 1 "Heating_Req" 2 "Reserved" 3 "Invalid" ;
VAL_ 54 TBOX_eCallSt 0 "eCall_Standby" 1 "eCall_in_Testmode" 2 "eCall_FAILURE" 3 "eCall_DEACTIVATED" 4 "eCall_Active_manual_triggered" 5 "eCall_Active_automatic_triggered" 6 "Reserved" 7 "Reserved" ;
VAL_ 88 TBOX_RemClsWin_RW_CtrlCmd 126 "No_operation" 127 "Invalid" ;
VAL_ 88 TBOX_California_mode 0 "INIT" 1 "ON" 2 "OFF" 3 "INVALID" ;
VAL_ 88 TBOX_RemClsSunroofCtrlCmd 127 "Invalid" ;
VAL_ 89 ACU_FrntCrashOutpSts 0 "no_crash,_level_0" 1 "front_crash_low,_level_1" 2 "front_crash_high,_level_2" 3 "unused" 4 "unused" 5 "unused" 6 "unused" 7 "invalid" ;
VAL_ 89 ACU_RiSideCrashOutpSts 0 "no_crash,_level_0" 1 "right_side_crash_high,_level_2" 2 "unused" 3 "invalid" ;
VAL_ 89 ACU_LeSideCrashOutpSts 0 "no_crash,_level_0" 1 "left_side_crash_high,_level_2" 2 "unused" 3 "invalid" ;
VAL_ 89 ACU_RearCrashOutpSts 0 "no_crash,_level_0" 1 "rear_crash_high,_level_2" 2 "unused" 3 "invalid" ;
VAL_ 89 ACU_RollovrCrashOutpSts 0 "no_crash,_level_0" 1 "rollover_crash,_level_2" 2 "unused" 3 "invalid" ;
VAL_ 89 ACU_Crash_cfm 0 "no_crash" 1 "crash_happened" 2 "not_used" 3 "invalid" ;
VAL_ 121 TBOX_LrnFbInfoClassn 0 "Reserved" 1 "Report_TBOX_Learning_Status" 2 "Reserved" 3 "Reserved" 4 "Reserved" 5 "Response_To_Set_Learnt_Command" 6 "Reserved" 7 "Reserved" 8 "Reserved" 9 "Reserved" 10 "Reserved" 11 "Reserved" 12 "Reserved" 13 "Reserved" 14 "Reserved" 15 "Reserved" 16 "Reserved" 17 "Reserved" 18 "Reserved" 19 "Reserved" 20 "Reserved" 21 "Reserved" 22 "Reserved" 23 "Reserved" 24 "Reserved" 25 "Reserved" 26 "Reserved" 27 "Reserved" 28 "Reserved" 29 "Reserved" 30 "Reserved" 31 "Reserved" 32 "Reserved" 33 "Reserved" 34 "Reserved" 35 "Reserved" 36 "Reserved" 37 "Reserved" 38 "Reserved" 39 "Reserved" 40 "Reserved" 41 "Reserved" 42 "Reserved" 43 "Reserved" 44 "Reserved" 45 "Reserved" 46 "Reserved" 47 "Reserved" 48 "Reserved" 49 "Reserved" 50 "Reserved" 51 "Reserved" 52 "Reserved" 53 "Reserved" 54 "Reserved" 55 "Reserved" 56 "Reserved" 57 "Reserved" 58 "Reserved" 59 "Reserved" 60 "Reserved" 61 "Reserved" 62 "Reserved" 63 "Reserved" 64 "Reserved" 65 "Reserved" 66 "Reserved" 67 "Reserved" 68 "Reserved" 69 "Reserved" 70 "Reserved" 71 "Reserved" 72 "Reserved" 73 "Reserved" 74 "Reserved" 75 "Reserved" 76 "Reserved" 77 "Reserved" 78 "Reserved" 79 "Reserved" 80 "Reserved" 81 "Reserved" 82 "Reserved" 83 "Reserved" 84 "Reserved" 85 "Reserved" 86 "Reserved" 87 "Reserved" 88 "Reserved" 89 "Reserved" 90 "Reserved" 91 "Reserved" 92 "Reserved" 93 "Reserved" 94 "Reserved" 95 "Reserved" 96 "Reserved" 97 "Reserved" 98 "Reserved" 99 "Reserved" 100 "Reserved" 101 "Reserved" 102 "Reserved" 103 "Reserved" 104 "Reserved" 105 "Reserved" 106 "Reserved" 107 "Reserved" 108 "Reserved" 109 "Reserved" 110 "Reserved" 111 "Reserved" 112 "Reserved" 113 "Reserved" 114 "Reserved" 115 "Reserved" 116 "Reserved" 117 "Reserved" 118 "Reserved" 119 "Reserved" 120 "Reserved" 121 "Reserved" 122 "Reserved" 123 "Reserved" 124 "Reserved" 125 "Reserved" 126 "Reserved" 127 "Reserved" 128 "Reserved" 129 "Reserved" 130 "Reserved" 131 "Reserved" 132 "Reserved" 133 "Reserved" 134 "Reserved" 135 "Reserved" 136 "Reserved" 137 "Reserved" 138 "Reserved" 139 "Reserved" 140 "Reserved" 141 "Reserved" 142 "Reserved" 143 "Reserved" 144 "Reserved" 145 "Reserved" 146 "Reserved" 147 "Reserved" 148 "Reserved" 149 "Reserved" 150 "Reserved" 151 "Reserved" 152 "Reserved" 153 "Reserved" 154 "Reserved" 155 "Reserved" 156 "Reserved" 157 "Reserved" 158 "Reserved" 159 "Reserved" 160 "Reserved" 161 "Reserved" 162 "Reserved" 163 "Reserved" 164 "Reserved" 165 "Reserved" 166 "Reserved" 167 "Reserved" 168 "Reserved" 169 "Reserved" 170 "Reserved" 171 "Reserved" 172 "Reserved" 173 "Reserved" 174 "Reserved" 175 "Reserved" 176 "Reserved" 177 "Reserved" 178 "Reserved" 179 "Reserved" 180 "Reserved" 181 "Reserved" 182 "Reserved" 183 "Reserved" 184 "Reserved" 185 "Reserved" 186 "Reserved" 187 "Reserved" 188 "Reserved" 189 "Reserved" 190 "Reserved" 191 "Reserved" 192 "Reserved" 193 "Reserved" 194 "Reserved" 195 "Reserved" 196 "Reserved" 197 "Reserved" 198 "Reserved" 199 "Reserved" 200 "Reserved" 201 "Reserved" 202 "Reserved" 203 "Reserved" 204 "Reserved" 205 "Reserved" 206 "Reserved" 207 "Reserved" 208 "Reserved" 209 "Reserved" 210 "Reserved" 211 "Reserved" 212 "Reserved" 213 "Reserved" 214 "Reserved" 215 "Reserved" 216 "Reserved" 217 "Reserved" 218 "Reserved" 219 "Reserved" 220 "Reserved" 221 "Reserved" 222 "Reserved" 223 "Reserved" 224 "Reserved" 225 "Reserved" 226 "Reserved" 227 "Reserved" 228 "Reserved" 229 "Reserved" 230 "Reserved" 231 "Reserved" 232 "Reserved" 233 "Reserved" 234 "Reserved" 235 "Reserved" 236 "Reserved" 237 "Reserved" 238 "Reserved" 239 "Reserved" 240 "Reserved" 241 "Reserved" 242 "Reserved" 243 "Reserved" 244 "Reserved" 245 "Reserved" 246 "Reserved" 247 "Reserved" 248 "Reserved" 249 "Reserved" 250 "Reserved" 251 "Reserved" 252 "Reserved" 253 "Reserved" 254 "Reserved" 255 "Reserved" ;
VAL_ 121 TBOX_LrngSts 0 "TBOX_Virgin" 1 "TBOX_Learnt" 2 "Reserved" 3 "Reserved" 4 "Reserved" 5 "Reserved" 6 "Reserved" 7 "Reserved" 8 "Reserved" 9 "Reserved" 10 "Reserved" 11 "Reserved" 12 "Reserved" 13 "Reserved" 14 "Reserved" 15 "Reserved" 16 "Reserved" 17 "Reserved" 18 "Reserved" 19 "Reserved" 20 "Reserved" 21 "Reserved" 22 "Reserved" 23 "Reserved" 24 "Reserved" 25 "Reserved" 26 "Reserved" 27 "Reserved" 28 "Reserved" 29 "Reserved" 30 "Reserved" 31 "Reserved" 32 "Reserved" 33 "Reserved" 34 "Reserved" 35 "Reserved" 36 "Reserved" 37 "Reserved" 38 "Reserved" 39 "Reserved" 40 "Reserved" 41 "Reserved" 42 "Reserved" 43 "Reserved" 44 "Reserved" 45 "Reserved" 46 "Reserved" 47 "Reserved" 48 "Reserved" 49 "Reserved" 50 "Reserved" 51 "Reserved" 52 "Reserved" 53 "Reserved" 54 "Reserved" 55 "Reserved" 56 "Reserved" 57 "Reserved" 58 "Reserved" 59 "Reserved" 60 "Reserved" 61 "Reserved" 62 "Reserved" 63 "Reserved" 64 "Reserved" 65 "Reserved" 66 "Reserved" 67 "Reserved" 68 "Reserved" 69 "Reserved" 70 "Reserved" 71 "Reserved" 72 "Reserved" 73 "Reserved" 74 "Reserved" 75 "Reserved" 76 "Reserved" 77 "Reserved" 78 "Reserved" 79 "Reserved" 80 "Reserved" 81 "Reserved" 82 "Reserved" 83 "Reserved" 84 "Reserved" 85 "Reserved" 86 "Reserved" 87 "Reserved" 88 "Reserved" 89 "Reserved" 90 "Reserved" 91 "Reserved" 92 "Reserved" 93 "Reserved" 94 "Reserved" 95 "Reserved" 96 "Reserved" 97 "Reserved" 98 "Reserved" 99 "Reserved" 100 "Reserved" 101 "Reserved" 102 "Reserved" 103 "Reserved" 104 "Reserved" 105 "Reserved" 106 "Reserved" 107 "Reserved" 108 "Reserved" 109 "Reserved" 110 "Reserved" 111 "Reserved" 112 "Reserved" 113 "Reserved" 114 "Reserved" 115 "Reserved" 116 "Reserved" 117 "Reserved" 118 "Reserved" 119 "Reserved" 120 "Reserved" 121 "Reserved" 122 "Reserved" 123 "Reserved" 124 "Reserved" 125 "Reserved" 126 "Reserved" 127 "Reserved" 128 "Reserved" 129 "Reserved" 130 "Reserved" 131 "Reserved" 132 "Reserved" 133 "Reserved" 134 "Reserved" 135 "Reserved" 136 "Reserved" 137 "Reserved" 138 "Reserved" 139 "Reserved" 140 "Reserved" 141 "Reserved" 142 "Reserved" 143 "Reserved" 144 "Reserved" 145 "Reserved" 146 "Reserved" 147 "Reserved" 148 "Reserved" 149 "Reserved" 150 "Reserved" 151 "Reserved" 152 "Reserved" 153 "Reserved" 154 "Reserved" 155 "Reserved" 156 "Reserved" 157 "Reserved" 158 "Reserved" 159 "Reserved" 160 "Reserved" 161 "Reserved" 162 "Reserved" 163 "Reserved" 164 "Reserved" 165 "Reserved" 166 "Reserved" 167 "Reserved" 168 "Reserved" 169 "Reserved" 170 "Reserved" 171 "Reserved" 172 "Reserved" 173 "Reserved" 174 "Reserved" 175 "Reserved" 176 "Reserved" 177 "Reserved" 178 "Reserved" 179 "Reserved" 180 "Reserved" 181 "Reserved" 182 "Reserved" 183 "Reserved" 184 "Reserved" 185 "Reserved" 186 "Reserved" 187 "Reserved" 188 "Reserved" 189 "Reserved" 190 "Reserved" 191 "Reserved" 192 "Reserved" 193 "Reserved" 194 "Reserved" 195 "Reserved" 196 "Reserved" 197 "Reserved" 198 "Reserved" 199 "Reserved" 200 "Reserved" 201 "Reserved" 202 "Reserved" 203 "Reserved" 204 "Reserved" 205 "Reserved" 206 "Reserved" 207 "Reserved" 208 "Reserved" 209 "Reserved" 210 "Reserved" 211 "Reserved" 212 "Reserved" 213 "Reserved" 214 "Reserved" 215 "Reserved" 216 "Reserved" 217 "Reserved" 218 "Reserved" 219 "Reserved" 220 "Reserved" 221 "Reserved" 222 "Reserved" 223 "Reserved" 224 "Reserved" 225 "Reserved" 226 "Reserved" 227 "Reserved" 228 "Reserved" 229 "Reserved" 230 "Reserved" 231 "Reserved" 232 "Reserved" 233 "Reserved" 234 "Reserved" 235 "Reserved" 236 "Reserved" 237 "Reserved" 238 "Reserved" 239 "Reserved" 240 "Reserved" 241 "Reserved" 242 "Reserved" 243 "Reserved" 244 "Reserved" 245 "Reserved" 246 "Reserved" 247 "Reserved" 248 "Reserved" 249 "Reserved" 250 "Reserved" 251 "Reserved" 252 "Reserved" 253 "Reserved" 254 "Reserved" 255 "Reserved" ;
VAL_ 122 TBOX_LrngSubID_7A 0 "Reserved" 1 "Report_TBOX_LearningST" 2 "Share_FF_Of_SKC_And_SC" 3 "Share_SF_Of_SKC_And_SC" 4 "Share_3rd_F_Of_SKC_And_SC" 5 "Response_To_Set_Learnt_Command" 6 "Postive_Reply_SC" 7 "Reserved" 8 "Reserved" 9 "Reserved" 10 "Reserved" 11 "Reserved" 12 "Reserved" 13 "Reserved" 14 "Reserved" 15 "Reserved" 16 "Reserved" 17 "Reserved" 18 "Reserved" 19 "Reserved" 20 "Reserved" 21 "Reserved" 22 "Reserved" 23 "Reserved" 24 "Reserved" 25 "Reserved" 26 "Reserved" 27 "Reserved" 28 "Reserved" 29 "Reserved" 30 "Reserved" 31 "Reserved" 32 "Reserved" 33 "Reserved" 34 "Reserved" 35 "Reserved" 36 "Reserved" 37 "Reserved" 38 "Reserved" 39 "Reserved" 40 "Reserved" 41 "Reserved" 42 "Reserved" 43 "Reserved" 44 "Reserved" 45 "Reserved" 46 "Reserved" 47 "Reserved" 48 "Reserved" 49 "Reserved" 50 "Reserved" 51 "Reserved" 52 "Reserved" 53 "Reserved" 54 "Reserved" 55 "Reserved" 56 "Reserved" 57 "Reserved" 58 "Reserved" 59 "Reserved" 60 "Reserved" 61 "Reserved" 62 "Reserved" 63 "Reserved" 64 "Reserved" 65 "Reserved" 66 "Reserved" 67 "Reserved" 68 "Reserved" 69 "Reserved" 70 "Reserved" 71 "Reserved" 72 "Reserved" 73 "Reserved" 74 "Reserved" 75 "Reserved" 76 "Reserved" 77 "Reserved" 78 "Reserved" 79 "Reserved" 80 "Reserved" 81 "Reserved" 82 "Reserved" 83 "Reserved" 84 "Reserved" 85 "Reserved" 86 "Reserved" 87 "Reserved" 88 "Reserved" 89 "Reserved" 90 "Reserved" 91 "Reserved" 92 "Reserved" 93 "Reserved" 94 "Reserved" 95 "Reserved" 96 "Reserved" 97 "Reserved" 98 "Reserved" 99 "Reserved" 100 "Reserved" 101 "Reserved" 102 "Reserved" 103 "Reserved" 104 "Reserved" 105 "Reserved" 106 "Reserved" 107 "Reserved" 108 "Reserved" 109 "Reserved" 110 "Reserved" 111 "Reserved" 112 "Reserved" 113 "Reserved" 114 "Reserved" 115 "Reserved" 116 "Reserved" 117 "Reserved" 118 "Reserved" 119 "Reserved" 120 "Reserved" 121 "Reserved" 122 "Reserved" 123 "Reserved" 124 "Reserved" 125 "Reserved" 126 "Reserved" 127 "Reserved" 128 "Reserved" 129 "Reserved" 130 "Reserved" 131 "Reserved" 132 "Reserved" 133 "Reserved" 134 "Reserved" 135 "Reserved" 136 "Reserved" 137 "Reserved" 138 "Reserved" 139 "Reserved" 140 "Reserved" 141 "Reserved" 142 "Reserved" 143 "Reserved" 144 "Reserved" 145 "Reserved" 146 "Reserved" 147 "Reserved" 148 "Reserved" 149 "Reserved" 150 "Reserved" 151 "Reserved" 152 "Reserved" 153 "Reserved" 154 "Reserved" 155 "Reserved" 156 "Reserved" 157 "Reserved" 158 "Reserved" 159 "Reserved" 160 "Reserved" 161 "Reserved" 162 "Reserved" 163 "Reserved" 164 "Reserved" 165 "Reserved" 166 "Reserved" 167 "Reserved" 168 "Reserved" 169 "Reserved" 170 "Reserved" 171 "Reserved" 172 "Reserved" 173 "Reserved" 174 "Reserved" 175 "Reserved" 176 "Reserved" 177 "Reserved" 178 "Reserved" 179 "Reserved" 180 "Reserved" 181 "Reserved" 182 "Reserved" 183 "Reserved" 184 "Reserved" 185 "Reserved" 186 "Reserved" 187 "Reserved" 188 "Reserved" 189 "Reserved" 190 "Reserved" 191 "Reserved" 192 "Reserved" 193 "Reserved" 194 "Reserved" 195 "Reserved" 196 "Reserved" 197 "Reserved" 198 "Reserved" 199 "Reserved" 200 "Reserved" 201 "Reserved" 202 "Reserved" 203 "Reserved" 204 "Reserved" 205 "Reserved" 206 "Reserved" 207 "Reserved" 208 "Reserved" 209 "Reserved" 210 "Reserved" 211 "Reserved" 212 "Reserved" 213 "Reserved" 214 "Reserved" 215 "Reserved" 216 "Reserved" 217 "Reserved" 218 "Reserved" 219 "Reserved" 220 "Reserved" 221 "Reserved" 222 "Reserved" 223 "Reserved" 224 "Reserved" 225 "Reserved" 226 "Reserved" 227 "Reserved" 228 "Reserved" 229 "Reserved" 230 "Reserved" 231 "Reserved" 232 "Reserved" 233 "Reserved" 234 "Reserved" 235 "Reserved" 236 "Reserved" 237 "Reserved" 238 "Reserved" 239 "Reserved" 240 "Reserved" 241 "Reserved" 242 "Reserved" 243 "Reserved" 244 "Reserved" 245 "Reserved" 246 "Reserved" 247 "Reserved" 248 "Reserved" 249 "Reserved" 250 "Reserved" 251 "Reserved" 252 "Reserved" 253 "Reserved" 254 "Reserved" 255 "Reserved" ;
VAL_ 147 VCU_93_AliveCounter 0 "NotActive" 1 "Active" ;
VAL_ 147 VCU_EmgyShutOff 0 "NotActive" 1 "Active" ;
VAL_ 147 VCU_IsolationMonitor_Rq 0 "NotActive" 1 "Active" ;
VAL_ 147 VCU_Set_Chrg_Mod 0 "Undefined" 1 "NO_Charging_NoChargerisConnected" 2 "AC_Charging_ACChargerisActive" 3 "DC_Charging_DCChargerisConnected" ;
VAL_ 147 VCU_Set_BMS_Mod 0 "Undefined(SignalValueUndefined)" 1 "BMS_ActiveSet_BMStoActiveMode_WhereitisAWakeAndOperating" 2 "BMS_SLEEP_SetBMStoSleepMode" 3 "Reserved" ;
VAL_ 147 VCU_HVBActivateDeactivateRq 0 "Undefined_SignalValueUndefined" 1 "HV_Off_BatteryShouldbeDisConnected" 2 "HV_ON_BatteryShouldbeConnected" ;
VAL_ 147 VCU_Set_Balc_Mod 0 "Undefined" 1 "BALANCING_Off_BalancingisforbiddenByVCU" 2 "BALANCING_ON_BalancingisallowedByVCU" ;
VAL_ 235 BMS_ErrorWarning_OverChargeCurre 0 "WarningNotActive" 1 "Warning" ;
VAL_ 235 BMS_ErrorActive_OverChargeCurren 0 "ErrorNotActive" 1 "Error" ;
VAL_ 235 BMS_ErrorWarning_OverDischargeCu 0 "WarningNotActive" 1 "Warning" ;
VAL_ 235 BMS_ErrorActive_OverDischargeCur 0 "ErrorNotActive" 1 "Error" ;
VAL_ 235 BMS_ErrorWarning_ChargePowerLimi 0 "WarningNotActive" 1 "Warning" ;
VAL_ 235 BMS_ErrorActive_ChargePowerLimit 0 "ErrorNotActive" 1 "Error" ;
VAL_ 235 BMS_ErrorWarning_DischargePowerL 0 "WarningNotActive" 1 "Warning" ;
VAL_ 235 BMS_ErrorActive_DischargePowerLi 0 "ErrorNotActive" 1 "Error" ;
VAL_ 235 BMS_ErrorWarning_SOC_Low 0 "WarningNotActive" 1 "Warning" ;
VAL_ 235 BMS_ErrorActive_SOC_Low 0 "ErrorNotActive" 1 "Error" ;
VAL_ 235 BMS_ErrorWarning_Iso 0 "WarningNotActive" 1 "Warning" ;
VAL_ 235 BMS_ErrorActive_Iso_Crit 0 "ErrorNotActive" 1 "Error" ;
VAL_ 235 BMS_ErrorActive_AbsChargeCurrent 0 "ErrorNotActive" 1 "Error" ;
VAL_ 235 BMS_ErrorActive_AbsDischargeCurr 0 "ErrorNotActive" 1 "Error" ;
VAL_ 235 BMS_ErrorActive_AbsChargePowerLi 0 "ErrorNotActive" 1 "Error" ;
VAL_ 235 BMS_ErrorActive_AbsDischargePowe 0 "ErrorNotActive" 1 "Error" ;
VAL_ 235 BMS_ErrorWarning_overcurrent_Pre 0 "WarningNotActive" 1 "Warning" ;
VAL_ 235 BMS_ErrorActive_ServState 0 "ErrorNotActive" 1 "Error" ;
VAL_ 235 BMS_SystemError_KL30C 0 "ErrorNotActive" 1 "Error" ;
VAL_ 235 BMS_SystemError_OmmissionOfKL15 0 "ErrorNotActive" 1 "Error" ;
VAL_ 235 BMS_SystemError_HV_Interlock 0 "ErrorNotActive" 1 "Error" ;
VAL_ 235 BMS_SystemError_HV_Fuse 0 "ErrorNotActive" 1 "Error" ;
VAL_ 235 BMS_CommError_CommFailure 0 "ErrorNotActive" 1 "Error" ;
VAL_ 235 BMS_CommWarning_PEC_High 0 "WarningNotActive" 1 "Warning" ;
VAL_ 235 BMS_CommError_PEC_High 0 "ErrorNotActive" 1 "Error" ;
VAL_ 235 BMS_HVlinkError_VCU_Comm_Failure 0 "ErrorNotActive" 1 "Error" ;
VAL_ 235 BMS_HVlinkError_Iso_Dev 0 "ErrorNotActive" 1 "Error" ;
VAL_ 235 BMS_HVlinkError_Iso_Dig_Sig 0 "ErrorNotActive" 1 "Error" ;
VAL_ 235 BMS_HVlinkError_ContactorWelded 0 "ErrorNotActive" 1 "Error" ;
VAL_ 235 BMS_HVlinkError_HV_Interlock_Bad 0 "ErrorNotActive" 1 "Error" ;
VAL_ 235 BMS_HardwareError_LCM_General_Fa 0 "ErrorNotActive" 1 "Error" ;
VAL_ 235 BMS_SoftwareError_General_Failr 0 "ErrorNotActive" 1 "Error" ;
VAL_ 235 BMS_ErrorWarning_CellOverVoltage 0 "WarningNotActive" 1 "Warning" ;
VAL_ 235 BMS_ErrorActive_CellOverVoltage 0 "ErrorNotActive" 1 "Error" ;
VAL_ 235 BMS_ErrorWarning_CellUnderVoltag 0 "WarningNotActive" 1 "Warning" ;
VAL_ 235 BMS_ErrorActive_CellUnderVoltage 0 "ErrorNotActive" 1 "Error" ;
VAL_ 235 BMS_ErrorWarning_CellTempHigh 0 "WarningNotActive" 1 "Warning" ;
VAL_ 235 BMS_ErrorActive_CellTempHigh 0 "ErrorNotActive" 1 "Error" ;
VAL_ 235 BMS_ErrorWarning_CellTempLow 0 "WarningNotActive" 1 "Warning" ;
VAL_ 235 BMS_ErrorActive_CellTempLow 0 "ErrorNotActive" 1 "Error" ;
VAL_ 235 BMS_ErrorWarning_HV_OverVoltage 0 "WarningNotActive" 1 "Warning" ;
VAL_ 235 BMS_ErrorActive_HV_OverVoltage 0 "ErrorNotActive" 1 "Error" ;
VAL_ 235 BMS_ErrorWarning_HV_UnderVoltage 0 "WarningNotActive" 1 "Warning" ;
VAL_ 235 BMS_ErrorActive_HV_UnderVoltage 0 "ErrorNotActive" 1 "Error" ;
VAL_ 235 BMS_PVIU_CANcommError 0 "ErrorNotActive" 1 "Error" ;
VAL_ 237 BMS_OperationStates 0 "BMS_Undefined" 1 "BMS_BOOT" 2 "BMS_PRE_OperatIONAL" 3 "BMS_OperatIONAL" 4 "BMS_PRE_SLEEP" 5 "BMS_Config" ;
VAL_ 237 BMS_BallancingStatus 0 "BMS_BALC_DEActivATED" 1 "BMS_BALC_IDLE" 2 "BMS_BALC_Start" 3 "BMS_BALC_OperatIONAL" 4 "BMS_BALC_STOP" 5 "BMS_BALC_RELAXATION" 15 "BMS_BALC_Undefined" ;
VAL_ 237 BMS_ErrorCategory_CAT0 0 "CATOK" 1 "CATFailure" ;
VAL_ 237 BMS_ErrorCategory_CAT1 0 "CATOK" 1 "CATFailure" ;
VAL_ 237 BMS_ErrorCategory_CAT2 0 "CATOK" 1 "CATFailure" ;
VAL_ 237 BMS_ErrorCategory_CAT3 0 "CATOK" 1 "CATFailure" ;
VAL_ 237 BMS_ErrorCategory_CAT4 0 "CATOK" 1 "CATFailure" ;
VAL_ 237 BMS_ErrorCategory_CAT5 0 "CATOK" 1 "CATFailure" ;
VAL_ 237 BMS_ErrorCategory_CAT6 0 "CATOK" 1 "CATFailure" ;
VAL_ 237 BMS_ErrorCategory_CAT7 0 "CATOK" 1 "CATFailure" ;
VAL_ 237 BMS_ErrorCategory_CAT8 0 "CATOK" 1 "CATFailure" ;
VAL_ 237 BMS_HardwareStatus_OK 0 "InitFail" 1 "OK" ;
VAL_ 237 BMS_ErrorCategory_Mem_Empty 0 "InitFail" 1 "OK" ;
VAL_ 237 BMS_ConfigurationStatus_OK 0 "InitFail" 1 "OK" ;
VAL_ 237 BMS_MeasurementModules_OK 0 "InitFail" 1 "OK" ;
VAL_ 237 BMS_BatteryGeneralStatus_OK 0 "InitFail" 1 "OK" ;
VAL_ 237 BMS_SDIL_Sts 0 "Off" 1 "On" ;
VAL_ 237 BMS_CL30C_Sts 0 "Off" 1 "On" ;
VAL_ 237 BMS_CL15_Sts 0 "Off" 1 "On" ;
VAL_ 237 BMS_HVIL_OK 0 "InitFail" 1 "OK" ;
VAL_ 237 BMS_HV_ContactorsStatus_OK 0 "InitFail" 1 "OK" ;
VAL_ 237 BMS_SW_Status_OK 0 "InitFail" 1 "OK" ;
VAL_ 237 BMS_CurrentSensor_OK 0 "InitFail" 1 "OK" ;
VAL_ 237 BMS_IsolatoinStatus_OK 0 "InitFail" 1 "OK" ;
VAL_ 237 BMS_StateMAchine_Status 1 "not_used" 2 "BMS_initializing" 3 "BMS_Standby" 4 "BMS_precharging" 5 "HV_active" 6 "not_used" 7 "BMS_HV_OFF_Emergency" 8 "BMS_shutdown" 9 "not_used" 10 "not_used" 11 "not_used" ;
VAL_ 237 BMS_BDU_Status 1 "not_used" 2 "BMS_initializing" 3 "BMS_Standby" 4 "BMS_precharging" 5 "HV_active" 6 "not_used" 7 "BMS_HV_OFF_Emergency" 8 "BMS_shutdown" 9 "not_used" 10 "not_used" 11 "not_used" ;
VAL_ 242 BMS_CL30C_Volt 65535 "Invalid" ;
VAL_ 336 MCU_F_CrtTqVld 0 "Initializing" 1 "Valid" 2 "Invalid" 3 "Reserved" ;
VAL_ 336 MCU_F_CrtRotDir 0 "Standstill" 1 "Forward_rotation_(forward_mode)" 2 "Reverse_(reverse_mode)" 3 "Invalid" ;
VAL_ 336 MCU_F_CrtSpd 65535 "Invalid" ;
VAL_ 336 MCU_F_CrtTq 2047 "Invalid" ;
VAL_ 336 MCU_F_CrtSpdSigVld 0 "Initializing" 1 "Valid" 2 "Invalid" 3 "Reserved" ;
VAL_ 336 MCU_F_CrtMod 0 "Initialization_(function)" 1 "LV_ready" 2 "Standby" 3 "reserved" 4 "Torque_mode" 5 "Speed_control" 6 "reserved" 7 "Internal_inverter_error" 8 "reserved" 9 "Service_job" 10 "Postrun:" 11 "Sleep_Ready" 12 "Reserved" 13 "Reserved" 14 "Init_(dbc_init_value)" 15 "Invalid" ;
VAL_ 336 MCU_F_HVActvDchaSts 0 "Not_discharged" 1 "Discharging" 2 "Discharge_complete" 3 "Discharge_failure" 4 "Reserved" 5 "Reserved" 6 "Init_(dbc_init_value)" 7 "Invalid" ;
VAL_ 336 MCU_F_SlipCtrlActMode 0 "Slip_control_deactivated" 1 "Slip_control_idling" 2 "Slip_control_working" 3 "Fault" ;
VAL_ 336 MCU_F_AlrmLamp_FS 0 "Disable" 1 "Enable" ;
VAL_ 336 MCU_F_HVChkEndFlg 0 "Not_completed" 1 "Completed" ;
VAL_ 337 MCU_R_CrtTqVld 0 "Initializing" 1 "Valid" 2 "Invalid" 3 "Reserved" ;
VAL_ 337 MCU_R_CrtRotDir 0 "Standstill" 1 "Forward_rotation_(forward_mode)" 2 "Reverse_(reverse_mode)" 3 "Invalid" ;
VAL_ 337 MCU_R_CrtSpd 65535 "Invalid" ;
VAL_ 337 MCU_R_CrtTq 2047 "Invalid" ;
VAL_ 337 MCU_R_CrtSpdSigVld 0 "Initializing" 1 "Valid" 2 "Invalid" 3 "Reserved" ;
VAL_ 337 MCU_R_CrtMod 0 "Initialization_(function)" 1 "LV_ready" 2 "Standby" 3 "reserved" 4 "Torque_mode" 5 "Speed_control" 6 "reserved" 7 "Internal_inverter_error" 8 "reserved" 9 "Service_job" 10 "Postrun:" 11 "Sleep_Ready" 12 "Reserved" 13 "Reserved" 14 "Init_(dbc_init_value)" 15 "Invalid" ;
VAL_ 337 MCU_R_Decoup_State 0 "Init" 1 "Disconnect" 2 "Connect_in_progress" 3 "Synchronized" 4 "Connected" 5 "Disconnect_in_progress" 6 "Fault_disconnected" 7 "Fault_connected" 8 "Fault_connect_state_unknown" 9 "Connect_conditions_not_fulfilled" ;
VAL_ 337 MCU_R_HVActvDchaSts 0 "Not_discharged" 1 "Discharging" 2 "Discharge_complete" 3 "Discharge_failure" 4 "Reserved" 5 "Reserved" 6 "Init_(dbc_init_value)" 7 "Invalid" ;
VAL_ 337 MCU_R_SlipCtrlActMode 0 "Slip_control_deactivated" 1 "Slip_control_idling" 2 "Slip_control_working" 3 "Fault" ;
VAL_ 337 MCU_R_AlrmLamp_FS 0 "Disable" 1 "Enable" ;
VAL_ 337 MCU_R_HVChkEndFlg 0 "Not_completed" 1 "Completed" ;
VAL_ 533 BMS_PwrBattOverTFlt_FS 0 "Normal" 1 "Abnormal" ;
VAL_ 533 BMS_PwrBattOverCrtFlt_FS 0 "Normal" 1 "Abnormal" ;
VAL_ 533 BMS_PwrBattNegRlyAdh_FS 0 "Normal" 1 "Abnormal" ;
VAL_ 533 BMS_PwrBattPosRlyAdh_FS 0 "Normal" 1 "Abnormal" ;
VAL_ 533 BMS_CellUnderrVoltFlt_FS 0 "Normal" 1 "Abnormal" ;
VAL_ 533 BMS_PwrBattCellOverVolt_FS 0 "Normal" 1 "Abnormal" ;
VAL_ 533 BMS_BattInlTSnsrFlt 0 "Normal" 1 "Abnormal" ;
VAL_ 533 BMS_BattOutlTSnsrFlt 0 "Normal" 1 "Abnormal" ;
VAL_ 533 BMS_PwrBattPrecRlyAdh_FS 0 "Normal" 1 "Abnormal" ;
VAL_ 533 BMS_AlrmLamp_FS 0 "Normal" 1 "Abnormal" ;
VAL_ 533 BMS_PwrBattLoadTotVoltV3_FS 65535 "Invalid" ;
VAL_ 533 BMS_FctSftyErrCod 0 "Function_safety_mechanism_startup_state_code" 1 "Function_safety_mechanism_startup_state_code" 2 "Function_safety_mechanism_startup_state_code" 3 "Function_safety_mechanism_startup_state_code" 4 "Function_safety_mechanism_startup_state_code" 5 "Function_safety_mechanism_startup_state_code" 6 "Function_safety_mechanism_startup_state_code" 7 "Function_safety_mechanism_startup_state_code" 8 "Function_safety_mechanism_startup_state_code" 9 "Function_safety_mechanism_startup_state_code" 10 "Function_safety_mechanism_startup_state_code" 11 "Function_safety_mechanism_startup_state_code" 12 "Function_safety_mechanism_startup_state_code" 13 "Function_safety_mechanism_startup_state_code" 14 "Function_safety_mechanism_startup_state_code" 15 "Function_safety_mechanism_startup_state_code" 16 "Function_safety_mechanism_startup_state_code" 17 "Function_safety_mechanism_startup_state_code" 18 "Function_safety_mechanism_startup_state_code" 19 "Function_safety_mechanism_startup_state_code" 20 "Function_safety_mechanism_startup_state_code" 21 "Function_safety_mechanism_startup_state_code" 22 "Function_safety_mechanism_startup_state_code" 23 "Function_safety_mechanism_startup_state_code" 24 "Function_safety_mechanism_startup_state_code" 25 "Function_safety_mechanism_startup_state_code" 26 "Function_safety_mechanism_startup_state_code" 27 "Function_safety_mechanism_startup_state_code" 28 "Function_safety_mechanism_startup_state_code" 29 "Function_safety_mechanism_startup_state_code" 30 "Function_safety_mechanism_startup_state_code" 31 "Function_safety_mechanism_startup_state_code" 32 "Function_safety_mechanism_startup_state_code" 33 "Function_safety_mechanism_startup_state_code" 34 "Function_safety_mechanism_startup_state_code" 35 "Function_safety_mechanism_startup_state_code" 36 "Function_safety_mechanism_startup_state_code" 37 "Function_safety_mechanism_startup_state_code" 38 "Function_safety_mechanism_startup_state_code" 39 "Function_safety_mechanism_startup_state_code" 40 "Function_safety_mechanism_startup_state_code" 41 "Function_safety_mechanism_startup_state_code" 42 "Function_safety_mechanism_startup_state_code" 43 "Function_safety_mechanism_startup_state_code" 44 "Function_safety_mechanism_startup_state_code" 45 "Function_safety_mechanism_startup_state_code" 46 "Function_safety_mechanism_startup_state_code" 47 "Function_safety_mechanism_startup_state_code" 48 "Function_safety_mechanism_startup_state_code" 49 "Function_safety_mechanism_startup_state_code" 50 "Function_safety_mechanism_startup_state_code" 51 "Function_safety_mechanism_startup_state_code" 52 "Function_safety_mechanism_startup_state_code" 53 "Function_safety_mechanism_startup_state_code" 54 "Function_safety_mechanism_startup_state_code" 55 "Function_safety_mechanism_startup_state_code" 56 "Function_safety_mechanism_startup_state_code" 57 "Function_safety_mechanism_startup_state_code" 58 "Function_safety_mechanism_startup_state_code" 59 "Function_safety_mechanism_startup_state_code" 60 "Function_safety_mechanism_startup_state_code" 61 "Function_safety_mechanism_startup_state_code" 62 "Function_safety_mechanism_startup_state_code" 63 "Function_safety_mechanism_startup_state_code" 64 "Function_safety_mechanism_startup_state_code" 65 "Function_safety_mechanism_startup_state_code" 66 "Function_safety_mechanism_startup_state_code" 67 "Function_safety_mechanism_startup_state_code" 68 "Function_safety_mechanism_startup_state_code" 69 "Function_safety_mechanism_startup_state_code" 70 "Function_safety_mechanism_startup_state_code" 71 "Function_safety_mechanism_startup_state_code" 72 "Function_safety_mechanism_startup_state_code" 73 "Function_safety_mechanism_startup_state_code" 74 "Function_safety_mechanism_startup_state_code" 75 "Function_safety_mechanism_startup_state_code" 76 "Function_safety_mechanism_startup_state_code" 77 "Function_safety_mechanism_startup_state_code" 78 "Function_safety_mechanism_startup_state_code" 79 "Function_safety_mechanism_startup_state_code" 80 "Function_safety_mechanism_startup_state_code" 81 "Function_safety_mechanism_startup_state_code" 82 "Function_safety_mechanism_startup_state_code" 83 "Function_safety_mechanism_startup_state_code" 84 "Function_safety_mechanism_startup_state_code" 85 "Function_safety_mechanism_startup_state_code" 86 "Function_safety_mechanism_startup_state_code" 87 "Function_safety_mechanism_startup_state_code" 88 "Function_safety_mechanism_startup_state_code" 89 "Function_safety_mechanism_startup_state_code" 90 "Function_safety_mechanism_startup_state_code" 91 "Function_safety_mechanism_startup_state_code" 92 "Function_safety_mechanism_startup_state_code" 93 "Function_safety_mechanism_startup_state_code" 94 "Function_safety_mechanism_startup_state_code" 95 "Function_safety_mechanism_startup_state_code" 96 "Function_safety_mechanism_startup_state_code" 97 "Function_safety_mechanism_startup_state_code" 98 "Function_safety_mechanism_startup_state_code" 99 "Function_safety_mechanism_startup_state_code" 100 "Function_safety_mechanism_startup_state_code" 101 "Function_safety_mechanism_startup_state_code" 102 "Function_safety_mechanism_startup_state_code" 103 "Function_safety_mechanism_startup_state_code" 104 "Function_safety_mechanism_startup_state_code" 105 "Function_safety_mechanism_startup_state_code" 106 "Function_safety_mechanism_startup_state_code" 107 "Function_safety_mechanism_startup_state_code" 108 "Function_safety_mechanism_startup_state_code" 109 "Function_safety_mechanism_startup_state_code" 110 "Function_safety_mechanism_startup_state_code" 111 "Function_safety_mechanism_startup_state_code" 112 "Function_safety_mechanism_startup_state_code" 113 "Function_safety_mechanism_startup_state_code" 114 "Function_safety_mechanism_startup_state_code" 115 "Function_safety_mechanism_startup_state_code" 116 "Function_safety_mechanism_startup_state_code" 117 "Function_safety_mechanism_startup_state_code" 118 "Function_safety_mechanism_startup_state_code" 119 "Function_safety_mechanism_startup_state_code" 120 "Function_safety_mechanism_startup_state_code" 121 "Function_safety_mechanism_startup_state_code" 122 "Function_safety_mechanism_startup_state_code" 123 "Function_safety_mechanism_startup_state_code" 124 "Function_safety_mechanism_startup_state_code" 125 "Function_safety_mechanism_startup_state_code" 126 "Function_safety_mechanism_startup_state_code" 127 "Function_safety_mechanism_startup_state_code" 128 "Function_safety_mechanism_startup_state_code" 129 "Function_safety_mechanism_startup_state_code" 130 "Function_safety_mechanism_startup_state_code" 131 "Function_safety_mechanism_startup_state_code" 132 "Function_safety_mechanism_startup_state_code" 133 "Function_safety_mechanism_startup_state_code" 134 "Function_safety_mechanism_startup_state_code" 135 "Function_safety_mechanism_startup_state_code" 136 "Function_safety_mechanism_startup_state_code" 137 "Function_safety_mechanism_startup_state_code" 138 "Function_safety_mechanism_startup_state_code" 139 "Function_safety_mechanism_startup_state_code" 140 "Function_safety_mechanism_startup_state_code" 141 "Function_safety_mechanism_startup_state_code" 142 "Function_safety_mechanism_startup_state_code" 143 "Function_safety_mechanism_startup_state_code" 144 "Function_safety_mechanism_startup_state_code" 145 "Function_safety_mechanism_startup_state_code" 146 "Function_safety_mechanism_startup_state_code" 147 "Function_safety_mechanism_startup_state_code" 148 "Function_safety_mechanism_startup_state_code" 149 "Function_safety_mechanism_startup_state_code" 150 "Function_safety_mechanism_startup_state_code" 151 "Function_safety_mechanism_startup_state_code" 152 "Function_safety_mechanism_startup_state_code" 153 "Function_safety_mechanism_startup_state_code" 154 "Function_safety_mechanism_startup_state_code" 155 "Function_safety_mechanism_startup_state_code" 156 "Function_safety_mechanism_startup_state_code" 157 "Function_safety_mechanism_startup_state_code" 158 "Function_safety_mechanism_startup_state_code" 159 "Function_safety_mechanism_startup_state_code" 160 "Function_safety_mechanism_startup_state_code" 161 "Function_safety_mechanism_startup_state_code" 162 "Function_safety_mechanism_startup_state_code" 163 "Function_safety_mechanism_startup_state_code" 164 "Function_safety_mechanism_startup_state_code" 165 "Function_safety_mechanism_startup_state_code" 166 "Function_safety_mechanism_startup_state_code" 167 "Function_safety_mechanism_startup_state_code" 168 "Function_safety_mechanism_startup_state_code" 169 "Function_safety_mechanism_startup_state_code" 170 "Function_safety_mechanism_startup_state_code" 171 "Function_safety_mechanism_startup_state_code" 172 "Function_safety_mechanism_startup_state_code" 173 "Function_safety_mechanism_startup_state_code" 174 "Function_safety_mechanism_startup_state_code" 175 "Function_safety_mechanism_startup_state_code" 176 "Function_safety_mechanism_startup_state_code" 177 "Function_safety_mechanism_startup_state_code" 178 "Function_safety_mechanism_startup_state_code" 179 "Function_safety_mechanism_startup_state_code" 180 "Function_safety_mechanism_startup_state_code" 181 "Function_safety_mechanism_startup_state_code" 182 "Function_safety_mechanism_startup_state_code" 183 "Function_safety_mechanism_startup_state_code" 184 "Function_safety_mechanism_startup_state_code" 185 "Function_safety_mechanism_startup_state_code" 186 "Function_safety_mechanism_startup_state_code" 187 "Function_safety_mechanism_startup_state_code" 188 "Function_safety_mechanism_startup_state_code" 189 "Function_safety_mechanism_startup_state_code" 190 "Function_safety_mechanism_startup_state_code" 191 "Function_safety_mechanism_startup_state_code" 192 "Function_safety_mechanism_startup_state_code" 193 "Function_safety_mechanism_startup_state_code" 194 "Function_safety_mechanism_startup_state_code" 195 "Function_safety_mechanism_startup_state_code" 196 "Function_safety_mechanism_startup_state_code" 197 "Function_safety_mechanism_startup_state_code" 198 "Function_safety_mechanism_startup_state_code" 199 "Function_safety_mechanism_startup_state_code" 200 "Function_safety_mechanism_startup_state_code" 201 "Function_safety_mechanism_startup_state_code" 202 "Function_safety_mechanism_startup_state_code" 203 "Function_safety_mechanism_startup_state_code" 204 "Function_safety_mechanism_startup_state_code" 205 "Function_safety_mechanism_startup_state_code" 206 "Function_safety_mechanism_startup_state_code" 207 "Function_safety_mechanism_startup_state_code" 208 "Function_safety_mechanism_startup_state_code" 209 "Function_safety_mechanism_startup_state_code" 210 "Function_safety_mechanism_startup_state_code" 211 "Function_safety_mechanism_startup_state_code" 212 "Function_safety_mechanism_startup_state_code" 213 "Function_safety_mechanism_startup_state_code" 214 "Function_safety_mechanism_startup_state_code" 215 "Function_safety_mechanism_startup_state_code" 216 "Function_safety_mechanism_startup_state_code" 217 "Function_safety_mechanism_startup_state_code" 218 "Function_safety_mechanism_startup_state_code" 219 "Function_safety_mechanism_startup_state_code" 220 "Function_safety_mechanism_startup_state_code" 221 "Function_safety_mechanism_startup_state_code" 222 "Function_safety_mechanism_startup_state_code" 223 "Function_safety_mechanism_startup_state_code" 224 "Function_safety_mechanism_startup_state_code" 225 "Function_safety_mechanism_startup_state_code" 226 "Function_safety_mechanism_startup_state_code" 227 "Function_safety_mechanism_startup_state_code" 228 "Function_safety_mechanism_startup_state_code" 229 "Function_safety_mechanism_startup_state_code" 230 "Function_safety_mechanism_startup_state_code" 231 "Function_safety_mechanism_startup_state_code" 232 "Function_safety_mechanism_startup_state_code" 233 "Function_safety_mechanism_startup_state_code" 234 "Function_safety_mechanism_startup_state_code" 235 "Function_safety_mechanism_startup_state_code" 236 "Function_safety_mechanism_startup_state_code" 237 "Function_safety_mechanism_startup_state_code" 238 "Function_safety_mechanism_startup_state_code" 239 "Function_safety_mechanism_startup_state_code" 240 "Function_safety_mechanism_startup_state_code" 241 "Function_safety_mechanism_startup_state_code" 242 "Function_safety_mechanism_startup_state_code" 243 "Function_safety_mechanism_startup_state_code" 244 "Function_safety_mechanism_startup_state_code" 245 "Function_safety_mechanism_startup_state_code" 246 "Function_safety_mechanism_startup_state_code" 247 "Function_safety_mechanism_startup_state_code" 248 "Function_safety_mechanism_startup_state_code" 249 "Function_safety_mechanism_startup_state_code" 250 "Function_safety_mechanism_startup_state_code" 251 "Function_safety_mechanism_startup_state_code" 252 "Function_safety_mechanism_startup_state_code" 253 "Function_safety_mechanism_startup_state_code" 254 "Function_safety_mechanism_startup_state_code" 255 "Invalid" ;
VAL_ 608 VCU_VehChrgDchgMod 0 "Initial_value" 1 "DC_charging" 2 "VTOL_discharging" 3 "VTOV_discharging" 4 "AC_charging" 5 "V2L_trunk_active" 6 "Reserved" 7 "Invalid" ;
VAL_ 608 VCU_DCRlyCtrlCmd 0 "Open" 1 "Close" ;
VAL_ 608 VCU_ChrgSysOperCmd 0 "Initial_value" 1 "Standby" 2 "Working_mode" 3 "Power_mode" 4 "Shutdown" 5 "Sleep" 6 "Reserved" 7 "Invalid" ;
VAL_ 608 VCU_ChrgSts 0 "Initial_value" 1 "Connected_but_not_charging" 2 "AC_charging" 3 "DC_charging" 4 "Charging_completed" 5 "Charging_fault" 6 "Reserved" 7 "Invalid" ;
VAL_ 627 TBOX_ScheduleCharg_End_Mins 63 "Invalid" ;
VAL_ 627 TBOX_ScheduleCharg_Start_Hr 31 "Invalid" ;
VAL_ 627 TBOX_ScheduleCharg_End_Hr 31 "Invalid" ;
VAL_ 627 TBOX_SetSceduleChargTimeFb 0 "Invalid" 1 "Successful" 2 "Failed" 3 "Reserved" ;
VAL_ 627 TBOX_ScheduleCharg_Start_Mins 63 "Invalid" ;
VAL_ 627 TBOX_ScheduleCharg_Status 0 "Description_for_the_value_'0x0'" 1 "Description_for_the_value_'0x1'" 2 "Description_for_the_value_'0x2'" 3 "Description_for_the_value_'0x3'" ;
VAL_ 627 TBOX_V2L_TrEna 0 "No" 1 "Yes" ;
VAL_ 627 TBOX_V2L_ChrgPortEna 0 "No" 1 "Yes" ;
VAL_ 627 TBOX_V2V_Ena 0 "No" 1 "Yes" ;
VAL_ 627 TBOX_V2H_Ena 0 "No" 1 "Yes" ;
VAL_ 627 TBOX_V2G_Ena 0 "No" 1 "Yes" ;
VAL_ 748 BMS_Cont_CurrentState_PV_Pos 0 "RelayClosed" 1 "RelayOpen" ;
VAL_ 748 BMS_Cont_TargetState_PV_Pos 0 "RelayClosed" 1 "RelayOpen" ;
VAL_ 749 BMS_Cont_CurrentState_PV_Neg 0 "RelayClosed" 1 "RelayOpen" ;
VAL_ 749 BMS_Cont_TargetSgtate_PV_Neg 0 "RelayClosed" 1 "RelayOpen" ;
VAL_ 750 BMS_Cont_Act_St_HV_Pos 0 "RelayClosed" 1 "RelayOpen" ;
VAL_ 750 BMS_Cont_Tar_St_HV_Pos 0 "RelayClosed" 1 "RelayOpen" ;
VAL_ 751 BMS_Cont_Act_St_HV_Neg 0 "RelayClosed" 1 "RelayOpen" ;
VAL_ 751 BMS_Cont_Tar_St_HV_Neg 0 "RelayClosed" 1 "RelayOpen" ;
VAL_ 752 BMS_Cont_Act_St_HV_Prec 0 "RelayClosed" 1 "RelayOpen" ;
VAL_ 752 BMS_Cont_Tar_St_HV_Prec 0 "RelayClosed" 1 "RelayOpen" ;
VAL_ 755 BMS_ErrorWarning_CellVoltageDiff 0 "WarningNotActive" 1 "Warning" ;
VAL_ 755 BMS_ErrorActive_CellVoltageDiffO 0 "ErrorNotActive" 1 "Error" ;
VAL_ 755 BMS_ErrorWarning_Diff_U1_UCellSu 0 "WarningNotActive" 1 "Warning" ;
VAL_ 755 BMS_ErrorActive_Diff_U1_UCellSum 0 "ErrorNotActive" 1 "Error" ;
VAL_ 755 BMS_ErrorWarning_SOH_Low 0 "WarningNotActive" 1 "Warning" ;
VAL_ 755 BMS_ErrorActive_SOH_Low 0 "ErrorNotActive" 1 "Error" ;
VAL_ 755 BMS_SystemError_SystemInitFailed 0 "ErrorNotActive" 1 "Error" ;
VAL_ 755 BMS_SystemError_Precharge 0 "ErrorNotActive" 1 "Error" ;
VAL_ 755 BMS_SystemError_HV_CCT_WrongPola 0 "ErrorNotActive" 1 "Error" ;
VAL_ 755 BMS_SystemError_HV_CCT_NoBatVolt 0 "ErrorNotActive" 1 "Error" ;
VAL_ 755 BMS_HVlinkWarning_VCU_MessageInt 0 "WarningNotActive" 1 "Warning" ;
VAL_ 755 BMS_HVlinkError_IVT_Comm_Failure 0 "ErrorNotActive" 1 "Error" ;
VAL_ 755 BMS_HVlinkWarning_IVT_Meas_Failu 0 "WarningNotActive" 1 "Warning" ;
VAL_ 755 BMS_HVlinkError_IVT_Meas_Failure 0 "ErrorNotActive" 1 "Error" ;
VAL_ 755 BMS_HVlinkError_NVM_Comm_Failure 0 "ErrorNotActive" 1 "Error" ;
VAL_ 755 BMS_HVlinkWarning_Eeprom_LifeCyc 0 "WarningNotActive" 1 "Warning" ;
VAL_ 755 BMS_HVlinkError_Eeprom_LifeCycle 0 "ErrorNotActive" 1 "Error" ;
VAL_ 755 BMS_HVlinkError_ContactorGeneric 0 "ErrorNotActive" 1 "Error" ;
VAL_ 755 BMS_HVlinkError_ContactorOpen 0 "ErrorNotActive" 1 "Error" ;
VAL_ 755 BMS_HVlinkError_ContactorAuxFail 0 "ErrorNotActive" 1 "Error" ;
VAL_ 755 BMS_HVlinkError_ContactorPwmEcon 0 "ErrorNotActive" 1 "Error" ;
VAL_ 755 BMS_HVlinkWarning_AnalogInput_Ex 0 "WarningNotActive" 1 "Warning" ;
VAL_ 755 BMS_HVlinkError_AnalogInput_Exce 0 "ErrorNotActive" 1 "Error" ;
VAL_ 755 BMS_HWerror_KL30_Voltage 0 "ErrorNotActive" 1 "Error" ;
VAL_ 755 BMS_HWerror_SD_Voltage 0 "ErrorNotActive" 1 "Error" ;
VAL_ 755 BMS_HWerror_PCB_Temp_Sensor_Fail 0 "ErrorNotActive" 1 "Error" ;
VAL_ 755 BMS_HWerror_Cell_Temp_Sensor_Fai 0 "ErrorNotActive" 1 "Error" ;
VAL_ 755 BMS_HWwarning_LCM_PCB_OverTemp 0 "WarningNotActive" 1 "Warning" ;
VAL_ 755 BMS_HWerror_LCM_PCB_OverTemp 0 "ErrorNotActive" 1 "Error" ;
VAL_ 755 BMS_HWwarning_LCM_PCB_UnderTemp 0 "WarningNotActive" 1 "Warning" ;
VAL_ 755 BMS_HWerror_LCM_PCB_UnderTemp 0 "ErrorNotActive" 1 "Error" ;
VAL_ 755 BMS_Software_Error_Boot_Faild 0 "ErrorNotActive" 1 "Error" ;
